VERSION ""

NS_ :

 BU_BO_REL_~SG_MUL_VAL_

BS_:

BU_: IAP ODS _4WD BCM HUD DATC MDPS AAF_Tester AEMC SMK _4WD EPB CUBIS MTS TMU EVP CGW TPMS LPI DI_BOX SPAS EMS LCA TCU IBOX FATC AFLS FPCM SCC AHLS AVM ABS SNV OPI PGS SAS AAF Dummy LDWS_LKAS LVR ESC PSB CLU ECS ACU REA CLOCK HUD H_U DATC CCP KMA_TMU CUBIS TMU IPM RSE_R RRC CGW RSE_L AMP EDT SWRC IBOX CLU FHCU ASD MON AVM KBD

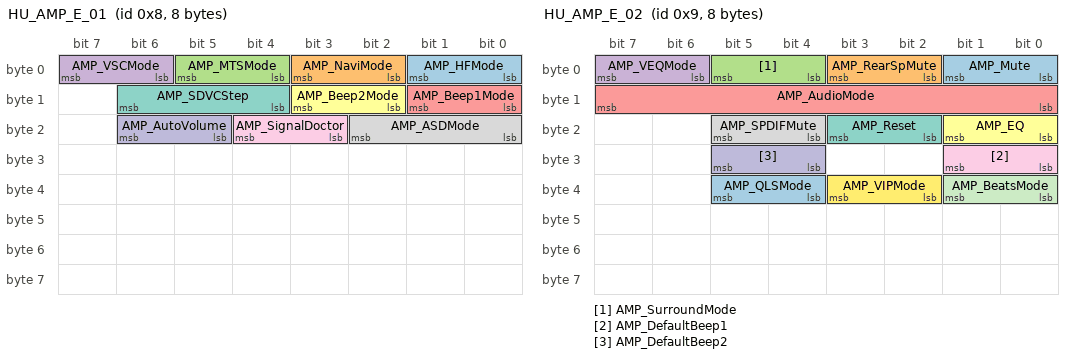
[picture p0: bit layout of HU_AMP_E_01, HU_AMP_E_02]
BO_ 8 HU_AMP_E_01: 8 H_U
   SG_ AMP_HFMode : 1|2@0+ (1,0) [0|0] ""  AMP
   SG_ AMP_NaviMode : 3|2@0+ (1,0) [0|0] ""  AMP
   SG_ AMP_MTSMode : 5|2@0+ (1,0) [0|0] ""  AMP
   SG_ AMP_VSCMode : 7|2@0+ (1,0) [0|0] ""  AMP
   SG_ AMP_Beep1Mode : 9|2@0+ (1,0) [0|0] ""  AMP
   SG_ AMP_Beep2Mode : 11|2@0+ (1,0) [0|0] ""  AMP
   SG_ AMP_SDVCStep : 14|3@0+ (1,0) [0|0] ""  AMP
   SG_ AMP_ASDMode : 18|3@0+ (1,0) [0|0] ""  AMP
   SG_ AMP_SignalDoctor : 20|2@0+ (1,0) [0|0] ""  AMP
   SG_ AMP_AutoVolume : 22|2@0+ (1,0) [0|0] ""  AMP

BO_ 9 HU_AMP_E_02: 8 H_U
   SG_ AMP_Mute : 1|2@0+ (1,0) [0|0] ""  AMP
   SG_ AMP_RearSpMute : 3|2@0+ (1,0) [0|0] ""  AMP
   SG_ AMP_SurroundMode : 5|2@0+ (1,0) [0|0] ""  AMP
   SG_ AMP_VEQMode : 7|2@0+ (1,0) [0|0] ""  AMP
   SG_ AMP_AudioMode : 15|8@0+ (1,0) [0|0] ""  AMP
   SG_ AMP_EQ : 17|2@0+ (1,0) [0|0] ""  AMP
   SG_ AMP_Reset : 19|2@0+ (1,0) [0|0] ""  AMP
   SG_ AMP_SPDIFMute : 21|2@0+ (1,0) [0|0] ""  AMP
   SG_ AMP_DefaultBeep1 : 25|2@0+ (1,0) [0|0] ""  AMP
   SG_ AMP_DefaultBeep2 : 29|2@0+ (1,0) [0|0] ""  AMP
   SG_ AMP_BeatsMode : 33|2@0+ (1,0) [0|0] ""  AMP
   SG_ AMP_VIPMode : 35|2@0+ (1,0) [0|0] ""  AMP
   SG_ AMP_QLSMode : 37|2@0+ (1,0) [0|0] ""  AMP

BO_ 10 HU_AMP_E_03: 8 H_U
   SG_ AMP_CrtVehicleID : 7|8@0+ (1,0) [0|0] ""  AMP
   SG_ AMP_SPDIFMode : 11|4@0+ (1,0) [0|0] ""  AMP
   SG_ AMP_VersionReq : 17|2@0+ (1,0) [0|0] ""  AMP
   SG_ AMP_UpdateStart : 25|2@0+ (1,0) [0|0] ""  AMP
   SG_ AMP_UpdateEnd : 33|2@0+ (1,0) [0|0] ""  AMP

BO_ 11 HU_AMP_E_04: 8 H_U
   SG_ AMP_Drive : 1|2@0+ (1,0) [0|0] ""  AMP
   SG_ AMP_ConvertibleTop : 5|2@0+ (1,0) [0|0] ""  AMP

BO_ 12 HU_AMP_E_05: 8 H_U
   SG_ AMP_NaviVolumeStep : 7|8@0+ (1,0) [0|0] ""  AMP
   SG_ AMP_NaviMainAudioCut : 15|8@0+ (1,0) [0|0] ""  AMP
   SG_ AMP_NaviChannelOutputMask : 23|16@0+ (1,0) [0|0] ""  AMP
   SG_ AMP_NaviChannelMuteMask : 39|16@0+ (1,0) [0|0] ""  AMP

BO_ 13 HU_AMP_E_06: 8 H_U
   SG_ AMP_MTSVolumeStep : 7|8@0+ (1,0) [0|0] ""  AMP
   SG_ AMP_MTSMainAudioCut : 15|8@0+ (1,0) [0|0] ""  AMP
   SG_ AMP_MTSChannelOutputMask : 23|16@0+ (1,0) [0|0] ""  AMP
   SG_ AMP_MTSChannelMuteMask : 39|16@0+ (1,0) [0|0] ""  AMP

BO_ 14 HU_AMP_E_07: 8 H_U
   SG_ AMP_HFVolumeStep : 7|8@0+ (1,0) [0|0] ""  AMP
   SG_ AMP_HFMainAudioCut : 15|8@0+ (1,0) [0|0] ""  AMP
   SG_ AMP_HFChannelOutputMask : 23|16@0+ (1,0) [0|0] ""  AMP
   SG_ AMP_HFChannelMuteMask : 39|16@0+ (1,0) [0|0] ""  AMP

BO_ 15 HU_AMP_E_08: 8 H_U
   SG_ AMP_MainVolumeSet : 7|8@0+ (1,0) [0|0] ""  AMP
   SG_ AMP_BalanceSet : 15|8@0+ (1,0) [0|0] ""  AMP
   SG_ AMP_FadeSet : 23|8@0+ (1,0) [0|0] ""  AMP
   SG_ AMP_BassSet : 31|8@0+ (1,0) [0|0] ""  AMP
   SG_ AMP_MidSet : 39|8@0+ (1,0) [0|0] ""  AMP
   SG_ AMP_TrebleSet : 47|8@0+ (1,0) [0|0] ""  AMP

BO_ 16 ACU13: 8 ACU
   SG_ CF_Acu_CshAct : 0|1@1+ (1.0,0.0) [0.0|1.0] ""  CUBIS,IBOX,ODS

BO_ 17 HU_AMP_E_10: 8 H_U
   SG_ AMP_Beep2VolumeStep : 7|8@0+ (1,0) [0|0] ""  AMP
   SG_ AMP_Beep2Frequency : 15|16@0+ (1,0) [0|0] ""  AMP
   SG_ AMP_Beep2Ch_OutputMask : 31|16@0+ (1,0) [0|0] ""  AMP
   SG_ AMP_Beep2DurationOn : 47|8@0+ (1,0) [0|0] ""  AMP
   SG_ AMP_Beep2DurationOff : 55|8@0+ (1,0) [0|0] ""  AMP
   SG_ AMP_Beep2NumberOfCycles : 63|8@0+ (1,0) [0|0] ""  AMP

BO_ 23 HU_IPM_E_00: 8 H_U
   SG_ C_ADrLNValueSet : 2|3@0+ (1,0) [0|0] ""  DATC,IPM
   SG_ C_ADrUNValueSet : 5|3@0+ (1,0) [0|0] ""  DATC,IPM
   SG_ SYS_Ver_Req : 7|2@0+ (1,0) [0|0] ""  AMP,AVM,CLU,CUBIS,DATC,IPM
   SG_ C_IMSRValueReq : 9|2@0+ (1,0) [0|0] ""  DATC,IPM
   SG_ C_PSMNValueSet : 11|2@0+ (1,0) [0|0] ""  DATC,IPM
   SG_ C_SCMNValueSet : 13|2@0+ (1,0) [0|0] ""  DATC,IPM
   SG_ C_ADrLURValueReq : 15|2@0+ (1,0) [0|0] ""  DATC,IPM
   SG_ C_ABuzzerNValueSet : 17|2@0+ (1,0) [0|0] ""  DATC,IPM
   SG_ C_AlarmRValueReq : 19|2@0+ (1,0) [0|0] ""  DATC,IPM
   SG_ C_ArmWKeyNValueSet : 21|2@0+ (1,0) [0|0] ""  DATC,IPM
   SG_ C_TwUnRValueReq : 23|2@0+ (1,0) [0|0] ""  DATC,IPM
   SG_ C_TwUnNValueSet : 25|2@0+ (1,0) [0|0] ""  DATC,IPM
   SG_ C_AutoMRFoldRValueReq : 27|2@0+ (1,0) [0|0] ""  DATC,IPM
   SG_ C_AutoMRFoldNValueSet : 29|2@0+ (1,0) [0|0] ""  DATC,IPM
   SG_ C_ADrLRValueReq : 31|2@0+ (1,0) [0|0] ""  DATC,IPM
   SG_ C_ArmWKeyRValueReq : 33|2@0+ (1,0) [0|0] ""  DATC,IPM
   SG_ C_ABuzzerRValueReq : 35|2@0+ (1,0) [0|0] ""  DATC,IPM
   SG_ C_ADrURValueReq : 37|2@0+ (1,0) [0|0] ""  DATC,IPM
   SG_ C_PSMRValueReq : 39|2@0+ (1,0) [0|0] ""  DATC,IPM
   SG_ C_SCMRValueReq : 47|2@0+ (1,0) [0|0] ""  DATC,IPM

BO_ 27 AMP_HU_E_00: 8 AMP
   SG_ SYS_AMPVer : 7|16@0+ (1,0) [0|0] ""  H_U

BO_ 29 CLU_HU_E_00: 8 CLU
   SG_ SYS_CLUVer : 7|16@0+ (1,0) [0|0] ""  CUBIS,H_U
   SG_ CLU_ClockInfoReq : 17|2@0+ (1,0) [0|0] ""  H_U
   SG_ CLU_DateInfoReq : 19|2@0+ (1,0) [0|0] ""  H_U

BO_ 48 EMS18: 6 EMS
   SG_ CF_Ems_DC1NumPerMSV : 0|8@1+ (1.0,0.0) [0.0|255.0] ""  DI_BOX
   SG_ CF_Ems_DC2NumPerMSV : 8|16@1+ (1.0,0.0) [0.0|65535.0] ""  DI_BOX
   SG_ CR_Ems_DutyCyc1MSV : 24|8@1+ (0.1953,0.0) [0.0|49.8] "%"  DI_BOX
   SG_ CR_Ems_DutyCyc2MSV : 32|8@1+ (0.13725,0.0) [0.0|35.0] "%"  DI_BOX
   SG_ CR_Ems_DutyCyc3MSV : 40|8@1+ (0.392,0.0) [0.0|100.0] "%"  DI_BOX

BO_ 52 HU_DATC_E_02: 8 H_U
   SG_ HU_DATC_DrTempUpDn : 1|2@0+ (1,0) [0|0] ""  CGW,CLU,DATC,IPM
   SG_ HU_DATC_PsTempUpDn : 3|2@0+ (1,0) [0|0] ""  CGW,CLU,DATC,IPM
   SG_ HU_DATC_RlTempUpDn : 5|2@0+ (1,0) [0|0] ""  CGW,CLU,DATC,IPM
   SG_ HU_DATC_RrTempUpDn : 7|2@0+ (1,0) [0|0] ""  CGW,CLU,DATC,IPM
   SG_ HU_DATC_MainBlower : 11|4@0+ (1,0) [0|0] ""  CGW,CLU,DATC,IPM
   SG_ HU_DATC_SubBlower : 15|4@0+ (1,0) [0|0] ""  CGW,CLU,DATC,IPM
   SG_ HU_DATC_RearBlower : 19|4@0+ (1,0) [0|0] ""  CGW,CLU,DATC,IPM
   SG_ HU_DATCRearPsModeSet : 23|4@0+ (1,0) [0|0] ""  CGW,CLU
   SG_ HU_DATC_FrontModeSet : 27|4@0+ (1,0) [0|0] ""  CGW,CLU,DATC,IPM
   SG_ HU_DATC_RearModeSet : 31|4@0+ (1,0) [0|0] ""  CGW,CLU,DATC,IPM
   SG_ HU_DATC_AutoSet : 33|2@0+ (1,0) [0|0] ""  CGW,CLU,DATC,IPM
   SG_ HU_DATC_OffReq : 35|2@0+ (1,0) [0|0] ""  CGW,CLU,DATC,IPM
   SG_ HU_DATC_IntakeSet : 37|2@0+ (1,0) [0|0] ""  CGW,CLU,DATC,IPM
   SG_ HU_DATC_RearOnOffSet : 39|2@0+ (1,0) [0|0] ""  CGW,CLU,DATC,IPM
   SG_ HU_DATC_AcSet : 41|2@0+ (1,0) [0|0] ""  CGW,CLU,DATC,IPM
   SG_ HU_DATC_AqsSet : 43|2@0+ (1,0) [0|0] ""  CGW,CLU,DATC,IPM
   SG_ HU_DATC_FrontDefog : 45|2@0+ (1,0) [0|0] ""  CGW,CLU,DATC,IPM
   SG_ HU_DATC_RearDefog : 47|2@0+ (1,0) [0|0] ""  CGW,CLU,DATC,IPM
   SG_ HU_DATC_ZoneControl : 49|2@0+ (1,0) [0|0] ""  CGW,CLU,DATC,IPM
   SG_ HU_DATC_CO2Set : 51|2@0+ (1,0) [0|0] ""  CGW,CLU,DATC,IPM
   SG_ DATC_SmartVentOnOffSet : 53|2@0+ (1,0) [0|0] ""  CGW,CLU,DATC,IPM
   SG_ DATC_ADSOnOffSet : 55|2@0+ (1,0) [0|0] ""  CGW,CLU
   SG_ HU_DATC_RearAutoDisp : 57|2@0+ (1,0) [0|0] ""  CGW,CLU
   SG_ HU_DATC_RearOffDisp : 59|2@0+ (1,0) [0|0] ""  CGW,CLU

BO_ 62 HU_Navi_E_00: 8 H_U
   SG_ Navi_SLIF_SpdUnit : 1|2@0+ (1,0) [0|0] ""  CGW,CLU,HUD
   SG_ Navi_SLIF_Frwinfo : 4|3@0+ (1,0) [0|0] ""  CGW,CLU,HUD
   SG_ Navi_SLIF_LinkClass : 7|3@0+ (1,0) [0|0] ""  CGW,CLU,HUD
   SG_ Navi_SLIF_SpdLimit : 15|8@0+ (1,0) [1|254] ""  CGW,CLU,HUD
   SG_ Navi_SLIFMapSource : 29|4@0+ (1,0) [0|8] ""  CGW,CLU,HUD
   SG_ Navi_SLIF_CountryCode : 23|10@0+ (1,0) [0|0] ""  CGW,CLU,HUD

BO_ 64 TMU_HU_E_01: 8 TMU
   SG_ TMU_DisMode : 3|4@0+ (1,0) [0|0] ""  H_U
   SG_ TMU_AudSrcType : 7|4@0+ (1,0) [0|0] ""  CLU,DATC,H_U
   SG_ TMU_AudReqCmd : 9|2@0+ (1,0) [0|0] ""  H_U
   SG_ TMU_LangCmd : 12|3@0+ (1,0) [0|0] ""  H_U
   SG_ TMU_ServReq : 15|3@0+ (1,0) [0|0] ""  H_U
   SG_ TMU_ErrorEvent : 23|8@0+ (1,0) [0|0] ""  H_U
   SG_ TMU_BeepCmd : 25|2@0+ (1,0) [0|0] ""  H_U
   SG_ TMU_eCall : 28|3@0+ (1,0) [0|0] ""  H_U

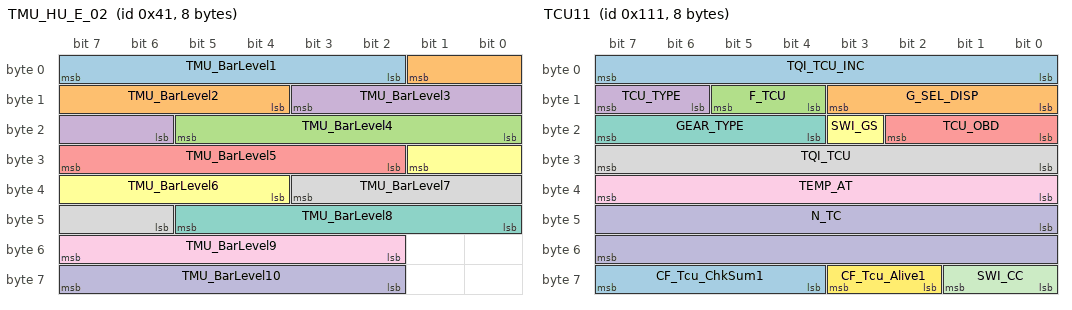
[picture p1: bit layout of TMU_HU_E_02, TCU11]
BO_ 65 TMU_HU_E_02: 8 TMU
   SG_ TMU_BarLevel1 : 7|6@0+ (1,0) [0|0] ""  H_U
   SG_ TMU_BarLevel2 : 1|6@0+ (1,0) [0|0] ""  H_U
   SG_ TMU_BarLevel4 : 21|6@0+ (1,0) [0|0] ""  H_U
   SG_ TMU_BarLevel3 : 11|6@0+ (1,0) [0|0] ""  H_U
   SG_ TMU_BarLevel5 : 31|6@0+ (1,0) [0|0] ""  H_U
   SG_ TMU_BarLevel6 : 25|6@0+ (1,0) [0|0] ""  H_U
   SG_ TMU_BarLevel8 : 45|6@0+ (1,0) [0|0] ""  H_U
   SG_ TMU_BarLevel7 : 35|6@0+ (1,0) [0|0] ""  H_U
   SG_ TMU_BarLevel9 : 55|6@0+ (1,0) [0|0] ""  H_U
   SG_ TMU_BarLevel10 : 63|6@0+ (1,0) [0|0] ""  H_U

BO_ 66 DATC12: 8 DATC
   SG_ CR_Datc_DrTempDispC : 0|8@1+ (0.5,14.0) [15.0|32.0] "deg"  CLU,IBOX
   SG_ CR_Datc_DrTempDispF : 8|8@1+ (1.0,56.0) [58.0|90.0] "deg"  CLU,IBOX
   SG_ CR_Datc_PsTempDispC : 16|8@1+ (0.5,14.0) [15.0|32.0] "deg"  CLU,IBOX
   SG_ CR_Datc_PsTempDispF : 24|8@1+ (1.0,56.0) [58.0|90.0] "deg"  CLU,IBOX
   SG_ CR_Datc_RearDrTempDispC : 40|8@1+ (0.5,14.0) [15.0|32.0] "deg"  CLU
   SG_ CR_Datc_RearDrTempDispF : 48|8@1+ (1.0,58.0) [58.0|90.0] "deg"  CLU
   SG_ CF_Datc_CO2_Warning : 56|8@1+ (1.0,0.0) [0.0|3.0] ""  CLU

BO_ 67 DATC13: 8 DATC
   SG_ CF_Datc_TempDispUnit : 0|2@1+ (1.0,0.0) [0.0|3.0] ""  CLU,IBOX
   SG_ CF_Datc_ModDisp : 2|4@1+ (1.0,0.0) [0.0|15.0] ""  CLU
   SG_ CF_Datc_IonClean : 6|2@1+ (1.0,0.0) [0.0|3.0] ""  CLU
   SG_ CF_Datc_ChgReqDisp : 8|2@1+ (1.0,0.0) [0.0|3.0] ""  CLU
   SG_ CF_Datc_IntakeDisp : 10|2@1+ (1.0,0.0) [0.0|3.0] ""  CLU
   SG_ CF_Datc_AutoDisp : 12|2@1+ (1.0,0.0) [0.0|3.0] ""  CLU
   SG_ CF_Datc_FrDefLed : 14|2@1+ (1.0,0.0) [0.0|3.0] ""  CLU,IBOX
   SG_ CF_Datc_AutoDefogBlink : 16|2@1+ (1.0,0.0) [0.0|3.0] ""  CLU
   SG_ CF_Datc_ClmScanDisp : 18|2@1+ (1.0,0.0) [0.0|3.0] ""  CLU
   SG_ CF_Datc_AqsDisp : 20|2@1+ (1.0,0.0) [0.0|3.0] ""  CLU
   SG_ CF_Datc_AcDisp : 22|2@1+ (1.0,0.0) [0.0|3.0] ""  CLU
   SG_ CF_Datc_OpSts : 25|3@1+ (1.0,0.0) [0.0|7.0] ""  CLU
   SG_ CF_Mtc_MaxAcDisp : 28|2@1+ (1.0,0.0) [0.0|3.0] ""  CLU
   SG_ CF_Datc_DualDisp : 30|2@1+ (1.0,0.0) [0.0|3.0] ""  CLU
   SG_ CF_Datc_PwrInf : 32|4@1+ (1.0,0.0) [0.0|15.0] ""  CLU
   SG_ CF_Datc_RearManual : 38|2@1+ (1.0,0.0) [0.0|3.0] ""  CLU
   SG_ CF_Datc_RearAutoDisp : 40|2@1+ (1.0,0.0) [0.0|1.0] ""  CLU
   SG_ CF_Datc_RearOffDisp : 42|2@1+ (1.0,0.0) [0.0|3.0] ""  CLU
   SG_ CF_Datc_RearClimateScnDisp : 44|2@1+ (1.0,0.0) [0.0|3.0] ""  CLU
   SG_ CF_Datc_RearChgReqDisp : 46|2@1+ (1.0,0.0) [0.0|3.0] ""  CLU
   SG_ CF_Datc_RearModDisp : 48|4@1+ (1.0,0.0) [0.0|15.0] ""  CLU
   SG_ CF_Datc_RearBlwDisp : 52|4@1+ (1.0,0.0) [0.0|15.0] ""  CLU
   SG_ CF_Datc_PSModDisp : 56|4@1+ (1.0,0.0) [0.0|15.0] ""  CLU
   SG_ CF_Datc_FrontBlwDisp : 60|4@1+ (1.0,0.0) [0.0|15.0] ""  CLU,IBOX

BO_ 68 DATC11: 8 DATC
   SG_ CF_Datc_Type : 0|8@1+ (1.0,0.0) [0.0|255.0] ""  CLU
   SG_ CF_Datc_VerMaj : 8|8@1+ (1.0,0.0) [0.0|255.0] ""  CLU
   SG_ CF_Datc_VerMin : 16|8@1+ (1.0,0.0) [0.0|255.0] ""  CLU
   SG_ CR_Datc_OutTempC : 24|8@1+ (0.5,-41.0) [-41.0|86.5] "deg"  CLU,FPCM
   SG_ CR_Datc_OutTempF : 32|8@1+ (1.0,-42.0) [-42.0|213.0] "deg"  CLU
   SG_ CF_Datc_IncarTemp : 40|8@1+ (0.5,-40.0) [-40.0|60.0] "deg"  BCM,CLU

BO_ 69 TMU_HU_E_04: 8 TMU
   SG_ TMU_eCall : 1|2@0+ (1,0) [0|0] ""  H_U

BO_ 74 HU_AMP_E_11: 8 H_U
   SG_ AMP_PESSMode : 1|2@0+ (1,0) [0|0] ""  AMP
   SG_ AMP_PESSDesignSet : 4|3@0+ (1,0) [0|0] ""  AMP
   SG_ AMP_PESSAPSSet : 7|3@0+ (1,0) [0|0] ""  AMP
   SG_ AMP_PESSVolumeSet : 15|8@0+ (1,0) [0|0] ""  AMP

BO_ 75 HU_AMP_E_12: 8 H_U
   SG_ AMP_EngOrderC2GainSet : 7|8@0+ (1,0) [0|0] ""  AMP
   SG_ AMP_EngOrderC4GainSet : 15|8@0+ (1,0) [0|0] ""  AMP
   SG_ AMP_EngOrderC6GainSet : 23|8@0+ (1,0) [0|0] ""  AMP
   SG_ AMP_APSBand0GainSet : 31|8@0+ (1,0) [0|0] ""  AMP
   SG_ AMP_APSBand1GainSet : 39|8@0+ (1,0) [0|0] ""  AMP
   SG_ AMP_APSBand2GainSet : 47|8@0+ (1,0) [0|0] ""  AMP
   SG_ AMP_APSBand3GainSet : 55|8@0+ (1,0) [0|0] ""  AMP
   SG_ AMP_APSBand4GainSet : 63|8@0+ (1,0) [0|0] ""  AMP

BO_ 87 HU_E_02: 8 H_U
   SG_ NaviValidity : 1|2@0+ (1,0) [0|0] ""  CGW,CLU

BO_ 93 DATC_HU_E_SYS: 8 CLU
   SG_ DATC_SWVerMajor : 7|8@0+ (1,0) [0|254] ""  H_U
   SG_ DATC_SWVerMinor : 15|8@0+ (1,0) [0|254] ""  H_U
   SG_ DATC_CANVerMajor : 23|8@0+ (1,0) [0|254] ""  H_U
   SG_ DATC_CANVerMinor : 31|8@0+ (1,0) [0|254] ""  H_U

BO_ 112 HU_AMP_E_09: 8 H_U
   SG_ AMP_Beep1VolumeStep : 7|8@0+ (1,0) [0|0] ""  AMP
   SG_ AMP_Beep1Frequency : 15|16@0+ (1,0) [0|0] ""  AMP
   SG_ AMP_Beep1Ch_OutputMask : 31|16@0+ (1,0) [0|0] ""  AMP
   SG_ AMP_Beep1DurationOn : 47|8@0+ (1,0) [0|0] ""  AMP
   SG_ AMP_Beep1DurationOff : 55|8@0+ (1,0) [0|0] ""  AMP
   SG_ AMP_Beep1NumberOfCycles : 63|8@0+ (1,0) [0|0] ""  AMP

BO_ 127 CGW5: 8 BCM
   SG_ C_StopLampLhOpenSts : 0|1@1+ (1.0,0.0) [0.0|1.0] ""  CLU
   SG_ C_StopLampRhOpenSts : 1|1@1+ (1.0,0.0) [0.0|1.0] ""  CLU
   SG_ C_HMSLOpenSts : 2|1@1+ (1.0,0.0) [0.0|1.0] ""  CLU
   SG_ C_HLampLowLhOpenSts : 3|1@1+ (1.0,0.0) [0.0|1.0] ""  CLU
   SG_ C_HLampLowRhOpenSts : 4|1@1+ (1.0,0.0) [0.0|1.0] ""  CLU
   SG_ C_HLampHighLhOpenSts : 5|1@1+ (1.0,0.0) [0.0|1.0] ""  CLU
   SG_ C_HLampHighRhOpenSts : 6|1@1+ (1.0,0.0) [0.0|1.0] ""  CLU
   SG_ C_DRLLampLhOpenSts : 7|1@1+ (1.0,0.0) [0.0|1.0] ""  CLU
   SG_ C_DRLLampRhOpenSts : 8|1@1+ (1.0,0.0) [0.0|1.0] ""  CLU
   SG_ C_RearFOGLhOpenSts : 9|1@1+ (1.0,0.0) [0.0|1.0] ""  CLU
   SG_ C_RearFOGRhOpenSts : 10|1@1+ (1.0,0.0) [0.0|1.0] ""  CLU
   SG_ C_FrontFOGLhOpenSts : 11|1@1+ (1.0,0.0) [0.0|1.0] ""  CLU
   SG_ C_FrontFOGRhOpenSts : 12|1@1+ (1.0,0.0) [0.0|1.0] ""  CLU
   SG_ C_RearEXTTailLhOpenSts : 13|1@1+ (1.0,0.0) [0.0|1.0] ""  CLU
   SG_ C_RearEXTTailRhOpenSts : 14|1@1+ (1.0,0.0) [0.0|1.0] ""  CLU
   SG_ C_FrontEXTTailLhOpenSts : 15|1@1+ (1.0,0.0) [0.0|1.0] ""  CLU
   SG_ C_FrontEXTTailRhOpenSts : 16|1@1+ (1.0,0.0) [0.0|1.0] ""  CLU
   SG_ C_RearTSIGLhOpenSts : 17|1@1+ (1.0,0.0) [0.0|1.0] ""  CLU
   SG_ C_RearTSIGRhOpenSts : 18|1@1+ (1.0,0.0) [0.0|1.0] ""  CLU
   SG_ C_FrontTSIGLhOpenSts : 19|1@1+ (1.0,0.0) [0.0|1.0] ""  CLU
   SG_ C_FrontTSIGRhOpenSts : 20|1@1+ (1.0,0.0) [0.0|1.0] ""  CLU
   SG_ C_SBendingLhOpenSts : 21|1@1+ (1.0,0.0) [0.0|1.0] ""  CLU
   SG_ C_SBendingRhOpenSts : 22|1@1+ (1.0,0.0) [0.0|1.0] ""  CLU
   SG_ C_LicensePlateLhOpenSts : 23|1@1+ (1.0,0.0) [0.0|1.0] ""  CLU
   SG_ C_LicensePlateRhOpenSts : 24|1@1+ (1.0,0.0) [0.0|1.0] ""  CLU

BO_ 128 EMS_DCT11: 8 EMS
   SG_ PV_AV_CAN : 0|8@1+ (0.3906,0.0) [0.0|99.603] "%"  TCU
   SG_ TQ_STND : 8|6@1+ (10.0,0.0) [0.0|630.0] "Nm"  TCU
   SG_ F_N_ENG : 14|1@1+ (1.0,0.0) [0.0|1.0] ""  TCU
   SG_ F_SUB_TQI : 15|1@1+ (1.0,0.0) [0.0|1.0] ""  TCU
   SG_ N : 16|16@1+ (0.25,0.0) [0.0|16383.75] "rpm"  TCU
   SG_ TQI_ACOR : 32|8@1+ (0.390625,0.0) [0.0|99.6094] "%"  IBOX,TCU
   SG_ TQFR : 40|8@1+ (0.390625,0.0) [0.0|99.6094] "%"  TCU
   SG_ TQI : 48|8@1+ (0.390625,0.0) [0.0|99.609375] "%"  TCU
   SG_ CF_Ems_Alive : 56|4@1+ (1.0,0.0) [0.0|15.0] ""  TCU
   SG_ CF_Ems_ChkSum : 60|4@1+ (1.0,0.0) [0.0|15.0] ""  TCU

BO_ 129 AMP_HU_E_02: 8 AMP
   SG_ AMP_DriveState : 1|2@0+ (1,0) [0|0] ""  H_U
   SG_ AMP_ConvertibleTopState : 5|2@0+ (1,0) [0|0] ""  H_U

BO_ 129 EMS_DCT2: 8 XXX
   SG_ CR_Ems_SoakTimeExt : 0|6@1+ (5,0) [0|315] "Min" XXX
   SG_ BRAKE_ACT : 6|2@1+ (1,0) [0|3] "" XXX
   SG_ CF_Ems_EngOperStat : 8|8@1+ (1,0) [0|255] "" XXX
   SG_ CR_Ems_IndAirTemp : 16|8@1+ (0.75,-48) [-48|143.25] "" XXX
   SG_ CF_Ems_Alive2 : 56|4@1+ (1,0) [0|15] "" XXX
   SG_ CF_Ems_ChkSum2 : 60|4@1+ (1,0) [0|15] "" XXX

BO_ 129 EMS_DCT12: 8 EMS
   SG_ CR_Ems_SoakTimeExt : 0|6@1+ (5.0,0.0) [0.0|315.0] "Min"  TCU
   SG_ BRAKE_ACT : 6|2@1+ (1.0,0.0) [0.0|3.0] ""  TCU
   SG_ CF_Ems_EngOperStat : 8|8@1+ (1.0,0.0) [0.0|255.0] ""  TCU
   SG_ CR_Ems_IndAirTemp : 16|8@1+ (0.75,-48.0) [-48.0|143.25] "deg"  TCU
   SG_ CF_Ems_Alive2 : 56|4@1+ (1.0,0.0) [0.0|15.0] ""  TCU
   SG_ CF_Ems_ChkSum2 : 60|4@1+ (1.0,0.0) [0.0|15.0] ""  TCU

BO_ 130 AMP_HU_E_03: 8 AMP
   SG_ AMP_NaviVolumeState : 7|8@0+ (1,0) [0|0] ""  H_U
   SG_ AMP_NaviAudioCutState : 15|8@0+ (1,0) [0|0] ""  H_U
   SG_ AMP_NaviOutputMaskState : 23|16@0+ (1,0) [0|0] ""  H_U
   SG_ AMP_NaviMuteMaskState : 39|16@0+ (1,0) [0|0] ""  H_U
   SG_ AMP_MaxNaviVolumeState : 55|8@0+ (1,0) [0|0] ""  H_U
   SG_ AMP_MaxNaviAudioCutState : 63|8@0+ (1,0) [0|0] ""  H_U

BO_ 131 AMP_HU_E_04: 8 AMP
   SG_ AMP_MTSVolumeState : 7|8@0+ (1,0) [0|0] ""  H_U
   SG_ AMP_MTSAudioCutState : 15|8@0+ (1,0) [0|0] ""  H_U
   SG_ AMP_MTSOutputMaskState : 23|16@0+ (1,0) [0|0] ""  H_U
   SG_ AMP_MTSMuteMaskState : 39|16@0+ (1,0) [0|0] ""  H_U
   SG_ AMP_MaxMTSVolumeState : 55|8@0+ (1,0) [0|0] ""  H_U
   SG_ AMP_MaxMTSAudioCutState : 63|8@0+ (1,0) [0|0] ""  H_U

BO_ 132 AMP_HU_E_05: 8 AMP
   SG_ AMP_HFVolumeState : 7|8@0+ (1,0) [0|0] ""  H_U
   SG_ AMP_HFAudioCutState : 15|8@0+ (1,0) [0|0] ""  H_U
   SG_ AMP_HFOutputMaskState : 23|16@0+ (1,0) [0|0] ""  H_U
   SG_ AMP_HFMuteMaskState : 39|16@0+ (1,0) [0|0] ""  H_U
   SG_ AMP_MaxHFVolumeState : 55|8@0+ (1,0) [0|0] ""  H_U
   SG_ AMP_MaxHFAudioCutState : 63|8@0+ (1,0) [0|0] ""  H_U

BO_ 133 AMP_HU_E_06: 8 AMP
   SG_ AMP_MaxVolumeStep : 7|8@0+ (1,0) [0|0] ""  H_U
   SG_ AMP_MaxBalanceStep : 15|8@0+ (1,0) [0|0] ""  H_U
   SG_ AMP_MaxFadeStep : 23|8@0+ (1,0) [0|0] ""  H_U
   SG_ AMP_MaxBassStep : 31|8@0+ (1,0) [0|0] ""  H_U
   SG_ AMP_MaxMidStep : 39|8@0+ (1,0) [0|0] ""  H_U
   SG_ AMP_MaxTrebleStep : 47|8@0+ (1,0) [0|0] ""  H_U
   SG_ AMP_ASDMajorVer : 55|8@0+ (1,0) [0|0] ""  H_U
   SG_ AMP_ASDMinorVer : 63|8@0+ (1,0) [0|0] ""  H_U

BO_ 134 AMP_HU_E_07: 8 AMP
   SG_ ASD_SetValue : 2|3@0+ (1,0) [0|0] ""  H_U,IBOX
   SG_ ASD_Version : 15|8@0+ (1,0) [0|0] ""  H_U,IBOX

BO_ 135 AMP_HU_E_08: 8 AMP
   SG_ AMP_MaxBeep1VolumeState : 7|8@0+ (1,0) [0|0] ""  H_U
   SG_ AMP_MaxBeep1Freq_State : 15|16@0+ (1,0) [0|0] ""  H_U
   SG_ AMP_Beep1OutputMaskSup : 33|2@0+ (1,0) [0|0] ""  H_U
   SG_ AMP_MaxBeep1DOnState : 47|8@0+ (1,0) [0|0] ""  H_U
   SG_ AMP_MaxBeep1DOffState : 55|8@0+ (1,0) [0|0] ""  H_U
   SG_ AMP_MaxBeep1NOfCycleState : 63|8@0+ (1,0) [0|0] ""  H_U

BO_ 136 AMP_HU_E_09: 8 AMP
   SG_ AMP_MaxBeep2VolumeState : 7|8@0+ (1,0) [0|0] ""  H_U
   SG_ AMP_MaxBeep2Freq_State : 15|16@0+ (1,0) [0|0] ""  H_U
   SG_ AMP_Beep2OutputMaskSup : 33|2@0+ (1,0) [0|0] ""  H_U
   SG_ AMP_MaxBeep2DOnState : 47|8@0+ (1,0) [0|0] ""  H_U
   SG_ AMP_MaxBeep2DOffState : 55|8@0+ (1,0) [0|0] ""  H_U
   SG_ AMP_MaxBeep2NOfCycleState : 63|8@0+ (1,0) [0|0] ""  H_U

BO_ 137 AMP_HU_E_10: 8 AMP
   SG_ AMP_MTSOutputMaskSupport : 1|2@0+ (1,0) [0|0] ""  H_U
   SG_ AMP_MTSMuteMaskSupport : 5|2@0+ (1,0) [0|0] ""  H_U
   SG_ AMP_HFOutputMaskSupport : 9|2@0+ (1,0) [0|0] ""  H_U
   SG_ AMP_HFMuteMaskSupport : 13|2@0+ (1,0) [0|0] ""  H_U
   SG_ AMP_NaviOutputMaskSupport : 17|2@0+ (1,0) [0|0] ""  H_U
   SG_ AMP_NaviMuteMaskSupport : 21|2@0+ (1,0) [0|0] ""  H_U

BO_ 138 AMP_HU_E_11: 8 AMP
   SG_ AMP_Beep1VolumeState : 7|8@0+ (1,0) [0|0] ""  H_U
   SG_ AMP_Beep1FrequencyState : 15|16@0+ (1,0) [0|0] ""  H_U
   SG_ AMP_Beep1OutputMaskState : 31|16@0+ (1,0) [0|0] ""  H_U
   SG_ AMP_Beep1DOnState : 47|8@0+ (1,0) [0|0] ""  H_U
   SG_ AMP_Beep1DOffState : 55|8@0+ (1,0) [0|0] ""  H_U
   SG_ AMP_Beep1NOfCycleState : 63|8@0+ (1,0) [0|0] ""  H_U

BO_ 139 AMP_HU_E_12: 8 AMP
   SG_ AMP_Beep2VolumeState : 7|8@0+ (1,0) [0|0] ""  H_U
   SG_ AMP_Beep2FrequencyState : 15|16@0+ (1,0) [0|0] ""  H_U
   SG_ AMP_Beep2OutputMaskState : 31|16@0+ (1,0) [0|0] ""  H_U
   SG_ AMP_Beep2DOnState : 47|8@0+ (1,0) [0|0] ""  H_U
   SG_ AMP_Beep2DOffState : 55|8@0+ (1,0) [0|0] ""  H_U
   SG_ AMP_Beep2NOfCycleState : 63|8@0+ (1,0) [0|0] ""  H_U

BO_ 160 EngFrzFrm1: 8 XXX
   SG_ PID_04h : 0|8@1+ (0.392157,0) [0|100] "%" XXX
   SG_ PID_05h : 8|8@1+ (1,-40) [-40|215] "" XXX
   SG_ PID_0Ch : 16|16@1+ (0.25,0) [0|16383.8] "rpm" XXX
   SG_ PID_0Dh : 32|8@1+ (1,0) [0|255] "km/h" XXX
   SG_ PID_11h : 40|8@1+ (0.392157,0) [0|100] "%" XXX
   SG_ PID_03h : 48|16@1+ (1,0) [0|65535] "" XXX

BO_ 161 EngFrzFrm2: 8 XXX
   SG_ PID_06h : 0|8@1+ (0.78125,-100) [-100|99.22] "%" XXX
   SG_ PID_07h : 8|8@1+ (0.78125,-100) [-100|99.22] "%" XXX
   SG_ PID_08h : 16|8@1+ (0.78125,-100) [-100|99.22] "%" XXX
   SG_ PID_09h : 24|8@1+ (0.78125,-100) [-100|99.22] "%" XXX
   SG_ PID_0Bh : 32|8@1+ (1,0) [0|255] "kPa" XXX
   SG_ PID_23h : 40|16@1+ (10,0) [0|655350] "kPa" XXX

BO_ 208 CLU_HU_E_SYS: 8 CLU
   SG_ CLU_SWVerMajor : 7|8@0+ (1,0) [0|254] ""  H_U
   SG_ CLU_SWVerMinor : 15|8@0+ (1,0) [0|254] ""  H_U
   SG_ CLU_CANVerMajor : 23|8@0+ (1,0) [0|254] ""  H_U
   SG_ CLU_CANVerMinor : 31|8@0+ (1,0) [0|254] ""  H_U
   SG_ CLU_HWVerMajor : 55|8@0+ (1,0) [0|254] ""  H_U
   SG_ CLU_HWVerMinor : 63|8@0+ (1,0) [0|254] ""  H_U

BO_ 214 AMP_HU_E_SYS: 8 AMP
   SG_ AMP_SWVerMajor : 7|8@0+ (1,0) [0|254] ""  H_U,IBOX
   SG_ AMP_SWVerMinor : 15|8@0+ (1,0) [0|254] ""  H_U,IBOX
   SG_ AMP_CANVerMajor : 23|8@0+ (1,0) [0|254] ""  H_U,IBOX
   SG_ AMP_CANVerMinor : 31|8@0+ (1,0) [0|254] ""  H_U,IBOX
   SG_ AMP_RBDResult : 34|3@0+ (1,0) [0|0] ""  H_U
   SG_ AMP_MOSTErrorDiagResult : 38|3@0+ (1,0) [0|0] ""  H_U
   SG_ AMP_HWVerMajor : 55|8@0+ (1,0) [0|254] ""  H_U,IBOX
   SG_ AMP_HWVerMinor : 63|8@0+ (1,0) [0|254] ""  H_U,IBOX

BO_ 229 HU_SYS_E_00: 8 H_U
   SG_ SYS_SW_Ver_Req : 1|2@0+ (1,0) [0|0] ""  AMP,CCP,CGW,CLOCK,CLU,HUD,IBOX,RRC,RSE_L
   SG_ SYS_CAN_Ver_Req : 3|2@0+ (1,0) [0|0] ""  AMP,CCP,CGW,CLOCK,CLU,HUD,IBOX,RRC,RSE_L
   SG_ SYS_HW_Ver_Req : 5|2@0+ (1,0) [0|0] ""  AMP,CCP,CGW,CLOCK,CLU,IBOX,RRC
   SG_ SYS_RBD_Req : 9|2@0+ (1,0) [0|0] ""  AMP,IBOX
   SG_ SYS_MOSTErrorDiag_Req : 11|2@0+ (1,0) [0|0] ""  AMP,IBOX
   SG_ SYS_Reset_Req : 17|2@0+ (1,0) [0|0] ""  AMP,IBOX

BO_ 250 HU_TMU_E_01: 8 H_U
   SG_ HU_VoiceRecCom : 2|3@0+ (1,0) [0|0] ""  TMU
   SG_ HU_LangChgCom : 5|3@0+ (1,0) [0|0] ""  TMU
   SG_ HU_CallEndCmd : 9|2@0+ (1,0) [0|0] ""  TMU
   SG_ HU_ServiceReqtID : 13|4@0+ (1,0) [0|0] ""  TMU
   SG_ HU_MicReqCmd : 15|2@0+ (1,0) [0|0] ""  TMU
   SG_ HU_SeviceAction : 18|3@0+ (1,0) [0|0] ""  TMU
   SG_ HU_eCallStatus : 20|2@0+ (1,0) [0|0] ""  TMU

BO_ 251 HU_TMU_E_02: 8 H_U
   SG_ HU_GPS_Year : 7|8@0+ (1,0) [0|0] ""  CUBIS,TMU
   SG_ HU_GPS_Month : 15|8@0+ (1,0) [0|0] ""  CUBIS,TMU
   SG_ HU_GPS_Day : 23|8@0+ (1,0) [0|0] ""  CUBIS,TMU
   SG_ HU_GPS_Hour : 31|8@0+ (1,0) [0|0] ""  CUBIS,TMU
   SG_ HU_GPS_Minute : 39|8@0+ (1,0) [0|0] ""  CUBIS,TMU
   SG_ HU_GPS_Second : 47|8@0+ (1,0) [0|0] ""  CUBIS,TMU

BO_ 256 HU_MON_PE_01: 8 H_U
   SG_ HU_Type : 7|8@0+ (1,0) [0|0] ""  AMP,CGW,CLU,HUD,KMA_TMU
   SG_ HU_VerMajor : 15|8@0+ (1,0) [0|0] ""  AMP,CLU,KMA_TMU,MON
   SG_ HU_VerMinor : 23|8@0+ (1,0) [0|0] ""  AMP,CLU,KMA_TMU,MON
   SG_ HU_DistributeInfo : 31|8@0+ (1,0) [0|0] ""  AMP,CGW,CLU,KMA_TMU,MON,RRC
   SG_ HU_SubVerMajor : 39|8@0+ (1,0) [0|0] ""  AMP,MON
   SG_ HU_SubVerMinor : 47|8@0+ (1,0) [0|0] ""  AMP,MON
   SG_ HU_SDARSVersion : 55|8@0+ (1,0) [0|0] ""  AMP,MON
   SG_ HU_AdasSupport : 58|3@0+ (1,0) [0|0] ""  CGW,CLU

BO_ 273 TCU11: 8 TCU
   SG_ TQI_TCU_INC : 0|8@1+ (0.390625,0.0) [0.0|99.609375] "%"  EMS,ESC,IBOX
   SG_ G_SEL_DISP : 8|4@1+ (1.0,0.0) [0.0|15.0] ""  _4WD,AFLS,AVM,BCM,CGW,CLU,CUBIS,ECS,EMS,EPB,ESC,IAP,IBOX,LCA,LDWS_LKAS,LVR,MDPS,PGS,SCC,SMK,SNV,SPAS,TPMS
   SG_ F_TCU : 12|2@1+ (1.0,0.0) [0.0|3.0] ""  EMS,ESC,IBOX
   SG_ TCU_TYPE : 14|2@1+ (1.0,0.0) [0.0|3.0] ""  _4WD,EMS,ESC,IBOX
   SG_ TCU_OBD : 16|3@1+ (1.0,0.0) [0.0|7.0] ""  EMS,ESC,IBOX
   SG_ SWI_GS : 19|1@1+ (1.0,0.0) [0.0|1.0] ""  _4WD,EMS,EPB,ESC,IBOX,SCC
   SG_ GEAR_TYPE : 20|4@1+ (1.0,0.0) [0.0|15.0] ""  _4WD,CLU,EMS,ESC,IBOX,SCC
   SG_ TQI_TCU : 24|8@1+ (0.390625,0.0) [0.0|99.609375] "%"  EMS,ESC,IBOX
   SG_ TEMP_AT : 32|8@1+ (1.0,-40.0) [-40.0|214.0] "deg"  AAF,CLU,CUBIS,EMS,ESC,IBOX
   SG_ N_TC : 40|16@1+ (0.25,0.0) [0.0|16383.5] "rpm"  _4WD,EMS,EPB,ESC,IBOX
   SG_ SWI_CC : 56|2@1+ (1.0,0.0) [0.0|3.0] ""  _4WD,CLU,EMS,ESC,IBOX
   SG_ CF_Tcu_Alive1 : 58|2@1+ (1.0,0.0) [0.0|3.0] ""  EMS,IBOX
   SG_ CF_Tcu_ChkSum1 : 60|4@1+ (1.0,0.0) [0.0|15.0] ""  EMS,IBOX

BO_ 274 TCU12: 8 TCU
   SG_ ETL_TCU : 0|8@1+ (2.0,0.0) [0.0|508.0] "Nm"  EMS,IBOX
   SG_ CUR_GR : 8|4@1+ (1.0,0.0) [0.0|15.0] ""  _4WD,EMS,ESC,IBOX,SCC,TPMS
   SG_ CF_Tcu_Alive : 12|2@1+ (1.0,0.0) [0.0|3.0] ""  EMS,ESC,IBOX,SCC
   SG_ CF_Tcu_ChkSum : 14|2@1+ (1.0,0.0) [0.0|3.0] ""  EMS,ESC,IBOX,SCC
   SG_ VS_TCU : 16|8@1+ (1.0,0.0) [0.0|254.0] "km/h"  BCM,CLU,DATC,EMS,IBOX,LCA,LVR,PGS,SMK,SNV
   SG_ FUEL_CUT_TCU : 28|1@1+ (1.0,0.0) [0.0|1.0] ""  EMS,IBOX
   SG_ INH_FUEL_CUT : 29|1@1+ (1.0,0.0) [0.0|1.0] ""  EMS,IBOX
   SG_ IDLE_UP_TCU : 30|1@1+ (1.0,0.0) [0.0|1.0] ""  EMS,IBOX
   SG_ N_INC_TCU : 31|1@1+ (1.0,0.0) [0.0|1.0] ""  EMS,IBOX
   SG_ SPK_RTD_TCU : 32|8@1+ (0.375,-23.625) [-15.0|15.0] ""  EMS,IBOX
   SG_ N_TC_RAW : 40|16@1+ (0.25,0.0) [0.0|16383.5] "rpm"  EMS,IBOX
   SG_ VS_TCU_DECIMAL : 56|8@1+ (0.0078125,0.0) [0.0|0.9921875] "km/h"  CLU,EMS,IBOX,LCA

BO_ 275 TCU13: 8 TCU
   SG_ N_TGT_LUP : 0|8@1+ (10.0,500.0) [500.0|3040.0] "rpm"  EMS,IBOX
   SG_ SLOPE_TCU : 8|6@1+ (0.5,-16.0) [-16.0|15.5] "%"  CLU,CUBIS,EMS,IBOX
   SG_ CF_Tcu_InhCda : 14|1@1+ (1.0,0.0) [0.0|1.0] ""  EMS,IBOX
   SG_ CF_Tcu_IsgInhib : 15|1@1+ (1.0,0.0) [0.0|1.0] ""  EMS,IBOX
   SG_ CF_Tcu_BkeOnReq : 16|2@1+ (1.0,0.0) [0.0|3.0] ""  EMS,IBOX
   SG_ CF_Tcu_NCStat : 18|2@1+ (1.0,0.0) [0.0|3.0] ""  EMS,IBOX
   SG_ CF_Tcu_TarGr : 20|4@1+ (1.0,0.0) [0.0|15.0] ""  _4WD,CLU,DATC,EMS,EPB,ESC,IBOX,SCC
   SG_ CF_Tcu_ShfPatt : 24|4@1+ (1.0,0.0) [0.0|15.0] ""  CLU,CUBIS,EMS,IBOX
   SG_ CF_Tcu_InhVis : 28|1@1+ (1.0,0.0) [0.0|1.0] ""  EMS,IBOX
   SG_ CF_Tcu_PRelReq : 29|1@1+ (1.0,0.0) [0.0|1.0] ""  IBOX,LVR
   SG_ CF_Tcu_ITPhase : 30|1@1+ (1.0,0.0) [0.0|1.0] ""  EMS,IBOX
   SG_ CF_Tcu_ActEcoRdy : 31|1@1+ (1.0,0.0) [0.0|1.0] ""  EMS,IBOX
   SG_ CF_Tcu_TqGrdLim : 32|8@1+ (10.0,0.0) [0.0|2540.0] "Nm/s"  EMS,IBOX
   SG_ CR_Tcu_IsgTgtRPM : 40|8@1+ (20.0,0.0) [0.0|3500.0] "rpm"  EMS,IBOX
   SG_ CF_Tcu_SptRdy : 48|1@1+ (1.0,0.0) [0.0|1.0] ""  CLU,IBOX
   SG_ CF_Tcu_SbwPInfo : 56|1@1+ (1.0,0.0) [0.0|1.0] ""  EMS,IBOX
   SG_ CF_Tcu_Alive3 : 58|2@1+ (1.0,0.0) [0.0|3.0] ""  EMS,IBOX
   SG_ CF_Tcu_ChkSum3 : 60|4@1+ (1.0,0.0) [0.0|15.0] ""  EMS,IBOX

BO_ 276 HU_CLU_PE_01: 8 H_U
   SG_ HU_OpState : 6|7@0+ (1,0) [0|0] ""  AMP,CLU
   SG_ HU_Navi_On_Off : 7|1@0+ (1,0) [0|0] ""  CLU,HUD
   SG_ HU_Preset_Number : 12|5@0+ (1,1) [1|30] ""  AMP,CLU
   SG_ HU_Tuner_Area : 15|3@0+ (1,0) [0|0] ""  AMP,CLU
   SG_ HU_Track_Number : 23|16@0+ (1,0) [0|0] ""  CLU
   SG_ HU_Play_time_Sec : 39|6@0+ (1,0) [0|0] ""  CLU
   SG_ HU_Play_time_Min : 33|7@0+ (1,0) [0|0] ""  CLU
   SG_ HU_Play_time_Hour : 42|6@0+ (1,0) [0|0] ""  CLU
   SG_ HU_Disc_select_No : 59|4@0+ (1,0) [0|0] ""  CLU
   SG_ HU_Frequency : 52|9@0+ (1,0) [0|0] ""  AMP,CLU

BO_ 277 HU_CLU_PE_02: 8 H_U
   SG_ TBT_Display_Type : 7|8@0+ (1,0) [0|0] ""  CLU,HUD
   SG_ TBT_Side_Street : 15|16@0+ (1,0) [0|0] ""  CLU,HUD
   SG_ TBT_Direction : 31|8@0+ (1,0) [0|0] ""  CLU,HUD
   SG_ TBT_Distance_Turn_Point : 39|16@0+ (1,0) [0|0] "m"  CLU,HUD
   SG_ TBT_Combined_Side_Street : 51|4@0+ (1,0) [0|0] ""  CLU,HUD
   SG_ TBT_Scale : 55|4@0+ (1,0) [0|0] ""  CLU,HUD
   SG_ TBT_DistancetoTurnPoint : 59|4@0+ (1,0) [0|0] "times"  CLU,HUD
   SG_ TBT_Bar_Graph_Level : 63|4@0+ (10,0) [0|100] ""  CLU,HUD

BO_ 286 HU_CLU_PE_10: 8 H_U
   SG_ Navi_TBTInfo : 63|8@0+ (1,0) [0|0] ""  CGW,CLU

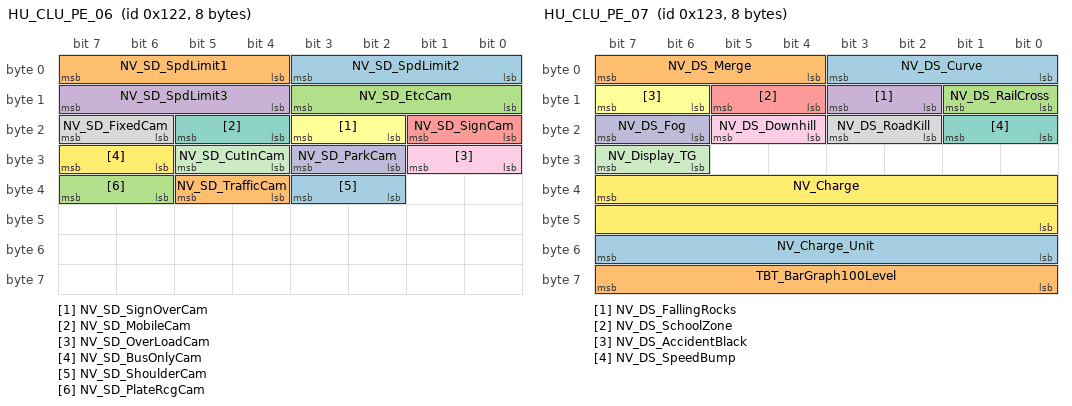
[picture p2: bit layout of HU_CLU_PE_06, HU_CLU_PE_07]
BO_ 290 HU_CLU_PE_06: 8 H_U
   SG_ NV_SD_SpdLimit2 : 3|4@0+ (10,0) [0|0] "km/h"  CLU
   SG_ NV_SD_SpdLimit1 : 7|4@0+ (10,0) [0|0] "km/h"  CLU
   SG_ NV_SD_EtcCam : 11|4@0+ (1,0) [0|0] ""  CLU
   SG_ NV_SD_SpdLimit3 : 15|4@0+ (10,0) [0|0] "km/h"  CLU
   SG_ NV_SD_SignCam : 17|2@0+ (1,0) [0|0] ""  CLU
   SG_ NV_SD_SignOverCam : 19|2@0+ (1,0) [0|0] ""  CLU
   SG_ NV_SD_MobileCam : 21|2@0+ (1,0) [0|0] ""  CLU
   SG_ NV_SD_FixedCam : 23|2@0+ (1,0) [0|0] ""  CLU
   SG_ NV_SD_OverLoadCam : 25|2@0+ (1,0) [0|0] ""  CLU
   SG_ NV_SD_ParkCam : 27|2@0+ (1,0) [0|0] ""  CLU
   SG_ NV_SD_CutInCam : 29|2@0+ (1,0) [0|0] ""  CLU
   SG_ NV_SD_BusOnlyCam : 31|2@0+ (1,0) [0|0] ""  CLU
   SG_ NV_SD_ShoulderCam : 35|2@0+ (1,0) [0|0] ""  CLU
   SG_ NV_SD_TrafficCam : 37|2@0+ (1,0) [0|0] ""  CLU
   SG_ NV_SD_PlateRcgCam : 39|2@0+ (1,0) [0|0] ""  CLU

BO_ 291 HU_CLU_PE_07: 8 H_U
   SG_ NV_DS_Curve : 3|4@0+ (1,0) [0|0] ""  CLU
   SG_ NV_DS_Merge : 7|4@0+ (1,0) [0|0] ""  CLU
   SG_ NV_DS_RailCross : 9|2@0+ (1,0) [0|0] ""  CLU
   SG_ NV_DS_FallingRocks : 11|2@0+ (1,0) [0|0] ""  CLU
   SG_ NV_DS_SchoolZone : 13|2@0+ (1,0) [0|0] ""  CLU
   SG_ NV_DS_AccidentBlack : 15|2@0+ (1,0) [0|0] ""  CLU
   SG_ NV_DS_SpeedBump : 17|2@0+ (1,0) [0|0] ""  CLU
   SG_ NV_DS_RoadKill : 19|2@0+ (1,0) [0|0] ""  CLU
   SG_ NV_DS_Downhill : 21|2@0+ (1,0) [0|0] ""  CLU
   SG_ NV_DS_Fog : 23|2@0+ (1,0) [0|0] ""  CLU
   SG_ NV_Display_TG : 31|2@0+ (1,0) [0|0] ""  CLU,HUD
   SG_ NV_Charge : 39|16@0+ (1,0) [0|0] ""  CLU,HUD
   SG_ NV_Charge_Unit : 55|8@0+ (1,0) [0|0] ""  CLU,HUD
   SG_ TBT_BarGraph100Level : 63|8@0+ (1,0) [0|100] "%"  CLU,HUD

BO_ 304 DATC_PE_01: 8 CLU
   SG_ DATC_Type : 7|8@0+ (1,0) [0|0] ""  H_U,MON
   SG_ DATC_VerMMMajor : 15|8@0+ (1,0) [0|0] ""  H_U,MON
   SG_ DATC_VerMMMinor : 23|8@0+ (1,0) [0|0] ""  H_U,MON
   SG_ DATC_VerBDFMajor : 31|8@0+ (1,0) [0|0] ""  H_U,MON
   SG_ DATC_VerBDMinor : 39|8@0+ (1,0) [0|0] ""  H_U,MON
   SG_ DATC_VerCSMajor : 47|8@0+ (1,0) [0|0] ""  H_U,MON
   SG_ DATC_VerCSMinor : 55|8@0+ (1,0) [0|0] ""  H_U,MON

BO_ 305 DATC_PE_02: 8 CLU
   SG_ DATC_DrTempDispC : 7|8@0+ (0.5,14) [15|32] "C"  H_U,IBOX,MON
   SG_ DATC_Rear_DrTempDispC : 15|8@0+ (0.5,14) [15|32] "C"  H_U,IBOX,MON
   SG_ DATC_DrTempDispF : 23|8@0+ (1,56) [58|90] "F"  H_U,IBOX,MON
   SG_ DATC_Rear_DrTempDispF : 31|8@0+ (1,56) [58|90] "F"  H_U,IBOX,MON
   SG_ DATC_PsTempDispC : 39|8@0+ (0.5,14) [15|32] "C"  H_U,IBOX,MON
   SG_ Datc_RearPsTempDispC : 47|8@0+ (0.5,14) [15|32] "C"  H_U,IBOX,MON
   SG_ DATC_PsTempDispF : 55|8@0+ (1,56) [58|90] "F"  H_U,IBOX,MON
   SG_ DATC_RearPsTempDispF : 63|8@0+ (1,56) [58|90] "F"  H_U,IBOX,MON

BO_ 306 DATC_PE_03: 8 CLU
   SG_ DATC_ModeDisp : 3|4@0+ (1,0) [0|0] ""  H_U,IBOX
   SG_ DATC_TempUnit : 5|2@0+ (1,0) [0|0] ""  H_U,IBOX
   SG_ DATC_AutoDisp : 9|2@0+ (1,0) [0|0] ""  H_U,IBOX
   SG_ DATC_IntakeDisp : 11|2@0+ (1,0) [0|0] ""  H_U,IBOX
   SG_ DATC_ChangeReqDisp : 13|2@0+ (1,0) [0|0] ""  H_U,IBOX
   SG_ DATC_AcDisp : 17|2@0+ (1,0) [0|0] ""  H_U,IBOX
   SG_ DATC_AqsDisp : 19|2@0+ (1,0) [0|0] ""  H_U,IBOX
   SG_ DATC_ClimateScnDisp : 21|2@0+ (1,0) [0|0] ""  H_U,IBOX
   SG_ DATC_DualDisp : 25|2@0+ (1,0) [0|0] ""  H_U,IBOX
   SG_ DATC_OffDisp : 27|2@0+ (1,0) [0|0] ""  H_U,IBOX
   SG_ DATC_OpSts : 30|3@0+ (1,0) [0|0] ""  H_U,IBOX
   SG_ DATC_RearManual : 33|2@0+ (1,0) [0|0] ""  H_U,MON
   SG_ DATC_FrDefLed : 37|2@0+ (1,0) [0|0] ""  H_U
   SG_ DATC_SmartVentDisp : 39|2@0+ (1,0) [0|0] ""  H_U
   SG_ DATC_AutoDefogBlink : 41|2@0+ (1,0) [0|0] ""  H_U,IBOX
   SG_ DATC_ADSDisp : 43|2@0+ (1,0) [0|0] ""  H_U
   SG_ DATC_IonClean : 45|2@0+ (1,0) [0|0] ""  H_U,IBOX
   SG_ DATC_CO2Warning : 47|2@0+ (1,0) [0|0] ""  H_U,IBOX
   SG_ DATC_SubBlowerDisp : 51|4@0+ (1,0) [0|0] ""  H_U,MON
   SG_ DATC_BeepReq : 55|4@0+ (1,0) [0|0] ""  H_U,KBD,MON
   SG_ DATC_MainBlowerDisp : 59|4@0+ (1,0) [0|0] ""  H_U,IBOX
   SG_ DATC_PsModeDisp : 63|4@0+ (1,0) [0|0] ""  H_U,IBOX

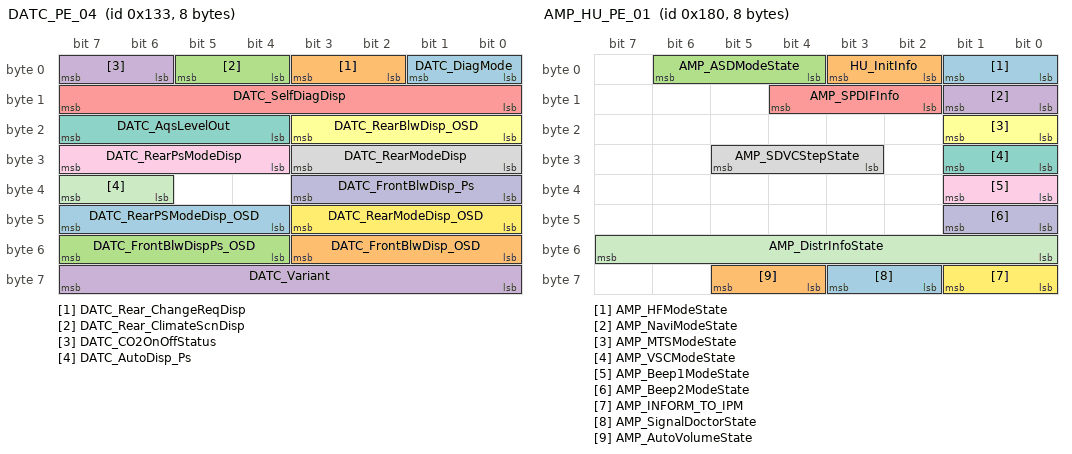
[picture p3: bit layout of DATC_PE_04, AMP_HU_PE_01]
BO_ 307 DATC_PE_04: 8 CLU
   SG_ DATC_DiagMode : 1|2@0+ (1,0) [0|0] ""  H_U,IBOX,MON
   SG_ DATC_Rear_ChangeReqDisp : 3|2@0+ (1,0) [0|0] ""  H_U,IBOX,MON
   SG_ DATC_Rear_ClimateScnDisp : 5|2@0+ (1,0) [0|0] ""  H_U,IBOX,MON
   SG_ DATC_CO2OnOffStatus : 7|2@0+ (1,0) [0|0] ""  H_U
   SG_ DATC_SelfDiagDisp : 15|8@0+ (1,0) [0|0] ""  H_U,IBOX,MON
   SG_ DATC_RearBlwDisp_OSD : 19|4@0+ (1,0) [0|0] ""  H_U
   SG_ DATC_AqsLevelOut : 23|4@0+ (1,0) [0|0] ""  H_U,IBOX,MON
   SG_ DATC_RearModeDisp : 27|4@0+ (1,0) [0|0] ""  H_U
   SG_ DATC_RearPsModeDisp : 31|4@0+ (1,0) [0|0] ""  H_U
   SG_ DATC_FrontBlwDisp_Ps : 35|4@0+ (1,0) [0|0] ""  H_U
   SG_ DATC_AutoDisp_Ps : 39|2@0+ (1,0) [0|0] ""  H_U
   SG_ DATC_RearModeDisp_OSD : 43|4@0+ (1,0) [0|0] ""  H_U
   SG_ DATC_RearPSModeDisp_OSD : 47|4@0+ (1,0) [0|0] ""  H_U
   SG_ DATC_FrontBlwDisp_OSD : 51|4@0+ (1,0) [0|0] ""  H_U
   SG_ DATC_FrontBlwDispPs_OSD : 55|4@0+ (1,0) [0|0] ""  H_U
   SG_ DATC_Variant : 63|8@0+ (1,0) [0|0] ""  H_U,IBOX,MON

BO_ 308 DATC_PE_05: 8 CLU
   SG_ DATC_PwrInfo : 3|4@0+ (1,0) [0|0] ""  AMP,AVM,CUBIS,H_U,MON
   SG_ DATC_AltL : 5|2@0+ (1,0) [0|0] ""  H_U,MON
   SG_ DATC_CarInfo : 7|2@0+ (1,0) [0|0] ""  H_U
   SG_ DATC_ParkingBrake : 9|2@0+ (1,0) [0|0] ""  H_U
   SG_ DATC_LowFuelWarn : 11|2@0+ (1,0) [0|0] ""  H_U
   SG_ DATC_Rear_Off_Disp : 13|2@0+ (1,0) [0|0] ""  H_U,MON
   SG_ DATC_Rear_AutoDisp : 15|2@0+ (1,0) [0|0] ""  H_U,MON
   SG_ DATC_Rear_BlowerDisp : 19|4@0+ (1,0) [0|0] ""  H_U,MON
   SG_ DATC_DrSeatWarmerDisp : 22|3@0+ (1,0) [0|0] ""  H_U,MON
   SG_ DATC_SyncDisp : 27|4@0+ (1,0) [0|0] ""  H_U,MON
   SG_ DATC_RearDispCtrl : 31|4@0+ (1,0) [0|0] ""  H_U,MON
   SG_ DATC_RearDrModeDisp : 35|4@0+ (1,0) [0|0] ""  H_U
   SG_ DATC_PsSeatWarmerDisp : 38|3@0+ (1,0) [0|0] ""  H_U,MON
   SG_ DATC_DrVentSeatDisp : 42|3@0+ (1,0) [0|0] ""  H_U,MON
   SG_ DATC_PSVentSeatDisp : 46|3@0+ (1,0) [0|0] ""  H_U,MON
   SG_ DATC_RrDefLed : 49|2@0+ (1,0) [0|0] ""  H_U,MON
   SG_ DATC_SmartVentOnOffStatus : 51|2@0+ (1,0) [0|0] ""  H_U
   SG_ DATC_ADSOnOffStatus : 53|2@0+ (1,0) [0|0] ""  H_U
   SG_ DATC_AcDisp_OSD : 55|2@0+ (1,0) [0|0] ""  H_U
   SG_ DATC_PsModeDisp_OSD : 59|4@0+ (1,0) [0|0] ""  H_U
   SG_ DATC_ModeDisp_OSD : 63|4@0+ (1,0) [0|0] ""  H_U

BO_ 320 YRS2: 8 XXX
   SG_ CF_Yrs_McuStat : 0|8@1+ (1,0) [0|255] "" XXX
   SG_ CF_Yrs_SnsStat2 : 8|8@1+ (1,0) [0|255] "" XXX
   SG_ CF_Yrs_ExtSysStat : 32|8@1+ (1,0) [0|255] "" XXX
   SG_ CR_Yrs_Diag : 40|8@1+ (1,0) [0|255] "" XXX
   SG_ CR_Yrs_MsgCnt2 : 48|4@1+ (1,0) [0|15] "" XXX
   SG_ CF_Yrs_Type : 52|4@1+ (1,0) [0|15] "" XXX
   SG_ CR_Yrs_Crc2 : 56|8@1+ (1,0) [0|255] "" XXX

BO_ 325 TMU_HU_PE_01: 8 TMU
   SG_ TMU_AliveStatus : 2|3@0+ (1,0) [0|0] ""  H_U
   SG_ TMU_AudioStatus : 4|2@0+ (1,0) [0|0] ""  H_U
   SG_ TMU_UpdateStatus : 7|3@0+ (1,0) [0|0] ""  H_U
   SG_ TMU_LangStatus : 10|3@0+ (1,0) [0|0] ""  H_U
   SG_ TMU_VoiceRecStatus : 12|2@0+ (1,0) [0|0] ""  H_U
   SG_ TMU_MicStatus : 14|2@0+ (1,0) [0|0] ""  H_U
   SG_ TMU_ServCommuStatus : 19|4@0+ (1,0) [0|0] ""  H_U
   SG_ TMU_PowerStatus : 21|2@0+ (1,0) [0|0] ""  H_U
   SG_ TMU_EngineStatus : 23|2@0+ (1,0) [0|0] ""  H_U
   SG_ TMU_DownProgress : 31|8@0+ (1,0) [0|0] ""  H_U

BO_ 326 TMU_HU_PE_02: 8 TMU
   SG_ TMU_CallStatus : 3|4@0+ (1,0) [0|0] ""  H_U
   SG_ TMU_CallType : 6|3@0+ (1,0) [0|0] ""  H_U
   SG_ TMU_CDMA_Streng : 11|4@0+ (1,0) [0|0] ""  H_U
   SG_ TMU_PacketStatus : 13|2@0+ (1,0) [0|0] ""  H_U
   SG_ TMU_TalkTimeHour : 20|5@0+ (1,0) [0|0] ""  H_U
   SG_ TMU_TalkTimeMinute : 29|6@0+ (1,0) [0|0] ""  H_U
   SG_ TMU_TalkTimeSecond : 37|6@0+ (1,0) [0|0] ""  H_U

BO_ 327 TMU_HU_PE_03: 8 TMU
   SG_ TMU_TbT_TurnIcon : 7|8@0+ (1,0) [0|0] ""  H_U
   SG_ TMU_TbT_CountDownBar : 11|4@0+ (1,0) [0|0] ""  H_U
   SG_ TMU_TbT_Distance_Unit : 13|2@0+ (1,0) [0|0] ""  H_U
   SG_ TMU_TbT_DestDistance_Unit : 15|2@0+ (1,0) [0|0] ""  H_U
   SG_ TMU_TbT_DistanceLo : 27|4@0+ (1,0) [0|0] ""  H_U
   SG_ TMU_TbT_DistanceHi : 23|12@0+ (1,0) [0|0] ""  H_U
   SG_ TMU_TbT_DestDistanceLo : 43|4@0+ (1,0) [0|0] ""  H_U
   SG_ TMU_TbT_DestDistanceHi : 39|12@0+ (1,0) [0|0] ""  H_U
   SG_ TMU_TbT_ExpectRemainHour : 55|8@0+ (1,0) [0|0] ""  H_U
   SG_ TMU_TbT_ExpectRemainMin : 61|6@0+ (1,0) [0|0] ""  H_U

BO_ 339 TCS1: 8 XXX
   SG_ TCS_REQ : 0|1@1+ (1,0) [0|1] "" XXX
   SG_ MSR_C_REQ : 1|1@1+ (1,0) [0|1] "" XXX
   SG_ TCS_PAS : 2|1@1+ (1,0) [0|1] "" XXX
   SG_ TCS_GSC : 3|1@1+ (1,0) [0|1] "" XXX
   SG_ CF_Esc_LimoInfo : 4|2@1+ (1,0) [0|3] "" XXX
   SG_ ABS_DIAG : 6|1@1+ (1,0) [0|1] "" XXX
   SG_ ABS_DEF : 7|1@1+ (1,0) [0|1] "" XXX
   SG_ TCS_DEF : 8|1@1+ (1,0) [0|1] "" XXX
   SG_ TCS_CTL : 9|1@1+ (1,0) [0|1] "" XXX
   SG_ ABS_ACT : 10|1@1+ (1,0) [0|1] "" XXX
   SG_ EBD_DEF : 11|1@1+ (1,0) [0|1] "" XXX
   SG_ ESP_PAS : 12|1@1+ (1,0) [0|1] "" XXX
   SG_ ESP_DEF : 13|1@1+ (1,0) [0|1] "" XXX
   SG_ ESP_CTL : 14|1@1+ (1,0) [0|1] "" XXX
   SG_ TCS_MFRN : 15|1@1+ (1,0) [0|1] "" XXX
   SG_ DBC_CTL : 16|1@1+ (1,0) [0|1] "" XXX
   SG_ DBC_PAS : 17|1@1+ (1,0) [0|1] "" XXX
   SG_ DBC_DEF : 18|1@1+ (1,0) [0|1] "" XXX
   SG_ HAC_CTL : 19|1@1+ (1,0) [0|1] "" XXX
   SG_ HAC_PAS : 20|1@1+ (1,0) [0|1] "" XXX
   SG_ HAC_DEF : 21|1@1+ (1,0) [0|1] "" XXX
   SG_ ESS_STAT : 22|2@1+ (1,0) [0|3] "" XXX
   SG_ TQI_TCS : 24|8@1+ (0.390625,0) [0|99.6094] "%" XXX
   SG_ TQI_MSR : 32|8@1+ (0.390625,0) [0|99.6094] "%" XXX
   SG_ TQI_SLW_TCS : 40|8@1+ (0.390625,0) [0|99.6094] "%" XXX
   SG_ CF_Esc_BrkCtl : 48|1@1+ (1,0) [0|1] "" XXX
   SG_ ESC_OFF_STEP : 49|2@1+ (1,0) [0|3] "" XXX
   SG_ _4WD_Status : 51|1@1+ (1,0) [0|1] "" XXX
   SG_ AliveCounter_TCS1 : 52|4@1+ (1,0) [0|1] "" XXX
   SG_ CheckSum_TCS1 : 56|8@1+ (1,0) [0|1] "" XXX

BO_ 339 TCS11: 8 ESC
   SG_ TCS_REQ : 0|1@1+ (1.0,0.0) [0.0|1.0] ""  _4WD,EMS,EPB,TCU
   SG_ MSR_C_REQ : 1|1@1+ (1.0,0.0) [0.0|1.0] ""  EMS,EPB,SCC,TCU
   SG_ TCS_PAS : 2|1@1+ (1.0,0.0) [0.0|1.0] ""  _4WD,CLU,EMS,SCC,SPAS,TCU
   SG_ TCS_GSC : 3|1@1+ (1.0,0.0) [0.0|1.0] ""  _4WD,EMS,TCU
   SG_ CF_Esc_LimoInfo : 4|2@1+ (1.0,0.0) [0.0|3.0] ""  _4WD,SCC
   SG_ ABS_DIAG : 6|1@1+ (1.0,0.0) [0.0|1.0] ""  _4WD,CLU,EMS,EPB
   SG_ ABS_DEF : 7|1@1+ (1.0,0.0) [0.0|1.0] ""  _4WD,ACU,ECS,EMS,EPB,SCC,SPAS,TCU
   SG_ TCS_DEF : 8|1@1+ (1.0,0.0) [0.0|1.0] ""  _4WD,EMS,EPB,SCC,SPAS,TCU
   SG_ TCS_CTL : 9|1@1+ (1.0,0.0) [0.0|1.0] ""  _4WD,EMS,EPB,SCC,SPAS,TCU
   SG_ ABS_ACT : 10|1@1+ (1.0,0.0) [0.0|1.0] ""  _4WD,ACU,ECS,EMS,EPB,LDWS_LKAS,SCC,SPAS,TCU
   SG_ EBD_DEF : 11|1@1+ (1.0,0.0) [0.0|1.0] ""  _4WD,EMS,EPB,SPAS,TCU
   SG_ ESP_PAS : 12|1@1+ (1.0,0.0) [0.0|1.0] ""  _4WD,ACU,CLU,EMS,EPB,LDWS_LKAS,SCC,TCU
   SG_ ESP_DEF : 13|1@1+ (1.0,0.0) [0.0|1.0] ""  _4WD,ACU,ECS,EMS,EPB,LDWS_LKAS,SCC,TCU
   SG_ ESP_CTL : 14|1@1+ (1.0,0.0) [0.0|1.0] ""  _4WD,ACU,ECS,EMS,EPB,LDWS_LKAS,SCC,SPAS,TCU
   SG_ TCS_MFRN : 15|1@1+ (1.0,0.0) [0.0|1.0] ""  EMS,EPB,TCU
   SG_ DBC_CTL : 16|1@1+ (1.0,0.0) [0.0|1.0] ""  _4WD,EMS,EPB
   SG_ DBC_PAS : 17|1@1+ (1.0,0.0) [0.0|1.0] ""  _4WD,EMS,EPB
   SG_ DBC_DEF : 18|1@1+ (1.0,0.0) [0.0|1.0] ""  _4WD,EMS,EPB
   SG_ HAC_CTL : 19|1@1+ (1.0,0.0) [0.0|1.0] ""  _4WD,CLU,EMS,EPB,TCU
   SG_ HAC_PAS : 20|1@1+ (1.0,0.0) [0.0|1.0] ""  _4WD,CLU,EMS,EPB,TCU
   SG_ HAC_DEF : 21|1@1+ (1.0,0.0) [0.0|1.0] ""  _4WD,CLU,EMS,EPB,TCU
   SG_ ESS_STAT : 22|2@1+ (1.0,0.0) [0.0|3.0] ""  _4WD,BCM,CLU,EMS,EPB
   SG_ TQI_TCS : 24|8@1+ (0.390625,0.0) [0.0|99.609375] "%"  EMS,EPB,TCU
   SG_ TQI_MSR : 32|8@1+ (0.390625,0.0) [0.0|99.609375] "%"  EMS,EPB,TCU
   SG_ TQI_SLW_TCS : 40|8@1+ (0.390625,0.0) [0.0|99.609375] "%"  EMS,EPB,TCU
   SG_ CF_Esc_BrkCtl : 48|1@1+ (1.0,0.0) [0.0|1.0] ""  EMS
   SG_ BLA_CTL : 49|2@1+ (1.0,0.0) [0.0|3.0] ""  BCM,CGW,CLU
   SG_ AliveCounter_TCS1 : 52|4@1+ (1.0,0.0) [0.0|14.0] ""  EMS,EPB,LDWS_LKAS
   SG_ CheckSum_TCS1 : 56|8@1+ (1.0,0.0) [0.0|255.0] ""  EMS,EPB,LDWS_LKAS

BO_ 343 GW_WARNING_PE_02: 8 CLU
   SG_ CF_Lkas_TsrSlifOpt : 1|2@0+ (1,0) [0|3] ""  H_U
   SG_ CF_Lkas_TsrStatus : 3|2@0+ (1,0) [0|3] ""  H_U
   SG_ CF_Lkas_TsrAddinfo_Disp : 7|2@0+ (1,0) [0|3] ""  H_U
   SG_ CF_Lkas_TsrSpeed_Display : 15|8@0+ (1,0) [0|255] ""  H_U

BO_ 344 GW_CLU_PE: 8 CLU
   SG_ C_InhibitP : 1|2@0+ (1,0) [0|0] ""  H_U,IBOX
   SG_ C_InhibitR : 3|2@0+ (1,0) [0|0] ""  H_U,IBOX
   SG_ C_InhibitN : 5|2@0+ (1,0) [0|0] ""  H_U,IBOX
   SG_ C_InhibitD : 7|2@0+ (1,0) [0|0] ""  H_U,IBOX
   SG_ C_P_BrakeStatus : 9|2@0+ (1,0) [0|0] ""  H_U,IBOX
   SG_ C_Clu_AltLStatus : 11|2@0+ (1,0) [0|0] ""  H_U,IBOX
   SG_ CF_Clu_LowfuelWarning : 13|2@0+ (1,0) [0|0] ""  H_U,IBOX
   SG_ C_InhibitRMT : 15|2@0+ (1,0) [0|0] ""  H_U
   SG_ CF_SMKRKECmd : 18|3@0+ (1,0) [0|0] ""  H_U

BO_ 354 TCU_DCT13: 3 TCU
   SG_ Clutch_Driving_Tq : 0|10@1+ (1.0,-512.0) [0.0|0.0] "Nm"  ESC
   SG_ Cluster_Engine_RPM : 10|13@1+ (0.9766,0.0) [0.0|0.0] ""  CLU
   SG_ Cluster_Engine_RPM_Flag : 23|1@1+ (1.0,0.0) [0.0|0.0] ""  CLU

BO_ 356 VSM11: 4 ESC
   SG_ CR_Esc_StrTqReq : 0|12@1+ (0.01,-20.48) [-20.48|20.47] "Nm"  MDPS
   SG_ CF_Esc_Act : 12|1@1+ (1.0,0.0) [0.0|1.0] ""  LDWS_LKAS,MDPS
   SG_ CF_Esc_CtrMode : 13|3@1+ (1.0,0.0) [0.0|7.0] ""  MDPS
   SG_ CF_Esc_Def : 16|1@1+ (1.0,0.0) [0.0|1.0] ""  MDPS
   SG_ CF_Esc_AliveCnt : 17|4@1+ (1.0,0.0) [0.0|15.0] ""  LDWS_LKAS,MDPS
   SG_ CF_Esc_Chksum : 24|8@1+ (1.0,0.0) [0.0|255.0] ""  LDWS_LKAS,MDPS

BO_ 357 VSM2: 8 XXX
   SG_ CR_Mdps_StrTq : 0|12@1+ (0.01,-20.48) [-20.48|20.47] "Nm" XXX
   SG_ CR_Mdps_OutTq : 12|12@1+ (0.1,-204.8) [-204.8|204.7] "" XXX
   SG_ CF_Mdps_Def : 24|1@1+ (1,0) [0|1] "" XXX
   SG_ CF_Mdps_SErr : 25|1@1+ (1,0) [0|1] "" XXX
   SG_ CF_Mdps_AliveCnt : 48|4@1+ (1,0) [0|15] "" XXX
   SG_ CF_Mdps_Chksum : 56|8@1+ (1,0) [0|255] "" XXX

BO_ 359 GW_WARNING_PE_01: 8 CLU
   SG_ Spas_BEEP_Alarm : 3|4@0+ (1,0) [0|0] ""  AMP
   SG_ Spas_Audio_VolumeDown : 5|2@0+ (1,0) [0|0] ""  AMP
   SG_ Spas_Spkr_Flh_Alarm : 9|2@0+ (1,0) [0|0] ""  AMP,H_U
   SG_ Spas_Spkr_Fcnt_Alarm : 11|2@0+ (1,0) [0|0] ""  AMP,H_U
   SG_ Spas_Spkr_Frh_Alarm : 13|2@0+ (1,0) [0|0] ""  AMP,H_U
   SG_ Spas_Spkr_Rlh_Alarm : 17|2@0+ (1,0) [0|0] ""  AMP,H_U
   SG_ Spas_Spkr_Rcnt_Alarm : 19|2@0+ (1,0) [0|0] ""  AMP,H_U
   SG_ Spas_Spkr_Rrh_Alarm : 21|2@0+ (1,0) [0|0] ""  AMP,H_U
   SG_ Lkas_SysStatus : 27|4@0+ (1,0) [0|0] ""  AMP,H_U
   SG_ Lkas_LH_Warning : 29|2@0+ (1,0) [0|0] ""  AMP,H_U
   SG_ Lkas_RH_Warning : 31|2@0+ (1,0) [0|0] ""  AMP,H_U
   SG_ Spas_Spkr_Level : 35|3@0+ (1,0) [0|0] ""  AMP
   SG_ Lkas_Audio_VolumeDown : 37|2@0+ (1,0) [0|0] ""  AMP,H_U
   SG_ Audio_VolumeDown : 39|2@0+ (1,0) [0|0] ""  AMP,H_U
   SG_ Pas_BEEP_Alarm : 43|4@0+ (1,0) [0|0] ""  AMP
   SG_ Pas_Audio_VolumeDown : 45|2@0+ (1,0) [0|0] ""  AMP,H_U
   SG_ Pas_Spkr_Level : 32|3@0+ (1,0) [0|0] ""  AMP
   SG_ Pas_Spkr_Flh_Alarm : 49|2@0+ (1,0) [0|0] ""  AMP,H_U
   SG_ Pas_Spkr_Fcnt_Alarm : 51|2@0+ (1,0) [0|0] ""  AMP,H_U
   SG_ Pas_Spkr_Frh_Alarm : 53|2@0+ (1,0) [0|0] ""  AMP,H_U
   SG_ Pas_Spkr_Rlh_Alarm : 57|2@0+ (1,0) [0|0] ""  AMP,H_U
   SG_ Pas_Spkr_Rcnt_Alarm : 59|2@0+ (1,0) [0|0] ""  AMP,H_U
   SG_ Pas_Spkr_Rrh_Alarm : 61|2@0+ (1,0) [0|0] ""  AMP,H_U

BO_ 361 GW_CHASSIS_PE_1: 8 CLU
   SG_ C_Inhibit_State : 3|4@0+ (1,0) [0|0] ""  AVM,H_U
   SG_ C_P_BrakeStatus : 5|2@0+ (1,0) [0|0] ""  AVM,H_U
   SG_ C_Clu_AltLStatus : 7|2@0+ (1,0) [0|0] ""  AVM,H_U

BO_ 362 GW_IPM_PE_1: 8 CLU
   SG_ C_AV_Tail : 1|2@0+ (1,0) [0|0] ""  AMP,CCP,CLOCK,CLU,HUD,H_U,IBOX,RRC,RSE_L
   SG_ C_ParkingBrakeSW : 3|2@0+ (1,0) [0|0] ""  H_U
   SG_ C_RKECMD : 7|4@0+ (1,0) [0|0] ""  H_U
   SG_ C_BAState : 9|2@0+ (1,0) [0|0] ""  H_U,IBOX
   SG_ C_IGNSW : 14|3@0+ (1,0) [0|0] ""  AMP,AVM,CUBIS,EDT,H_U,MON,RRC,SWRC
   SG_ C_CountryCfg : 18|3@0+ (1,0) [0|0] ""  AVM,H_U
   SG_ C_AltL : 25|2@0+ (1,0) [0|0] ""  H_U
   SG_ C_TailLampActivity : 27|2@0+ (1,0) [0|0] ""  AMP,CCP,CLOCK,HUD,H_U,IBOX,RRC,RSE_L,SWRC
   SG_ RearSW_RSELockOnOff : 29|2@0+ (1,0) [0|0] ""  H_U,IBOX
   SG_ C_TMULockFeedBack : 31|2@0+ (1,0) [0|0] ""  CUBIS,TMU
   SG_ C_SMKTeleCrankingState : 33|2@0+ (1,0) [0|0] ""  H_U,IBOX
   SG_ C_SMKTeleCrankingFailRes : 35|2@0+ (1,0) [0|0] ""  H_U,IBOX
   SG_ C_RKECMD_GEN2 : 39|3@0+ (1,0) [0|0] ""  H_U,IBOX
   SG_ C_Acu_CshAct : 41|2@0+ (1,0) [0|0] ""  H_U,IBOX
   SG_ C_IntTailAct : 43|2@0+ (1,0) [0|0] ""  AMP,CCP,CLOCK,CLU,HUD,H_U,IBOX,RRC,RSE_L
   SG_ C_PassiveAccessUnlock : 47|3@0+ (1,0) [0|0] ""  H_U,IBOX
   SG_ Lca_IndLeft : 49|2@0+ (1,0) [0|0] ""  H_U
   SG_ FL_SndWarn : 51|2@0+ (1,0) [0|0] ""  AMP
   SG_ FR_SndWarn : 53|2@0+ (1,0) [0|0] ""  AMP
   SG_ Lca_IndRight : 55|2@0+ (1,0) [0|0] ""  H_U
   SG_ RCTA_IndLeft : 57|2@0+ (1,0) [0|0] ""  H_U
   SG_ RL_SndWarn : 59|2@0+ (1,0) [0|0] ""  AMP
   SG_ RR_SndWarn : 61|2@0+ (1,0) [0|0] ""  AMP
   SG_ RCTA_IndRight : 63|2@0+ (1,0) [0|0] ""  H_U

BO_ 363 GW_IPM_PE_2: 8 CLU
   SG_ C_DRVUnlockState : 1|2@0+ (1,0) [0|0] ""  CUBIS,TMU
   SG_ C_ASTUnlockState : 3|2@0+ (1,0) [0|0] ""  CUBIS,TMU
   SG_ C_RLUnlockstate : 5|2@0+ (1,0) [0|0] ""  CUBIS,TMU
   SG_ C_RRUnlockState : 7|2@0+ (1,0) [0|0] ""  CUBIS,TMU
   SG_ C_VehicleInfoTMU : 9|2@0+ (1,0) [0|0] ""  CUBIS,TMU
   SG_ C_Engine_Status : 11|2@0+ (1,0) [0|0] ""  CUBIS,TMU
   SG_ C_TMULockFeedBack : 23|2@0+ (1,0) [0|0] ""  CUBIS,TMU

BO_ 369 HU_Car_PE_01: 8 H_U
   SG_ HU_VehiclePwr : 3|4@0+ (1,0) [0|0] ""  AMP,ASD,AVM,CCP,CLOCK,CLU,CUBIS,DATC,FHCU,IPM,KBD,KMA_TMU,MON,RRC,RSE_L,RSE_R,TMU

BO_ 371 HU_TMU_PE_01: 8 H_U
   SG_ HU_AliveStatus : 1|2@0+ (1,0) [0|0] ""  CLU,CGW,TMU
   SG_ HU_DeviceType : 5|4@0+ (1,0) [0|0] ""  TMU
   SG_ HU_DistanceUnit : 7|2@0+ (1,0) [0|0] ""  TMU
   SG_ HU_AudAllocStatus : 9|2@0+ (1,0) [0|0] ""  TMU
   SG_ HU_PowerStatus : 12|3@0+ (1,0) [0|0] ""  TMU
   SG_ HU_BTCallStatus : 15|3@0+ (1,0) [0|0] ""  TMU
   SG_ HU_VoiceRecStatus : 17|2@0+ (1,0) [0|0] ""  TMU
   SG_ HU_LangStatus : 20|3@0+ (1,0) [0|0] ""  TMU

BO_ 384 AMP_HU_PE_01: 8 AMP
   SG_ AMP_HFModeState : 1|2@0+ (1,0) [0|0] ""  CLU,H_U
   SG_ HU_InitInfo : 3|2@0+ (1,0) [0|0] ""  CLU,H_U
   SG_ AMP_ASDModeState : 6|3@0+ (1,0) [0|0] ""  CLU,H_U
   SG_ AMP_NaviModeState : 9|2@0+ (1,0) [0|0] ""  CLU,H_U
   SG_ AMP_SPDIFInfo : 12|3@0+ (1,0) [0|0] ""  CLU,H_U
   SG_ AMP_MTSModeState : 17|2@0+ (1,0) [0|0] ""  CLU,H_U
   SG_ AMP_VSCModeState : 25|2@0+ (1,0) [0|0] ""  CLU,H_U
   SG_ AMP_SDVCStepState : 29|3@0+ (1,0) [0|0] ""  CLU,H_U
   SG_ AMP_Beep1ModeState : 33|2@0+ (1,0) [0|0] ""  CLU,H_U
   SG_ AMP_Beep2ModeState : 41|2@0+ (1,0) [0|0] ""  CLU,H_U
   SG_ AMP_DistrInfoState : 55|8@0+ (1,0) [0|0] ""  CLU,H_U
   SG_ AMP_INFORM_TO_IPM : 57|2@0+ (1,0) [0|0] ""  CGW,CLU,DATC,H_U,IPM
   SG_ AMP_SignalDoctorState : 59|2@0+ (1,0) [0|0] ""  H_U
   SG_ AMP_AutoVolumeState : 61|2@0+ (1,0) [0|0] ""  H_U

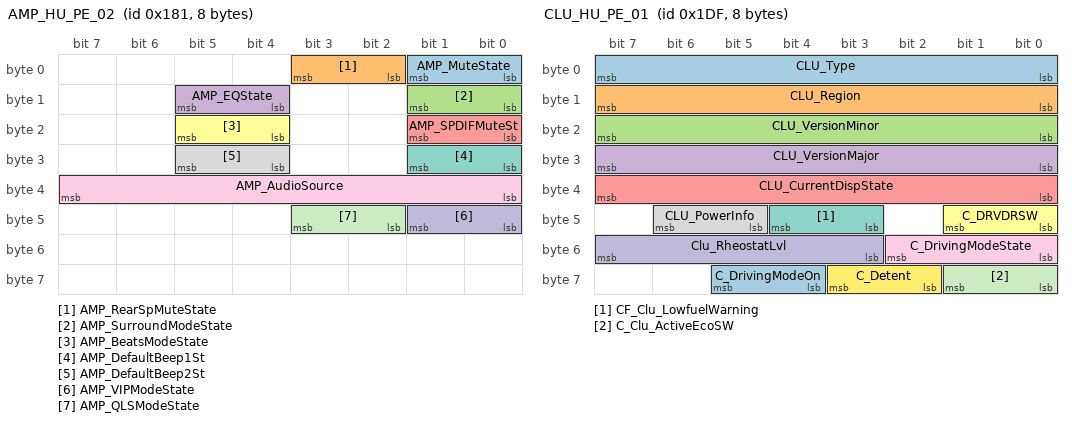
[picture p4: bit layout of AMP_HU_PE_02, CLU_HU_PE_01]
BO_ 385 AMP_HU_PE_02: 8 AMP
   SG_ AMP_MuteState : 1|2@0+ (1,0) [0|0] ""  H_U
   SG_ AMP_RearSpMuteState : 3|2@0+ (1,0) [0|0] ""  H_U
   SG_ AMP_SurroundModeState : 9|2@0+ (1,0) [0|0] ""  H_U
   SG_ AMP_EQState : 13|2@0+ (1,0) [0|0] ""  H_U
   SG_ AMP_SPDIFMuteSt : 17|2@0+ (1,0) [0|0] ""  H_U
   SG_ AMP_BeatsModeState : 21|2@0+ (1,0) [0|0] ""  H_U
   SG_ AMP_DefaultBeep1St : 25|2@0+ (1,0) [0|0] ""  H_U
   SG_ AMP_DefaultBeep2St : 29|2@0+ (1,0) [0|0] ""  H_U
   SG_ AMP_AudioSource : 39|8@0+ (1,0) [0|0] ""  H_U
   SG_ AMP_VIPModeState : 41|2@0+ (1,0) [0|0] ""  H_U
   SG_ AMP_QLSModeState : 43|2@0+ (1,0) [0|0] ""  H_U

BO_ 387 REA11: 8 REA
   SG_ CF_EndBst_PwmDuH : 0|1@1+ (1.0,0.0) [0.0|1.0] ""  EMS
   SG_ CF_EndBst_PwmDuL : 1|1@1+ (1.0,0.0) [0.0|1.0] ""  EMS
   SG_ CF_EndBst_PwmFqOutRng : 2|1@1+ (1.0,0.0) [0.0|1.0] ""  EMS
   SG_ CF_EndBst_HbriOverCur : 3|1@1+ (1.0,0.0) [0.0|1.0] ""  EMS
   SG_ CF_EndBst_HbriOverTemp : 4|1@1+ (1.0,0.0) [0.0|1.0] ""  EMS
   SG_ CF_EndBst_PosSnsKOR : 6|1@1+ (1.0,0.0) [0.0|1.0] ""  EMS
   SG_ CF_EndBst_PosSnsOSOR : 7|1@1+ (1.0,0.0) [0.0|1.0] ""  EMS
   SG_ CF_EndBst_EepFlt : 8|1@1+ (1.0,0.0) [0.0|1.0] ""  EMS
   SG_ CF_EndBst_RomFlt : 9|1@1+ (1.0,0.0) [0.0|1.0] ""  EMS
   SG_ CF_EndBst_RamFlt : 10|1@1+ (1.0,0.0) [0.0|1.0] ""  EMS
   SG_ CF_EndBst_CanFlt : 11|1@1+ (1.0,0.0) [0.0|1.0] ""  EMS
   SG_ CF_EndBst_AgH : 12|1@1+ (1.0,0.0) [0.0|1.0] ""  EMS
   SG_ CF_EndBst_AgL : 13|1@1+ (1.0,0.0) [0.0|1.0] ""  EMS
   SG_ CF_EndBst_ORVol : 14|1@1+ (1.0,0.0) [0.0|1.0] ""  EMS
   SG_ CR_EndBst_ActPos : 16|16@1+ (0.117,0.0) [1.989|118.053] ""  EMS
   SG_ CR_EndBst_DemPos : 32|16@1+ (0.117,0.0) [0.0|119.691] ""  EMS
   SG_ CR_EndBst_HbriPwr : 48|16@1+ (0.045,0.0) [0.0|99.99] "%"  EMS

BO_ 388 AMP_HU_PE_04: 8 AMP
   SG_ AMP_PESSModeState : 1|2@0+ (1,0) [0|0] ""  H_U
   SG_ AMP_PESSDesignSetting : 4|3@0+ (1,0) [0|0] ""  H_U
   SG_ AMP_PESSAPSSetting : 7|3@0+ (1,0) [0|0] ""  H_U
   SG_ AMP_PESSVolumeSetting : 15|8@0+ (1,0) [0|0] ""  H_U

BO_ 389 AMP_HU_PE_05: 8 AMP
   SG_ AMP_EngOrderC2Setting : 7|8@0+ (1,0) [0|0] ""  H_U
   SG_ AMP_EngOrderC4Setting : 15|8@0+ (1,0) [0|0] ""  H_U
   SG_ AMP_EngOrderC6Setting : 23|8@0+ (1,0) [0|0] ""  H_U
   SG_ AMP_APSBand0Setting : 31|8@0+ (1,0) [0|0] ""  H_U
   SG_ AMP_APSBand1Setting : 39|8@0+ (1,0) [0|0] ""  H_U
   SG_ AMP_APSBand2Setting : 47|8@0+ (1,0) [0|0] ""  H_U
   SG_ AMP_APSBand3Setting : 55|8@0+ (1,0) [0|0] ""  H_U
   SG_ AMP_APSBand4Setting : 63|8@0+ (1,0) [0|0] ""  H_U

BO_ 399 EMS_H12: 8 EMS
   SG_ R_TqAcnApvC : 0|8@1+ (0.2,0.0) [0.0|51.0] "Nm"  DATC,IBOX
   SG_ R_PAcnC : 8|8@1+ (125.0,0.0) [0.0|31875.0] "hPa"  DATC,IBOX
   SG_ TQI_B : 16|8@1+ (0.390625,0.0) [0.0|99.609375] "%"  ABS,ESC,IBOX
   SG_ SLD_VS : 24|8@1+ (1.0,0.0) [0.0|255.0] "km/h"  CLU,IBOX
   SG_ CF_CdaStat : 32|3@1+ (1.0,0.0) [0.0|7.0] ""  AEMC,IBOX,TCU
   SG_ CF_Ems_IsgStat : 35|3@1+ (1.0,0.0) [0.0|7.0] ""  ABS,BCM,CLU,DATC,EPB,ESC,IBOX,LDWS_LKAS,MDPS,SMK,TCU
   SG_ CF_Ems_OilChg : 38|1@1+ (1.0,0.0) [0.0|1.0] ""  CLU,IBOX
   SG_ CF_Ems_EtcLimpMod : 39|1@1+ (1.0,0.0) [0.0|1.0] ""  CLU,IBOX
   SG_ R_NEngIdlTgC : 40|8@1+ (10.0,0.0) [0.0|2550.0] "rpm"  DATC,IBOX,TCU
   SG_ CF_Ems_UpTarGr : 48|1@1+ (1.0,0.0) [0.0|1.0] ""  CLU,IBOX
   SG_ CF_Ems_DownTarGr : 49|1@1+ (1.0,0.0) [0.0|1.0] ""  CLU,IBOX
   SG_ CF_Ems_DesCurGr : 50|4@1+ (1.0,0.0) [0.0|15.0] ""  CLU,IBOX
   SG_ CF_Ems_SldAct : 54|1@1+ (1.0,0.0) [0.0|1.0] ""  CLU,IBOX
   SG_ CF_Ems_SldPosAct : 55|1@1+ (1.0,0.0) [0.0|1.0] ""  CLU,IBOX
   SG_ CF_Ems_HPresStat : 56|1@1+ (1.0,0.0) [0.0|1.0] ""  IBOX,TCU
   SG_ CF_Ems_IsgBuz : 57|1@1+ (1.0,0.0) [0.0|1.0] ""  CLU,IBOX
   SG_ CF_Ems_IdlStpFCO : 58|1@1+ (1.0,0.0) [0.0|1.0] ""  CLU,IBOX
   SG_ CF_Ems_FCopen : 59|1@1+ (1.0,0.0) [0.0|1.0] ""  CLU,IBOX
   SG_ CF_Ems_ActEcoAct : 60|1@1+ (1.0,0.0) [0.0|1.0] ""  CLU,IBOX,TCU
   SG_ CF_Ems_EngRunNorm : 61|1@1+ (1.0,0.0) [0.0|1.0] ""  ABS,ESC,IBOX,TCU
   SG_ CF_Ems_IsgStat2 : 62|2@1+ (2.0,0.0) [0.0|3.0] ""  CLU,IBOX,TCU

BO_ 405 HU_CLU_PE_03: 8 H_U
   SG_ HU_IntegPresetNum : 7|8@0+ (1,0) [0|0] ""  AMP,CLU,HUD
   SG_ Radio_Area : 10|8@0+ (1,0) [0|0] ""  CLU
   SG_ DMB_PresetNo : 29|5@0+ (1,0) [0|0] ""  CLU
   SG_ RADIO_PresetNo : 18|5@0+ (1,0) [0|0] ""  CLU
   SG_ HU_Opstate_DIS2 : 38|7@0+ (1,0) [0|0] ""  AMP,CLU,HUD

BO_ 406 HU_CLU_PE_04: 8 H_U
   SG_ C_SDARS_ChannelNo : 7|8@0+ (1,0) [0|0] ""  CLU
   SG_ C_NaviRouteGuidance : 11|2@0+ (1,0) [0|0] ""  CLU
   SG_ HD_SPS_ChannelNo : 15|4@0+ (1,0) [0|0] ""  CLU
   SG_ C_SDARS_PresetNo : 19|4@0+ (1,0) [0|0] ""  CLU
   SG_ DAB_ServiceFollowing : 21|2@0+ (1,0) [0|0] ""  CLU
   SG_ SXM_ChannelNo : 25|10@0+ (1,0) [0|999] ""  AMP,CLU,HUD

BO_ 407 HU_CLU_PE_05: 8 H_U
   SG_ HU_LanguageInfo : 7|8@0+ (1,0) [0|0] ""  CLU,HUD
   SG_ HU_MuteStatus : 9|2@0+ (1,0) [0|0] ""  CLU,HUD
   SG_ HU_VolumeStatus : 15|6@0+ (1,0) [0|0] ""  CLU,HUD
   SG_ HU_NaviDisp : 17|2@0+ (1,0) [0|0] ""  CLU,HUD
   SG_ HU_NaviStatus : 19|2@0+ (1,0) [0|0] ""  CGW,CLU,HUD,IPM
   SG_ HU_DistanceUnit : 21|2@0+ (1,0) [0|0] ""  CLU,HUD
   SG_ HU_Navigation_On_Off : 23|2@0+ (1,0) [0|0] ""  AVM,CGW,CLU,DATC,HUD,IPM

BO_ 410 HU_CLU_PE_08: 8 H_U
   SG_ VCDC_SelDiscNo : 11|4@0+ (1,0) [0|0] ""  CLU
   SG_ VCDC_TrackChapterNo : 7|10@0+ (1,0) [0|0] ""  CLU
   SG_ VCDC_PlayTime : 23|24@0+ (1,0) [0|0] ""  CLU
   SG_ MLT_PlayTime : 47|24@0+ (1,0) [0|0] ""  CLU

BO_ 432 TMU_GW_PE_01: 8 TMU
   SG_ C_DATCOnOffReq : 1|2@0+ (1,0) [0|0] ""  CGW,CLU,DATC,H_U,IPM
   SG_ C_DATCTempUnit : 3|2@0+ (1,0) [0|0] ""  CGW,CLU,DATC,H_U,IPM
   SG_ C_DATCTempSet : 15|8@0+ (1,0) [0|0] ""  CGW,CLU,DATC,H_U,IPM
   SG_ TMU_IVRActivity : 33|2@0+ (1,0) [0|0] ""  CGW,CLU,DATC,H_U,IPM
   SG_ TMU_PhoneActivity : 35|2@0+ (1,0) [0|0] ""  CGW,CLU,DATC,H_U,IPM

BO_ 448 HU_DATC_PE_00: 8 H_U
   SG_ DATC_AqsLevelChg : 3|4@0+ (1,0) [0|0] ""  CGW,CLU,DATC,IPM
   SG_ RSELockOnOff : 7|2@0+ (1,0) [0|0] ""  CGW,DATC,IPM,RRC
   SG_ DATC_AqsMode : 9|2@0+ (1,0) [0|0] ""  CGW,CLU,DATC,IPM
   SG_ HU_Graphreset_Info : 17|2@0+ (1,0) [0|0] ""  CGW,CLU,DATC,IPM
   SG_ HU_VRActivity : 33|2@0+ (1,0) [0|0] ""  CGW,CLU,DATC,IPM
   SG_ HU_PhoneActivity : 35|2@0+ (1,0) [0|0] ""  CGW,CLU,DATC,IPM
   SG_ BlowerNoiseControl : 37|2@0+ (1,0) [0|0] ""  CGW,CLU,DATC,IPM

BO_ 465 CLU_HU_PE_03: 8 CLU
   SG_ CF_Clu_EVDTEDisp : 0|9@0+ (1,0) [0|0] ""  H_U,IBOX
   SG_ CF_Clu_GasDTEDisp : 17|10@0+ (1,0) [0|0] ""  H_U,IBOX
   SG_ MM_CR_Clu_TotalDTEDisp : 34|11@0+ (1,0) [0|0] ""  H_U,IBOX
   SG_ CF_Clu_TripUnit : 49|2@0+ (1,0) [0|0] ""  H_U,IBOX

BO_ 474 CLU_HU_PE_02: 8 CLU
   SG_ CF_Clu_AvgFCU : 1|2@0+ (1,0) [0|0] ""  H_U
   SG_ CF_Clu_AvgFCL : 9|10@0+ (1,0) [0|0] ""  H_U
   SG_ CF_Clu_TermAvgSync : 25|2@0+ (1,0) [0|0] ""  H_U
   SG_ CF_Clu_EcoDriveInf : 36|3@0+ (1,0) [0|0] ""  H_U
   SG_ CR_Clu_TermAvgFCI : 33|10@0+ (1,0) [0|0] ""  H_U
   SG_ CF_CLU_EcoScore : 55|16@0+ (1,0) [0|0] ""  H_U

BO_ 479 CLU_HU_PE_01: 8 CLU
   SG_ CLU_Type : 7|8@0+ (1,0) [0|0] ""  H_U
   SG_ CLU_Region : 15|8@0+ (1,0) [0|0] ""  H_U
   SG_ CLU_VersionMinor : 23|8@0+ (1,0) [0|0] ""  H_U
   SG_ CLU_VersionMajor : 31|8@0+ (1,0) [0|0] ""  H_U
   SG_ CLU_CurrentDispState : 39|8@0+ (1,0) [0|0] ""  H_U
   SG_ C_DRVDRSW : 41|2@0+ (1,0) [0|0] ""  H_U
   SG_ CF_Clu_LowfuelWarning : 44|2@0+ (1,0) [0|0] ""  H_U
   SG_ CLU_PowerInfo : 46|2@0+ (1,0) [0|0] ""  H_U
   SG_ C_DrivingModeState : 50|3@0+ (1,0) [0|0] ""  H_U
   SG_ Clu_RheostatLvl : 55|5@0+ (1,0) [0|0] ""  H_U,MON,SWRC
   SG_ C_Clu_ActiveEcoSW : 57|2@0+ (1,0) [0|0] ""  H_U
   SG_ C_Detent : 59|2@0+ (1,0) [0|0] ""  CCP,CLOCK,H_U,KBD,MON,RRC,RSE_L,RSE_R
   SG_ C_DrivingModeOn : 61|2@0+ (1,0) [0|0] ""  H_U

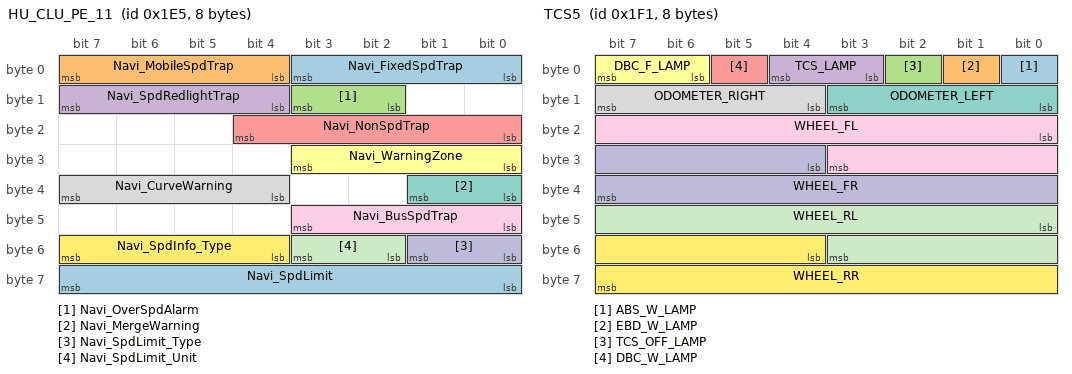
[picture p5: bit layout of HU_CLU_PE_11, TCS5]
BO_ 485 HU_CLU_PE_11: 8 H_U
   SG_ Navi_FixedSpdTrap : 3|4@0+ (10,0) [10|110] "Km/h"  CLU,HUD
   SG_ Navi_MobileSpdTrap : 7|4@0+ (10,0) [10|110] "Km/h"  CLU,HUD
   SG_ Navi_OverSpdAlarm : 11|2@0+ (1,0) [0|0] ""  CGW,CLU,HUD
   SG_ Navi_SpdRedlightTrap : 15|4@0+ (10,0) [10|110] "Km/h"  CLU,HUD
   SG_ Navi_NonSpdTrap : 20|5@0+ (1,0) [0|0] ""  CLU,HUD
   SG_ Navi_WarningZone : 27|4@0+ (1,0) [0|0] ""  CLU,HUD
   SG_ Navi_MergeWarning : 33|2@0+ (1,0) [0|0] ""  CLU,HUD
   SG_ Navi_CurveWarning : 39|4@0+ (1,0) [0|0] ""  CLU,HUD
   SG_ Navi_BusSpdTrap : 43|4@0+ (10,0) [10|110] "Km/h"  CLU,HUD
   SG_ Navi_SpdLimit_Type : 49|2@0+ (1,0) [0|0] ""  CLU,HUD
   SG_ Navi_SpdLimit_Unit : 51|2@0+ (1,0) [0|0] ""  CLU,HUD
   SG_ Navi_SpdInfo_Type : 55|4@0+ (1,0) [0|0] ""  CLU,HUD
   SG_ Navi_SpdLimit : 63|8@0+ (1,0) [1|254] ""  CLU,HUD

BO_ 486 HU_CLU_PE_12: 8 H_U
   SG_ Navi_DistToDest_I : 7|16@0+ (1,0) [0|0] ""  CLU,HUD
   SG_ Navi_DistToDest_F : 19|4@0+ (1,0) [0|0] ""  CLU,HUD
   SG_ Navi_DistToDest_U : 23|4@0+ (1,0) [0|0] ""  CLU,HUD
   SG_ Navi_EstimHour : 31|8@0+ (1,0) [0|254] "hh"  CLU,HUD
   SG_ Navi_EstimMin : 37|6@0+ (1,0) [0|59] "mm"  CLU,HUD
   SG_ Navi_EstimTimeType : 39|2@0+ (1,0) [0|0] ""  CLU,HUD
   SG_ Navi_Compass : 45|6@0+ (7.5,-7.5) [0|352.5] "Degree"  CLU,HUD

BO_ 487 HU_CLU_PE_13: 8 H_U
   SG_ Navi_DistToPoint1_F : 11|4@0+ (1,0) [0|0] ""  CLU,HUD
   SG_ Navi_DistToPoint1_I : 7|12@0+ (1,0) [0|0] ""  CLU,HUD
   SG_ Navi_DistToPoint1_U : 23|4@0+ (1,0) [0|0] ""  CLU,HUD
   SG_ Navi_DistToPoint2_I : 19|12@0+ (1,0) [0|0] ""  CLU,HUD
   SG_ Navi_DistToPoint2_F : 35|4@0+ (1,0) [0|0] ""  CLU,HUD
   SG_ Navi_DistToPoint2_U : 39|4@0+ (1,0) [0|0] ""  CLU,HUD
   SG_ Navi_DistToPoint3_F : 51|4@0+ (1,0) [0|0] ""  CLU,HUD
   SG_ Navi_DistToPoint3_I : 47|12@0+ (1,0) [0|0] ""  CLU,HUD
   SG_ Navi_DistToPoint3_U : 63|4@0+ (1,0) [0|0] ""  CLU,HUD

BO_ 491 GW_DDM_PE: 8 CLU
   SG_ C_DRVDoorStatus : 1|2@0+ (1,0) [0|0] ""  AMP,ASD,AVM,CCP,CGW,CLOCK,CUBIS,DATC,EDT,FHCU,HUD,H_U,IBOX,IPM,KBD,KMA_TMU,MON,RRC,RSE_L,RSE_R,SWRC,TMU
   SG_ C_ASTDoorStatus : 3|2@0+ (1,0) [0|0] ""  AMP,ASD,AVM,CCP,CGW,CLOCK,CUBIS,DATC,EDT,FHCU,HUD,H_U,IBOX,IPM,KBD,KMA_TMU,MON,RRC,RSE_L,RSE_R,SWRC,TMU
   SG_ C_RLDoorStatus : 5|2@0+ (1,0) [0|0] ""  AMP,ASD,AVM,CCP,CGW,CLOCK,CUBIS,DATC,EDT,FHCU,HUD,H_U,IBOX,IPM,KBD,KMA_TMU,MON,RRC,RSE_L,RSE_R,SWRC,TMU
   SG_ C_RRDoorStatus : 7|2@0+ (1,0) [0|0] ""  AMP,ASD,AVM,CCP,CGW,CLOCK,CUBIS,DATC,EDT,FHCU,HUD,H_U,IBOX,IPM,KBD,KMA_TMU,MON,RRC,RSE_L,RSE_R,SWRC,TMU
   SG_ C_TrunkStatus : 9|2@0+ (1,0) [0|0] ""  AMP,ASD,AVM,CCP,CGW,CLOCK,CUBIS,DATC,EDT,FHCU,HUD,H_U,IBOX,IPM,KBD,KMA_TMU,MON,RRC,RSE_L,RSE_R,SWRC,TMU
   SG_ C_OSMirrorStatus : 11|2@0+ (1,0) [0|0] ""  AMP,ASD,AVM,CCP,CGW,CLOCK,CUBIS,DATC,EDT,FHCU,HUD,H_U,IBOX,IPM,KBD,KMA_TMU,MON,RRC,RSE_L,RSE_R,SWRC,TMU

BO_ 497 TCS5: 8 XXX
   SG_ ABS_W_LAMP : 0|1@1+ (1,0) [0|1] "" XXX
   SG_ EBD_W_LAMP : 1|1@1+ (1,0) [0|1] "" XXX
   SG_ TCS_OFF_LAMP : 2|1@1+ (1,0) [0|1] "" XXX
   SG_ TCS_LAMP : 3|2@1+ (1,0) [0|3] "" XXX
   SG_ DBC_W_LAMP : 5|1@1+ (1,0) [0|1] "" XXX
   SG_ DBC_F_LAMP : 6|2@1+ (1,0) [0|3] "" XXX
   SG_ ODOMETER_LEFT : 8|4@1+ (1,0) [0|15] "m" XXX
   SG_ ODOMETER_RIGHT : 12|4@1+ (1,0) [0|15] "m" XXX
   SG_ WHEEL_FL : 16|12@1+ (0.125,0) [0|511.875] "km/h" XXX
   SG_ WHEEL_FR : 28|12@1+ (0.125,0) [0|511.875] "km/h" XXX
   SG_ WHEEL_RL : 40|12@1+ (0.125,0) [0|511.875] "km/h" XXX
   SG_ WHEEL_RR : 52|12@1+ (0.125,0) [0|511.875] "km/h" XXX

BO_ 512 EMS20: 6 EMS
   SG_ FCO : 0|16@1+ (0.128,0.0) [0.0|8388.48] "ul"  CLU,CUBIS,FPCM,IBOX
   SG_ CF_Ems_PumpTPres : 16|8@1+ (3.137254902,0.0) [0.0|800.0] "kPa"  FPCM,IBOX
   SG_ Split_Stat : 32|1@1+ (1.0,0.0) [0.0|1.0] ""  FPCM

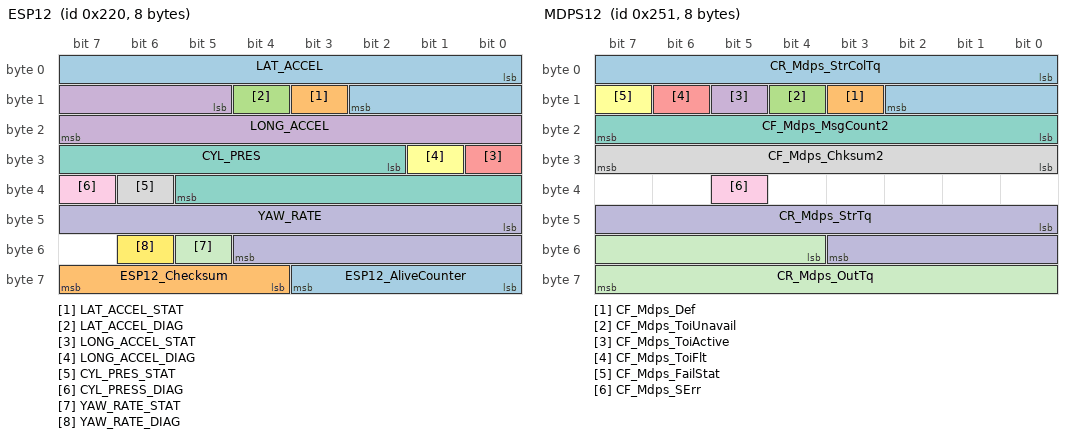
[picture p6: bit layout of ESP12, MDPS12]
BO_ 544 ESP12: 8 ESC
   SG_ LAT_ACCEL : 0|11@1+ (0.01,-10.23) [-10.23|10.24] "m/s^2"  _4WD,ECS,IBOX,LCA,LDWS_LKAS,MDPS,PSB,SCC,TCU
   SG_ LAT_ACCEL_STAT : 11|1@1+ (1.0,0.0) [0.0|1.0] ""  _4WD,IBOX,LDWS_LKAS,MDPS,PSB,SCC,TCU
   SG_ LAT_ACCEL_DIAG : 12|1@1+ (1.0,0.0) [0.0|1.0] ""  _4WD,IBOX,LDWS_LKAS,MDPS,PSB,SCC,TCU
   SG_ LONG_ACCEL : 13|11@1+ (0.01,-10.23) [-10.23|10.24] "m/s^2"  _4WD,ECS,EMS,EPB,IBOX,LCA,LDWS_LKAS,PSB,SCC,SPAS,TCU
   SG_ LONG_ACCEL_STAT : 24|1@1+ (1.0,0.0) [0.0|1.0] ""  _4WD,EMS,EPB,IBOX,LDWS_LKAS,PSB,SCC,SPAS,TCU
   SG_ LONG_ACCEL_DIAG : 25|1@1+ (1.0,0.0) [0.0|1.0] ""  _4WD,EMS,EPB,IBOX,LDWS_LKAS,PSB,SCC,SPAS,TCU
   SG_ CYL_PRES : 26|12@1+ (0.1,0.0) [0.0|409.5] "Bar"  _4WD,ECS,EMS,EPB,IBOX,LDWS_LKAS,PSB,SCC,TCU
   SG_ CYL_PRES_STAT : 38|1@1+ (1.0,0.0) [0.0|1.0] ""  _4WD,ECS,EMS,EPB,IBOX,LDWS_LKAS,PSB,SCC,TCU
   SG_ CYL_PRESS_DIAG : 39|1@1+ (1.0,0.0) [0.0|1.0] ""  _4WD,ECS,EMS,EPB,IBOX,PSB,SCC,TCU
   SG_ YAW_RATE : 40|13@1+ (0.01,-40.95) [-40.95|40.96] ""  _4WD,AFLS,IBOX,LCA,LDWS_LKAS,MDPS,PSB,SCC,SPAS,TCU
   SG_ YAW_RATE_STAT : 53|1@1+ (1.0,0.0) [0.0|1.0] ""  _4WD,AFLS,IBOX,LCA,LDWS_LKAS,MDPS,PSB,SCC,SPAS,TCU
   SG_ YAW_RATE_DIAG : 54|1@1+ (1.0,0.0) [0.0|1.0] ""  _4WD,AFLS,IBOX,LCA,LDWS_LKAS,MDPS,PSB,SCC,SPAS,TCU
   SG_ ESP12_AliveCounter : 56|4@1+ (1.0,0.0) [0.0|15.0] ""  _4WD,EMS,LPI,TCU,TMU
   SG_ ESP12_Checksum : 60|4@1+ (1.0,0.0) [0.0|15.0] ""  _4WD,EMS,LPI,TCU,TMU

BO_ 593 MDPS12: 8 MDPS
   SG_ CR_Mdps_StrColTq : 0|11@1+ (0.0078125,-8.0) [-8.0|7.9921875] "Nm"  LDWS_LKAS
   SG_ CF_Mdps_Def : 11|1@1+ (1.0,0.0) [0.0|1.0] ""  ESC
   SG_ CF_Mdps_ToiUnavail : 12|1@1+ (1.0,0.0) [0.0|1.0] ""  LDWS_LKAS
   SG_ CF_Mdps_ToiActive : 13|1@1+ (1.0,0.0) [0.0|1.0] ""  LDWS_LKAS
   SG_ CF_Mdps_ToiFlt : 14|1@1+ (1.0,0.0) [0.0|1.0] ""  LDWS_LKAS
   SG_ CF_Mdps_FailStat : 15|1@1+ (1.0,0.0) [0.0|1.0] ""  LDWS_LKAS
   SG_ CF_Mdps_MsgCount2 : 16|8@1+ (1.0,0.0) [0.0|255.0] ""  ESC,LDWS_LKAS
   SG_ CF_Mdps_Chksum2 : 24|8@1+ (1.0,0.0) [0.0|255.0] ""  ESC,LDWS_LKAS
   SG_ CF_Mdps_SErr : 37|1@1+ (1.0,0.0) [0.0|1.0] ""  ESC
   SG_ CR_Mdps_StrTq : 40|12@1+ (0.01,-20.48) [-20.48|20.47] "Nm"  ESC
   SG_ CR_Mdps_OutTq : 52|12@1+ (0.1,-204.8) [-204.8|204.7] ""  ESC,LDWS_LKAS

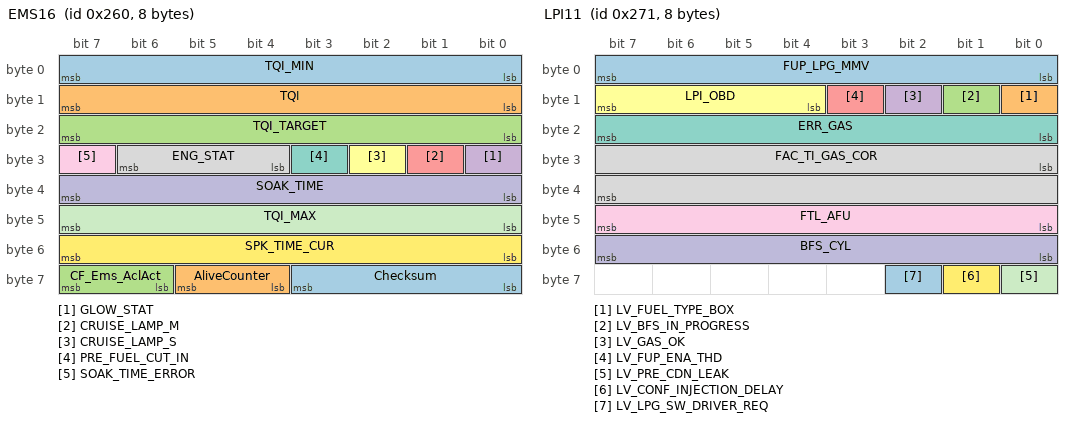
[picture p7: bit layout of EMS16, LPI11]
BO_ 608 EMS16: 8 EMS
   SG_ TQI_MIN : 0|8@1+ (0.390625,0.0) [0.0|99.609375] "%"  ESC,IBOX,TCU
   SG_ TQI : 8|8@1+ (0.390625,0.0) [0.0|99.609375] "%"  ESC,IBOX,TCU
   SG_ TQI_TARGET : 16|8@1+ (0.390625,0.0) [0.0|99.609375] "%"  EPB,ESC,IBOX,TCU
   SG_ GLOW_STAT : 24|1@1+ (1.0,0.0) [0.0|1.0] ""  BCM,CLU,IBOX,SMK
   SG_ CRUISE_LAMP_M : 25|1@1+ (1.0,0.0) [0.0|1.0] ""  CLU,IBOX,TCU
   SG_ CRUISE_LAMP_S : 26|1@1+ (1.0,0.0) [0.0|1.0] ""  CLU,IBOX,TCU
   SG_ PRE_FUEL_CUT_IN : 27|1@1+ (1.0,0.0) [0.0|1.0] ""  IBOX,TCU
   SG_ ENG_STAT : 28|3@1+ (1.0,0.0) [0.0|7.0] ""  ABS,AHLS,AVM,BCM,CLU,EPB,ESC,EVP,FPCM,IBOX,LCA,LDWS_LKAS,MDPS,SCC,SMK,TCU
   SG_ SOAK_TIME_ERROR : 31|1@1+ (1.0,0.0) [0.0|1.0] ""  DATC,EPB,IBOX,TCU
   SG_ SOAK_TIME : 32|8@1+ (1.0,0.0) [0.0|255.0] "Min"  _4WD,DATC,EPB,IBOX,TCU
   SG_ TQI_MAX : 40|8@1+ (0.390625,0.0) [0.0|99.609375] "%"  ESC,IBOX,TCU
   SG_ SPK_TIME_CUR : 48|8@1+ (0.375,-35.625) [-35.625|60.0] ""  IBOX,TCU
   SG_ Checksum : 56|4@1+ (1.0,0.0) [0.0|15.0] ""  ECS,IBOX,LDWS_LKAS,MDPS,SCC
   SG_ AliveCounter : 60|2@1+ (1.0,0.0) [0.0|3.0] ""  IBOX,LDWS_LKAS,MDPS,SCC
   SG_ CF_Ems_AclAct : 62|2@1+ (1.0,0.0) [0.0|3.0] ""  IBOX,SCC

BO_ 625 LPI11: 8 LPI
   SG_ FUP_LPG_MMV : 0|8@1+ (128.0,0.0) [0.0|32640.0] "hPa"  EMS
   SG_ LV_FUEL_TYPE_BOX : 8|1@1+ (1.0,0.0) [0.0|1.0] ""  EMS
   SG_ LV_BFS_IN_PROGRESS : 9|1@1+ (1.0,0.0) [0.0|1.0] ""  EMS
   SG_ LV_GAS_OK : 10|1@1+ (1.0,0.0) [0.0|1.0] ""  EMS
   SG_ LV_FUP_ENA_THD : 11|1@1+ (1.0,0.0) [0.0|1.0] ""  BCM,CLU,EMS,SMK
   SG_ LPI_OBD : 12|4@1+ (1.0,0.0) [0.0|15.0] ""  EMS
   SG_ ERR_GAS : 16|8@1+ (1.0,0.0) [0.0|255.0] ""  EMS
   SG_ FAC_TI_GAS_COR : 24|16@1+ (3.05E-5,0.0) [0.0|1.9988175] ""  EMS
   SG_ FTL_AFU : 40|8@1+ (0.392,0.0) [0.0|99.96] "%"  EMS
   SG_ BFS_CYL : 48|8@1+ (1.0,0.0) [0.0|6.0] "Cyl Nr."  EMS
   SG_ LV_PRE_CDN_LEAK : 56|1@1+ (1.0,0.0) [0.0|1.0] ""  EMS
   SG_ LV_CONF_INJECTION_DELAY : 57|1@1+ (1.0,0.0) [0.0|1.0] ""  EMS
   SG_ LV_LPG_SW_DRIVER_REQ : 58|1@1+ (1.0,0.0) [0.0|1.0] ""  EMS

BO_ 640 EMS13: 8 EMS
   SG_ LV_FUEL_TYPE_ECU : 0|1@1+ (1.0,0.0) [0.0|1.0] ""  BCM,CLU,LPI,SMK
   SG_ LV_BFS_CFIRM : 1|1@1+ (1.0,0.0) [0.0|1.0] ""  LPI
   SG_ LV_CRASH : 2|1@1+ (1.0,0.0) [0.0|1.0] ""  LPI
   SG_ LV_VB_OFF_ACT : 3|1@1+ (1.0,0.0) [0.0|1.0] ""  LPI
   SG_ LV_GSL_MAP M : 4|1@1+ (1.0,0.0) [0.0|1.0] ""  LPI
   SG_ LV_ENG_TURN : 5|1@1+ (1.0,0.0) [0.0|1.0] ""  LPI
   SG_ ERR_FUEL : 8|8@1+ (1.0,0.0) [0.0|255.0] ""  LPI
   SG_ EOS : 16|8@1+ (1.0,0.0) [0.0|255.0] ""  LPI
   SG_ TCO : 24|8@1+ (0.75,-48.0) [-48.0|143.25] "deg"  LPI
   SG_ N_32 : 32|8@1+ (32.0,0.0) [0.0|8160.0] "rpm"  LPI
   SG_ MAF : 40|8@1+ (5.447,0.0) [0.0|1388.985] "mg/TDC"  LPI
   SG_ TIA : 48|8@1+ (0.75,-48.0) [-48.0|143.25] "deg"  LPI
   SG_ MAP m1 : 56|8@1+ (0.47058,0.0) [0.0|119.9979] "kPa"  LPI
   SG_ AMP m0 : 56|8@1+ (21.22,0.0) [0.0|5411.1] "hPa"  LPI

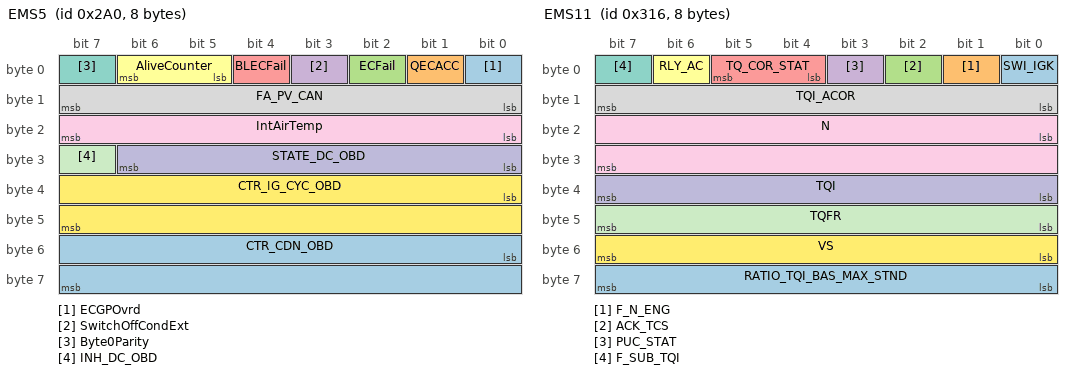
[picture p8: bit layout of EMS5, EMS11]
BO_ 672 EMS5: 8 XXX
   SG_ ECGPOvrd : 0|1@1+ (1,0) [0|1] "" XXX
   SG_ QECACC : 1|1@1+ (1,0) [0|1] "" XXX
   SG_ ECFail : 2|1@1+ (1,0) [0|1] "" XXX
   SG_ SwitchOffCondExt : 3|1@1+ (1,0) [0|1] "" XXX
   SG_ BLECFail : 4|1@1+ (1,0) [0|1] "" XXX
   SG_ AliveCounter : 5|2@1+ (1,0) [0|3] "" XXX
   SG_ Byte0Parity : 7|1@1+ (1,0) [0|1] "" XXX
   SG_ FA_PV_CAN : 8|8@1+ (0.3906,0) [0|99.2] "%" XXX
   SG_ IntAirTemp : 16|8@1+ (0.75,-48) [-48|143.25] "" XXX
   SG_ STATE_DC_OBD : 24|7@1+ (1,0) [0|127] "" XXX
   SG_ INH_DC_OBD : 31|1@1+ (1,0) [0|1] "" XXX
   SG_ CTR_IG_CYC_OBD : 32|16@1+ (1,0) [0|65535] "" XXX
   SG_ CTR_CDN_OBD : 48|16@1+ (1,0) [0|65535] "" XXX

BO_ 688 SAS11: 5 MDPS
   SG_ SAS_Angle : 0|16@1- (0.1,0.0) [-3276.8|3276.7] "Deg"  _4WD,ACU,AFLS,AVM,CLU,ECS,EMS,ESC,IBOX,LCA,LDWS_LKAS,PGS,PSB,SCC,SPAS,TCU,_4WD,ACU,AFLS,AVM,BCM,CLU,ECS,EMS,ESC,IBOX,LCA,LDWS_LKAS,PGS,PSB,SCC,SPAS,TCU
   SG_ SAS_Speed : 16|8@1+ (4.0,0.0) [0.0|1016.0] ""  AFLS,ECS,ESC,IBOX,LDWS_LKAS,SCC,SPAS,TCU,AFLS,ECS,ESC,IBOX,LDWS_LKAS,SCC,SPAS,TCU
   SG_ SAS_Stat : 24|8@1+ (1.0,0.0) [0.0|255.0] ""  ECS,ESC,IBOX,LDWS_LKAS,PSB,SCC,SPAS,TCU,ECS,ESC,IBOX,LDWS_LKAS,PSB,SCC,SPAS,TCU
   SG_ MsgCount : 32|4@1+ (1.0,0.0) [0.0|15.0] ""  ECS,ESC,IBOX,LDWS_LKAS,PSB,SCC,SPAS,ECS,ESC,IBOX,LDWS_LKAS,PSB,SCC,SPAS
   SG_ CheckSum : 36|4@1+ (1.0,0.0) [0.0|15.0] ""  ECS,EMS,ESC,IBOX,LDWS_LKAS,PSB,SCC,SPAS,ECS,EMS,ESC,IBOX,LDWS_LKAS,PSB,SCC,SPAS

BO_ 790 EMS11: 8 EMS
   SG_ SWI_IGK : 0|1@1+ (1.0,0.0) [0.0|1.0] ""  _4WD,ABS,ACU,AHLS,CUBIS,DI_BOX,ECS,EPB,ESC,IBOX,LDWS_LKAS,MDPS,REA,SAS,SCC,TCU
   SG_ F_N_ENG : 1|1@1+ (1.0,0.0) [0.0|1.0] ""  _4WD,ACU,AFLS,CLU,CUBIS,DATC,ECS,EPB,ESC,IBOX,MDPS,SCC,TCU
   SG_ ACK_TCS : 2|1@1+ (1.0,0.0) [0.0|1.0] ""  ESC,IBOX
   SG_ PUC_STAT : 3|1@1+ (1.0,0.0) [0.0|1.0] ""  _4WD,CLU,DATC,IBOX,TCU
   SG_ TQ_COR_STAT : 4|2@1+ (1.0,0.0) [0.0|3.0] ""  _4WD,ESC,IBOX,TCU
   SG_ RLY_AC : 6|1@1+ (1.0,0.0) [0.0|1.0] ""  DATC,IBOX,TCU
   SG_ F_SUB_TQI : 7|1@1+ (1.0,0.0) [0.0|1.0] ""  _4WD,ECS,EPB,ESC,IBOX,TCU
   SG_ TQI_ACOR : 8|8@1+ (0.390625,0.0) [0.0|99.6094] "%"  _4WD,EPB,ESC,IBOX,TCU
   SG_ N : 16|16@1+ (0.25,0.0) [0.0|16383.75] "rpm"  _4WD,ACU,AFLS,CLU,CUBIS,DATC,ECS,EPB,ESC,FPCM,IBOX,MDPS,SCC,TCU
   SG_ TQI : 32|8@1+ (0.390625,0.0) [0.0|99.6094] "%"  _4WD,ECS,EPB,ESC,IBOX,TCU
   SG_ TQFR : 40|8@1+ (0.390625,0.0) [0.0|99.6094] "%"  _4WD,EPB,ESC,IBOX,TCU
   SG_ VS : 48|8@1+ (1.0,0.0) [0.0|254.0] "km/h"  _4WD,AAF,ACU,AHLS,BCM,CLU,DATC,ECS,EPB,IBOX,LCA,LDWS_LKAS,LVR,MDPS,ODS,SCC,SMK,SPAS,TCU,TPMS
   SG_ RATIO_TQI_BAS_MAX_STND : 56|8@1+ (0.0078,0.0) [0.0|2.0] ""  _4WD,IBOX,TCU

BO_ 809 EMS12: 8 EMS
   SG_ CONF_TCU m1 : 0|6@1+ (1.0,0.0) [0.0|63.0] ""  _4WD,ACU,BCM,CLU,DATC,EPB,ESC,IBOX,LCA,SMK
   SG_ CAN_VERS m0 : 0|6@1+ (1.0,0.0) [0.0|7.7] ""  _4WD,ABS,ESC,IBOX
   SG_ TQ_STND m3 : 0|6@1+ (10.0,0.0) [0.0|630.0] "Nm"  _4WD,DATC,ECS,EPB,ESC,FATC,IBOX
   SG_ OBD_FRF_ACK m2 : 0|6@1+ (1.0,0.0) [0.0|63.0] ""  _4WD,ESC,IBOX
   SG_ MUL_CODE M : 6|2@1+ (1.0,0.0) [0.0|3.0] ""  _4WD,ABS,ACU,BCM,CLU,DATC,ECS,EPB,ESC,IBOX,LCA,SMK,TCU
   SG_ TEMP_ENG : 8|8@1+ (0.75,-48.0) [-48.0|143.25] "deg"  _4WD,BCM,CLU,DATC,EPB,ESC,IBOX,SMK,TCU
   SG_ MAF_FAC_ALTI_MMV : 16|8@1+ (0.00781,0.0) [0.0|1.99155] ""  IBOX,TCU
   SG_ VB_OFF_ACT : 24|1@1+ (1.0,0.0) [0.0|1.0] ""  IBOX,TCU
   SG_ ACK_ES : 25|1@1+ (1.0,0.0) [0.0|1.0] ""  _4WD,ACU,IBOX
   SG_ CONF_MIL_FMY : 26|3@1+ (1.0,0.0) [0.0|7.0] ""  ESC,IBOX,TCU
   SG_ OD_OFF_REQ : 29|1@1+ (1.0,0.0) [0.0|1.0] ""  IBOX,TCU
   SG_ ACC_ACT : 30|1@1+ (1.0,0.0) [0.0|1.0] ""  _4WD,ABS,CLU,ESC,IAP,IBOX,SCC,TCU
   SG_ CLU_ACK : 31|1@1+ (1.0,0.0) [0.0|1.0] ""  _4WD,EPB,ESC,IBOX
   SG_ BRAKE_ACT : 32|2@1+ (1.0,0.0) [0.0|3.0] ""  _4WD,ABS,ACU,AFLS,CLU,DATC,ECS,EPB,ESC,IBOX,LDWS_LKAS,TCU
   SG_ ENG_CHR : 34|4@1+ (1.0,0.0) [0.0|15.0] ""  _4WD,ABS,ACU,CLU,DATC,EPB,ESC,FATC,IBOX,SCC,SMK,TCU
   SG_ GP_CTL : 38|2@1+ (1.0,0.0) [0.0|3.0] ""  IBOX
   SG_ TPS : 40|8@1+ (0.4694836,-15.0234742) [-15.0234742|104.6948357] "%"  _4WD,ABS,ACU,CLU,DATC,ECS,EPB,ESC,IBOX,TCU
   SG_ PV_AV_CAN : 48|8@1+ (0.3906,0.0) [0.0|99.603] "%"  _4WD,AAF,ABS,ACU,AFLS,CLU,DATC,EPB,ESC,IAP,IBOX,LDWS_LKAS,SCC,TCU
   SG_ ENG_VOL : 56|8@1+ (0.1,0.0) [0.0|25.5] "liter"  _4WD,ABS,ACU,BCM,CLU,DATC,EPB,ESC,IBOX,LDWS_LKAS,SCC,SMK

BO_ 832 LKAS11: 8 LDWS_LKAS
   SG_ CF_Lkas_Icon : 0|2@1+ (1.0,0.0) [0.0|3.0] ""  CLU,IBOX,PSB
   SG_ CF_Lkas_LdwsSysState : 2|4@1+ (1.0,0.0) [0.0|15.0] ""  CLU,IBOX,PSB
   SG_ CF_Lkas_SysWarning : 6|4@1+ (1.0,0.0) [0.0|15.0] ""  BCM,CLU
   SG_ CF_Lkas_LdwsLHWarning : 10|2@1+ (1.0,0.0) [0.0|3.0] ""  BCM,CLU,PSB
   SG_ CF_Lkas_LdwsRHWarning : 12|2@1+ (1.0,0.0) [0.0|3.0] ""  BCM,CLU,PSB
   SG_ CF_Lkas_HbaLamp : 14|1@1+ (1.0,0.0) [0.0|1.0] ""  CLU
   SG_ CF_Lkas_FcwBasReq : 15|1@1+ (1.0,0.0) [0.0|1.0] ""  ABS,ESC
   SG_ CR_Lkas_StrToqReq : 16|11@1+ (1.0,-1024.0) [-1024.0|1024.0] ""  MDPS
   SG_ CF_Lkas_ActToi : 27|1@1+ (1.0,0.0) [0.0|1.0] ""  MDPS
   SG_ CF_Lkas_ToiFlt : 28|1@1+ (1.0,0.0) [0.0|1.0] ""  MDPS
   SG_ CF_Lkas_HbaSysState : 29|3@1+ (1.0,0.0) [0.0|7.0] ""  BCM,CLU
   SG_ CF_Lkas_FcwOpt : 32|2@1+ (1.0,0.0) [0.0|3.0] ""  CLU
   SG_ CF_Lkas_HbaOpt : 34|2@1+ (1.0,0.0) [0.0|1.0] ""  BCM,CGW
   SG_ CF_Lkas_MsgCount : 36|4@1+ (1.0,0.0) [0.0|15.0] ""  CLU,MDPS
   SG_ CF_Lkas_FcwSysState : 40|3@1+ (1.0,0.0) [0.0|7.0] ""  CLU
   SG_ CF_Lkas_FcwCollisionWarning : 43|2@1+ (1.0,0.0) [0.0|3.0] ""  CLU
   SG_ CF_Lkas_FusionState : 45|2@1+ (1.0,0.0) [0.0|3.0] ""  SCC
   SG_ CF_Lkas_Chksum : 48|8@1+ (1.0,0.0) [0.0|255.0] ""  MDPS
   SG_ CF_Lkas_FcwOpt_USM : 56|3@1+ (1.0,0.0) [0.0|7.0] ""  CLU
   SG_ CF_Lkas_LdwsOpt_USM : 59|3@1+ (1.0,0.0) [0.0|7.0] ""  CLU,MDPS
   SG_ CF_Lkas_Unknown1 : 47|1@1+ (1,0) [0|3] "" XXX
   SG_ CF_Lkas_Unknown2 : 63|2@0+ (1,0) [0|3] "" XXX

BO_ 848 FATC: 8 XXX
   SG_ CR_Fatc_TqAcnOut : 0|8@1+ (0.2,0) [0|50.8] "Nm" XXX
   SG_ CF_Fatc_AcnRqSwi : 8|1@1+ (1,0) [0|1] "" XXX
   SG_ CF_Fatc_AcnCltEnRq : 9|1@1+ (1,0) [0|1] "" XXX
   SG_ CF_Fatc_EcvFlt : 10|1@1+ (1,0) [0|1] "" XXX
   SG_ CF_Fatc_BlwrOn : 11|1@1+ (1,0) [0|1] "" XXX
   SG_ CF_FATC_Iden : 12|2@1+ (1,0) [0|3] "" XXX
   SG_ CF_Fatc_BlwrMax : 14|1@1+ (1,0) [0|1] "" XXX
   SG_ CF_Fatc_EngStartReq : 15|1@1+ (1,0) [0|1] "" XXX
   SG_ CF_Fatc_IsgStopReq : 16|1@1+ (1,0) [0|1] "" XXX
   SG_ CF_Fatc_CtrInf : 17|3@1+ (1,0) [0|7] "" XXX
   SG_ CF_Fatc_MsgCnt : 20|4@1+ (1,0) [0|15] "" XXX
   SG_ CR_Fatc_OutTemp : 24|8@1+ (0.5,-40) [-40|60] "" XXX
   SG_ CR_Fatc_OutTempSns : 32|8@1+ (0.5,-40) [-40|60] "" XXX
   SG_ CF_Fatc_Compload : 40|3@1+ (1,0) [0|7] "" XXX
   SG_ CF_Fatc_ActiveEco : 43|1@1+ (1,0) [0|1] "" XXX
   SG_ CF_Fatc_AutoActivation : 44|1@1+ (1,0) [0|1] "" XXX
   SG_ CF_Fatc_DefSw : 45|1@1+ (1,0) [0|1] "" XXX
   SG_ CF_Fatc_PtcRlyStat : 46|1@1+ (1,0) [0|1] "" XXX
   SG_ CF_Fatc_ChkSum : 56|8@1+ (1,0) [0|255] "" XXX

BO_ 852 LVR11: 7 LVR
   SG_ CF_Lvr_GearInf : 0|4@1+ (1.0,0.0) [0.0|15.0] ""  CLU,TCU
   SG_ CF_Lvr_PRelStat : 4|1@1+ (1.0,0.0) [0.0|1.0] ""  BCM,CLU,SMK,TCU
   SG_ CF_Lvr_BkeAct : 5|1@1+ (1.0,0.0) [0.0|1.0] ""  TCU
   SG_ CF_Lvr_NFnStat : 6|1@1+ (1.0,0.0) [0.0|1.0] ""  CLU
   SG_ CF_Lvr_PosInf : 8|4@1+ (1.0,0.0) [0.0|15.0] ""  TCU
   SG_ CF_Lvr_PosCpl : 12|4@1+ (1.0,0.0) [0.0|15.0] ""  TCU
   SG_ CF_Lvr_UlkButStat : 18|2@1+ (1.0,0.0) [0.0|3.0] ""  TCU
   SG_ CF_Lvr_PNStat : 20|2@1+ (1.0,0.0) [0.0|3.0] ""  CLU
   SG_ CF_Lvr_ShtLkStat : 24|4@1+ (1.0,0.0) [0.0|15.0] ""  TCU
   SG_ CF_Lvr_ShfErrInf : 28|20@1+ (1.0,0.0) [0.0|8191.0] ""  CLU,TCU
   SG_ CF_Lvr_AC : 48|4@1+ (1.0,0.0) [0.0|15.0] ""  TCU
   SG_ CF_Lvr_CS : 52|4@1+ (1.0,0.0) [0.0|15.0] ""  TCU

BO_ 871 LVR12: 8 LVR
   SG_ CF_Lvr_CruiseSet : 0|8@1+ (1.0,0.0) [0.0|255.0] "" CLU,TCU
   SG_ CF_Lvr_Gear : 32|4@1+ (1.0,0.0) [0.0|15.0] ""  CLU,TCU

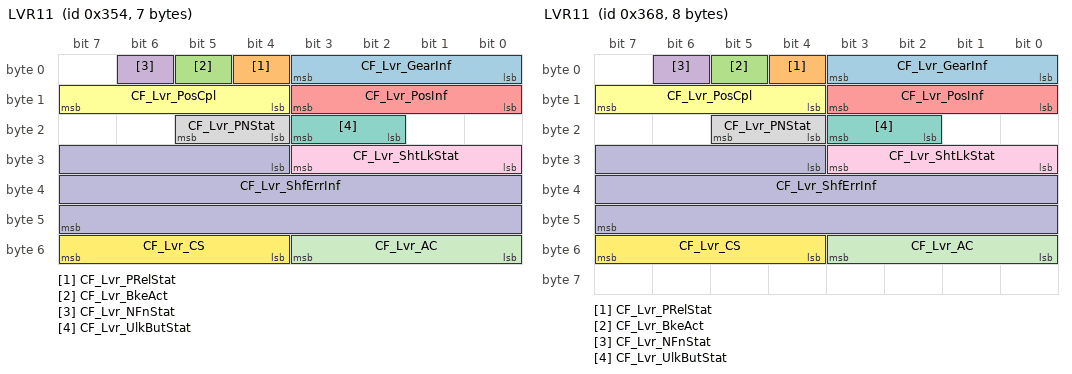
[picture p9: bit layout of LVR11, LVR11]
BO_ 872 LVR11: 8 LVR
   SG_ CF_Lvr_GearInf : 0|4@1+ (1.0,0.0) [0.0|15.0] ""  CLU,TCU
   SG_ CF_Lvr_PRelStat : 4|1@1+ (1.0,0.0) [0.0|1.0] ""  BCM,CLU,SMK,TCU
   SG_ CF_Lvr_BkeAct : 5|1@1+ (1.0,0.0) [0.0|1.0] ""  TCU
   SG_ CF_Lvr_NFnStat : 6|1@1+ (1.0,0.0) [0.0|1.0] ""  CLU
   SG_ CF_Lvr_PosInf : 8|4@1+ (1.0,0.0) [0.0|15.0] ""  TCU
   SG_ CF_Lvr_PosCpl : 12|4@1+ (1.0,0.0) [0.0|15.0] ""  TCU
   SG_ CF_Lvr_UlkButStat : 18|2@1+ (1.0,0.0) [0.0|3.0] ""  TCU
   SG_ CF_Lvr_PNStat : 20|2@1+ (1.0,0.0) [0.0|3.0] ""  CLU
   SG_ CF_Lvr_ShtLkStat : 24|4@1+ (1.0,0.0) [0.0|15.0] ""  TCU
   SG_ CF_Lvr_ShfErrInf : 28|20@1+ (1.0,0.0) [0.0|8191.0] ""  CLU,TCU
   SG_ CF_Lvr_AC : 48|4@1+ (1.0,0.0) [0.0|15.0] ""  TCU
   SG_ CF_Lvr_CS : 52|4@1+ (1.0,0.0) [0.0|15.0] ""  TCU

BO_ 880 TCU3: 8 XXX
   SG_ N_TGT_LUP : 0|8@1+ (10,500) [500|3040] "rpm" XXX
   SG_ SLOPE_TCU : 8|6@1+ (0.5,-16) [-16|15.5] "%" XXX
   SG_ CF_Tcu_InhCda : 14|1@1+ (1,0) [0|1] "" XXX
   SG_ CF_Tcu_IsgInhib : 15|1@1+ (1,0) [0|1] "" XXX
   SG_ CF_Tcu_BkeOnReq : 16|2@1+ (1,0) [0|3] "" XXX
   SG_ CF_Tcu_NCStat : 18|2@1+ (1,0) [0|3] "" XXX
   SG_ CF_Tcu_TarGr : 20|4@1+ (1,0) [0|15] "" XXX
   SG_ CF_Tcu_ShfPatt : 24|4@1+ (1,0) [0|15] "" XXX
   SG_ CF_Tcu_InhVis : 28|1@1+ (1,0) [0|1] "" XXX
   SG_ CF_Tcu_PRelReq : 29|1@1+ (1,0) [0|1] "" XXX
   SG_ CF_Tcu_ITPhase : 30|1@1+ (1,0) [0|1] "" XXX
   SG_ CF_Tcu_ActEcoRdy : 31|1@1+ (1,0) [0|1] "" XXX
   SG_ CF_Tcu_TqGrdLim : 32|8@1+ (10,0) [0|2540] "Nm/s" XXX
   SG_ CR_Tcu_IsgTgtRPM : 40|8@1+ (20,0) [0|3500] "rpm" XXX
   SG_ TQI_TCU_INC : 48|8@1+ (0.390625,0) [0|99.6094] "%" XXX
   SG_ CF_Tcu_SbwPInfo : 56|1@1+ (1,0) [0|1] "" XXX
   SG_ CF_Tcu_SptRdy : 57|1@1+ (1,0) [0|1] "" XXX
   SG_ CF_Tcu_Alive3 : 58|2@1+ (1,0) [0|3] "" XXX
   SG_ CF_Tcu_ChkSum3 : 60|4@1+ (1,0) [0|15] "" XXX

BO_ 896 DI_BOX13: 8 DI_BOX
   SG_ CF_DiBox_HPreInjVConfStat : 0|8@1+ (1.0,0.0) [0.0|255.0] ""  EMS
   SG_ CF_DiBox_HPreInjVStat1 : 8|8@1+ (1.0,0.0) [0.0|255.0] ""  EMS
   SG_ CF_DiBox_HPreInjVStat2 : 16|8@1+ (1.0,0.0) [0.0|255.0] ""  EMS
   SG_ CF_DiBox_HPreInjVPkp : 24|8@1+ (1.0,0.0) [0.0|255.0] ""  EMS
   SG_ CF_DiBox_HPreInjVBpt : 32|8@1+ (1.0,0.0) [0.0|255.0] ""  EMS
   SG_ CF_DiBox_ErrRegFrtMSV : 40|8@1+ (1.0,0.0) [0.0|255.0] ""  EMS
   SG_ CF_DiBox_ErrRegSedMSV : 48|8@1+ (1.0,0.0) [0.0|255.0] ""  EMS
   SG_ CF_DiBox_SPIErrSedMSV : 56|1@1+ (1.0,0.0) [0.0|1.0] ""  EMS
   SG_ CF_DiBox_SPIErrFrtMSV : 57|1@1+ (1.0,0.0) [0.0|1.0] ""  EMS
   SG_ CF_DiBox_IDErrSedMSV : 58|1@1+ (1.0,0.0) [0.0|1.0] ""  EMS
   SG_ CF_DiBox_IDErrFrtMSV : 59|1@1+ (1.0,0.0) [0.0|1.0] ""  EMS
   SG_ CF_DiBox_IniStatMSV : 60|1@1+ (1.0,0.0) [0.0|1.0] ""  EMS

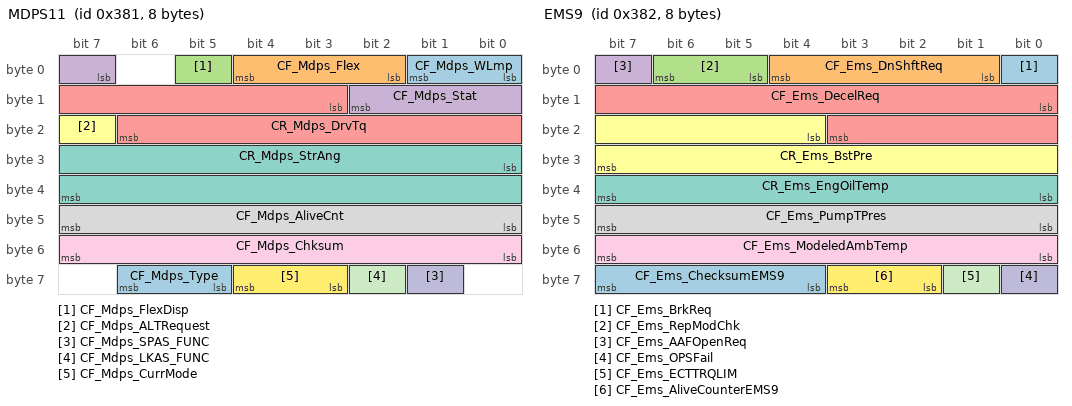
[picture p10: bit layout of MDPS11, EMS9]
BO_ 897 MDPS11: 8 MDPS
   SG_ CF_Mdps_WLmp : 0|2@1+ (1.0,0.0) [0.0|3.0] ""  CLU,CUBIS,EMS,IBOX,SPAS
   SG_ CF_Mdps_Flex : 2|3@1+ (1.0,0.0) [0.0|3.0] ""  CLU,LDWS_LKAS
   SG_ CF_Mdps_FlexDisp : 5|1@1+ (1.0,0.0) [0.0|1.0] ""  CLU
   SG_ CF_Mdps_Stat : 7|4@1+ (1.0,0.0) [0.0|15.0] ""  SPAS
   SG_ CR_Mdps_DrvTq : 11|12@1+ (0.01,-20.48) [-20.48|20.46] ""  SPAS
   SG_ CF_Mdps_ALTRequest : 23|1@1+ (1.0,0.0) [0.0|1.0] ""  EMS
   SG_ CR_Mdps_StrAng : 24|16@1- (0.1,0.0) [-3276.8|3276.7] "Deg"  SPAS
   SG_ CF_Mdps_AliveCnt : 40|8@1+ (1.0,0.0) [0.0|255.0] ""  LDWS_LKAS,SPAS
   SG_ CF_Mdps_Chksum : 48|8@1+ (1.0,0.0) [0.0|255.0] ""  LDWS_LKAS,SPAS
   SG_ CF_Mdps_SPAS_FUNC : 57|1@1+ (1.0,0.0) [0.0|1.0] "flag"  SPAS
   SG_ CF_Mdps_LKAS_FUNC : 58|1@1+ (1.0,0.0) [0.0|1.0] "flag"  LDWS_LKAS
   SG_ CF_Mdps_CurrMode : 59|2@1+ (1.0,0.0) [0.0|3.0] ""  LDWS_LKAS
   SG_ CF_Mdps_Type : 61|2@1+ (1.0,0.0) [0.0|2.0] ""  LDWS_LKAS,SPAS

BO_ 898 EMS9: 8 XXX
   SG_ CF_Ems_BrkReq : 0|1@1+ (1,0) [0|1] "" XXX
   SG_ CF_Ems_DnShftReq : 1|4@1+ (1,0) [0|14] "" XXX
   SG_ CF_Ems_RepModChk : 5|2@1+ (1,0) [0|3] "" XXX
   SG_ CF_Ems_AAFOpenReq : 7|1@1+ (1,0) [0|1] "" XXX
   SG_ CF_Ems_DecelReq : 8|12@1+ (0.001,-4.094) [-4.094|0] "m/s^2" XXX
   SG_ CR_Ems_BstPre : 20|12@1+ (1.322,0) [0|4094] "hPa" XXX
   SG_ CR_Ems_EngOilTemp : 32|8@1+ (0.75,-40) [0|254] "" XXX
   SG_ CF_Ems_PumpTPres : 40|8@1+ (3.13725,0) [0|800] "kPa" XXX
   SG_ CF_Ems_ModeledAmbTemp : 48|8@1+ (0.5,-41) [-40|60] "" XXX
   SG_ CF_Ems_OPSFail : 56|1@1+ (1,0) [0|1] "" XXX
   SG_ CF_Ems_ECTTRQLIM : 57|1@1+ (1,0) [0|1] "" XXX
   SG_ CF_Ems_AliveCounterEMS9 : 58|2@1+ (1,0) [0|3] "" XXX
   SG_ CF_Ems_ChecksumEMS9 : 60|4@1+ (1,0) [0|15] "" XXX

BO_ 899 FATC11: 8 DATC
   SG_ CR_Fatc_TqAcnOut : 0|8@1+ (0.2,0.0) [0.0|50.8] "Nm"  EMS,IBOX
   SG_ CF_Fatc_AcnRqSwi : 8|1@1+ (1.0,0.0) [0.0|1.0] ""  AAF,EMS,IBOX
   SG_ CF_Fatc_AcnCltEnRq : 9|1@1+ (1.0,0.0) [0.0|1.0] ""  EMS,IBOX
   SG_ CF_Fatc_EcvFlt : 10|1@1+ (1.0,0.0) [0.0|1.0] ""  EMS,IBOX
   SG_ CF_Fatc_BlwrOn : 11|1@1+ (1.0,0.0) [0.0|1.0] ""  EMS,IBOX
   SG_ CF_FATC_Iden : 12|2@1+ (1.0,0.0) [0.0|3.0] ""  EMS,IBOX
   SG_ CF_Fatc_BlwrMax : 14|1@1+ (1.0,0.0) [0.0|1.0] ""  CLU,EMS,IBOX
   SG_ CF_Fatc_EngStartReq : 15|1@1+ (1.0,0.0) [0.0|1.0] ""  EMS,IBOX
   SG_ CF_Fatc_IsgStopReq : 16|1@1+ (1.0,0.0) [0.0|1.0] ""  EMS,IBOX
   SG_ CF_Fatc_CtrInf : 17|3@1+ (1.0,0.0) [0.0|7.0] ""  EMS,IBOX
   SG_ CF_Fatc_MsgCnt : 20|4@1+ (1.0,0.0) [0.0|15.0] ""  EMS,IBOX
   SG_ CR_Fatc_OutTemp : 24|8@1+ (0.5,-40.0) [-40.0|60.0] "deg"  BCM,CLU,EMS,IBOX,SPAS,TCU,TPMS
   SG_ CR_Fatc_OutTempSns : 32|8@1+ (0.5,-40.0) [-40.0|60.0] "deg"  AAF,AHLS,CLU,EMS,IBOX,SPAS,TCU
   SG_ CF_Fatc_Compload : 40|3@1+ (1.0,0.0) [0.0|7.0] ""  EMS,IBOX
   SG_ CF_Fatc_ActiveEco : 43|1@1+ (1.0,0.0) [0.0|1.0] ""  CLU,IBOX
   SG_ CF_Fatc_AutoActivation : 44|1@1+ (1.0,0.0) [0.0|1.0] ""  IBOX
   SG_ CF_Fatc_DefSw : 45|1@1+ (1.0,0.0) [0.0|1.0] ""  BCM,IBOX
   SG_ CF_Fatc_PtcRlyStat : 46|1@1+ (1.0,0.0) [0.0|1.0] ""  EMS,IBOX
   SG_ CF_Fatc_ChkSum : 56|8@1+ (1.0,0.0) [0.0|255.0] ""  EMS,IBOX,SPAS

BO_ 900 EMS17: 8 EMS
   SG_ CF_Ems_PkpCurMSV : 0|8@1+ (1.0,0.0) [0.0|255.0] ""  DI_BOX
   SG_ CF_Ems_HolCurMSV : 8|8@1+ (1.0,0.0) [0.0|255.0] ""  DI_BOX
   SG_ CF_Ems_InjVBnkAct : 16|8@1+ (1.0,0.0) [0.0|255.0] ""  DI_BOX
   SG_ CF_Ems_InjVActSet : 24|8@1+ (1.0,0.0) [0.0|255.0] ""  DI_BOX
   SG_ CF_Ems_DiagFulHDEV : 32|1@1+ (1.0,0.0) [0.0|1.0] ""  DI_BOX
   SG_ CF_Ems_SwiOffIC1 : 33|1@1+ (1.0,0.0) [0.0|1.0] ""  DI_BOX
   SG_ CF_Ems_SwiOffIC2 : 34|1@1+ (1.0,0.0) [0.0|1.0] ""  DI_BOX
   SG_ CF_Ems_DiagReqHDEV : 38|1@1+ (1.0,0.0) [0.0|1.0] ""  DI_BOX
   SG_ CR_Ems_DutyCycMSV : 40|8@1+ (0.3921568627,0.0) [0.0|100.0] "%"  DI_BOX
   SG_ CR_Ems_BatVolRly : 48|8@1+ (0.1,0.0) [0.0|25.5] "V"  DI_BOX

BO_ 902 WHL_SPD11: 8 ABS
   SG_ WHL_SPD_FL : 0|14@1+ (0.03125,0.0) [0.0|511.96875] "km/h"  _4WD,AFLS,AHLS,AVM,CLU,CUBIS,ECS,EMS,EPB,IBOX,LDWS_LKAS,PGS,PSB,SCC,SMK,SPAS,TCU,TPMS,_4WD,ACU,AFLS,AHLS,AVM,CLU,ECS,EMS,EPB,IBOX,LCA,LDWS_LKAS,PGS,PSB,SCC,SMK,SPAS,TCU,TPMS
   SG_ WHL_SPD_FR : 16|14@1+ (0.03125,0.0) [0.0|511.96875] "km/h"  _4WD,ACU,AFLS,AHLS,AVM,CLU,CUBIS,ECS,EMS,EPB,IBOX,LDWS_LKAS,PGS,PSB,SCC,SMK,SPAS,TCU,TPMS,_4WD,ACU,AFLS,AHLS,AVM,CLU,ECS,EMS,EPB,IBOX,LCA,LDWS_LKAS,PGS,PSB,SCC,SMK,SPAS,TCU,TPMS
   SG_ WHL_SPD_RL : 32|14@1+ (0.03125,0.0) [0.0|511.96875] "km/h"  _4WD,AFLS,AHLS,AVM,BCM,CLU,CUBIS,ECS,EMS,EPB,IBOX,LDWS_LKAS,PGS,PSB,SCC,SMK,SPAS,TCU,TPMS,_4WD,ACU,AFLS,AHLS,AVM,BCM,CLU,ECS,EMS,EPB,IBOX,LCA,LDWS_LKAS,PGS,PSB,SCC,SMK,SPAS,TCU,TPMS
   SG_ WHL_SPD_RR : 48|14@1+ (0.03125,0.0) [0.0|511.96875] "km/h"  _4WD,AFLS,AHLS,AVM,CLU,CUBIS,ECS,EMS,EPB,IBOX,LDWS_LKAS,PGS,PSB,SCC,SMK,SPAS,TCU,TPMS,_4WD,ACU,AFLS,AHLS,AVM,CLU,ECS,EMS,EPB,IBOX,LCA,LDWS_LKAS,PGS,PSB,SCC,SMK,SPAS,TCU,TPMS
   SG_ WHL_SPD_AliveCounter_LSB : 14|2@1+ (1.0,0.0) [0.0|15.0] ""  _4WD,EMS,LPI,TCU,TMU
   SG_ WHL_SPD_AliveCounter_MSB : 30|2@1+ (1.0,0.0) [0.0|15.0] ""  _4WD,EMS,LPI,TCU,TMU
   SG_ WHL_SPD_Checksum_LSB : 46|2@1+ (1.0,0.0) [0.0|15.0] ""  _4WD,EMS,LPI,TCU,TMU
   SG_ WHL_SPD_Checksum_MSB : 62|2@1+ (1.0,0.0) [0.0|15.0] ""  _4WD,EMS,LPI,TCU,TMU

BO_ 903 WHL_PUL11: 6 ABS
   SG_ WHL_PUL_FL : 0|8@1+ (0.5,0.0) [0.0|127.5] "pulse count"  CUBIS,EPB,IBOX,SPAS,TMU,TPMS,CUBIS,EPB,IBOX,LDWS_LKAS,SPAS,TMU,TPMS
   SG_ WHL_PUL_FR : 8|8@1+ (0.5,0.0) [0.0|127.5] "pulse count"  CUBIS,EPB,IBOX,SPAS,TMU,TPMS,CUBIS,EPB,IBOX,LDWS_LKAS,SPAS,TMU,TPMS
   SG_ WHL_PUL_RL : 16|8@1+ (0.5,0.0) [0.0|127.5] "pulse count"  CUBIS,EPB,IBOX,SPAS,TMU,TPMS,CUBIS,EPB,IBOX,LDWS_LKAS,SPAS,TMU,TPMS
   SG_ WHL_PUL_RR : 24|8@1+ (0.5,0.0) [0.0|127.5] "pulse count"  CUBIS,EPB,IBOX,SPAS,TMU,TPMS,CUBIS,EPB,IBOX,LDWS_LKAS,SPAS,TMU,TPMS
   SG_ WHL_DIR_FL : 32|2@1+ (1.0,0.0) [0.0|3.0] ""  EPB,SPAS,TPMS,EPB,LCA,SPAS,TPMS
   SG_ WHL_DIR_FR : 34|2@1+ (1.0,0.0) [0.0|3.0] ""  EPB,SPAS,TPMS,EPB,LCA,SPAS,TPMS
   SG_ WHL_DIR_RL : 36|2@1+ (1.0,0.0) [0.0|3.0] ""  EPB,SPAS,TPMS,EPB,LCA,SPAS,TPMS
   SG_ WHL_DIR_RR : 38|2@1+ (1.0,0.0) [0.0|3.0] ""  EPB,SPAS,TPMS,EPB,LCA,SPAS,TPMS
   SG_ WHL_PUL_Chksum : 40|8@1+ (1.0,0.0) [0.0|255.0] ""  EPB,SPAS,TPMS,EPB,LCA,LDWS_LKAS,SPAS,TPMS

BO_ 906 ABS11: 8 ABS
   SG_ ABS_DEF : 0|1@1+ (1.0,0.0) [0.0|1.0] ""  _4WD,ACU,EMS,SPAS,TCU
   SG_ EBD_DEF : 1|1@1+ (1.0,0.0) [0.0|1.0] ""  _4WD,EMS,SPAS,TCU
   SG_ ABS_ACT : 2|1@1+ (1.0,0.0) [0.0|1.0] ""  _4WD,ACU,EPB,SPAS,TCU
   SG_ ABS_W_LAMP : 3|1@1+ (1.0,0.0) [0.0|1.0] ""  _4WD,CLU,CUBIS,MTS,TMU
   SG_ EBD_W_LAMP : 4|1@1+ (1.0,0.0) [0.0|1.0] ""  _4WD,CLU
   SG_ ABS_DIAG : 5|1@1+ (1.0,0.0) [0.0|1.0] ""  _4WD,CLU
   SG_ ESS_STAT : 6|2@1+ (1.0,0.0) [0.0|3.0] ""  _4WD,BCM,CLU,EMS

BO_ 912 SPAS11: 7 SPAS
   SG_ CF_Spas_Stat : 0|4@1+ (1.0,0.0) [0.0|15.0] ""  ESC,MDPS
   SG_ CF_Spas_TestMode : 4|2@1+ (1.0,0.0) [0.0|3.0] ""  MDPS
   SG_ CR_Spas_StrAngCmd : 8|16@1- (0.1,0.0) [-3276.8|3276.7] ""  MDPS
   SG_ CF_Spas_BeepAlarm : 24|4@1+ (1.0,0.0) [0.0|15.0] ""  CLU
   SG_ CF_Spas_Mode_Seq : 28|2@1+ (1.0,0.0) [0.0|3.0] ""  CLU
   SG_ CF_Spas_AliveCnt : 32|8@1+ (1.0,0.0) [0.0|255.0] ""  MDPS
   SG_ CF_Spas_Chksum : 40|8@1+ (1.0,0.0) [0.0|255.0] ""  MDPS
   SG_ CF_Spas_PasVol : 48|3@1+ (1.0,0.0) [0.0|7.0] ""  CGW,CLU

BO_ 915 TCS12: 4 ESC
   SG_ SA_COUNT : 0|16@1+ (2.0,-32768.0) [-32768.0|98302.0] ""  _4WD,ACU,MDPS
   SG_ SA_Z_COUNT : 16|15@1+ (2.0,-32768.0) [-32768.0|32766.0] ""  _4WD,ACU,MDPS
   SG_ SA_Z_FLAG : 31|1@1+ (1.0,0.0) [0.0|1.0] ""  _4WD,ACU,MDPS

BO_ 916 TCS13: 8 ESC
   SG_ aBasis : 0|11@1+ (0.01,-10.23) [-10.23|10.24] "m/s^2"  EMS,SCC
   SG_ BrakeLight : 11|1@1+ (1.0,0.0) [0.0|1.0] ""  CLU,EMS,SCC
   SG_ DCEnable : 12|1@1+ (1.0,0.0) [0.0|1.0] ""  EMS,SCC
   SG_ AliveCounterTCS : 13|3@1+ (1.0,0.0) [0.0|7.0] ""  EMS,SCC
   SG_ ACCReqLim : 22|2@1+ (1.0,0.0) [0.0|3.0] ""  EMS,SCC
   SG_ TQI_ACC : 24|8@1+ (0.390625,0.0) [0.0|99.609375] "%"  EMS
   SG_ ACCEL_REF_ACC : 32|11@1+ (0.01,-10.23) [-10.23|10.24] "m/s^2"  EMS,SCC
   SG_ ACCEnable : 43|2@1+ (1.0,0.0) [0.0|3.0] ""  EMS,SCC
   SG_ DriverOverride : 45|2@1+ (1.0,0.0) [0.0|3.0] ""  EMS,SCC
   SG_ StandStill : 47|1@1+ (1.0,0.0) [0.0|1.0] ""  EMS,SCC
   SG_ CheckSum_TCS3 : 48|4@1+ (1.0,0.0) [0.0|15.0] ""  EMS,SCC
   SG_ ACC_EQUIP : 52|1@1+ (1.0,0.0) [0.0|1.0] ""  EMS,SCC
   SG_ PBRAKE_ACT : 53|1@1+ (1.0,0.0) [0.0|1.0] ""  EMS,SCC
   SG_ ACC_REQ : 54|1@1+ (1.0,0.0) [0.0|1.0] ""  EMS
   SG_ DriverBraking : 55|1@1+ (1.0,0.0) [0.0|1.0] ""  EMS,SCC
   SG_ CF_VSM_Coded : 56|1@1+ (1.0,0.0) [0.0|1.0] ""  SCC
   SG_ CF_VSM_Avail : 57|2@1+ (1.0,0.0) [0.0|3.0] ""  CLU,SCC
   SG_ CF_VSM_Handshake : 59|1@1+ (1.0,0.0) [0.0|1.0] ""  SCC
   SG_ CF_DriBkeStat : 60|1@1+ (1.0,0.0) [0.0|1.0] ""  SCC
   SG_ CF_VSM_ConfSwi : 61|2@1+ (1.0,0.0) [0.0|3.0] ""  SCC
   SG_ AEB_EQUIP : 63|1@1+ (1.0,0.0) [0.0|1.0] ""  SCC

BO_ 1017 ECS12: 4 ECS
   SG_ Height_FL : 0|8@1+ (1.0,-128.0) [-128.0|127.0] "mm"  AFLS
   SG_ Height_FR : 8|8@1+ (1.0,-128.0) [-128.0|127.0] "mm"  AFLS
   SG_ Height_RL : 16|8@1+ (1.0,-128.0) [-128.0|127.0] "mm"  AFLS
   SG_ Height_RR : 24|8@1+ (1.0,-128.0) [-128.0|127.0] "mm"  AFLS

BO_ 1024 CLU_CFG11: 2 CLU
   SG_ Vehicle_Type : 0|16@1+ (1.0,0.0) [0.0|65536.0] ""  _4WD

BO_ 1040 CGW_USM1: 8 BCM
   SG_ CF_Gway_ATTurnRValue : 0|2@1+ (1.0,0.0) [0.0|3.0] ""  CLU
   SG_ CF_Gway_PTGMRValue : 2|2@1+ (1.0,0.0) [0.0|3.0] ""  CLU
   SG_ CF_Gway_EscortHLRValue : 4|2@1+ (1.0,0.0) [0.0|3.0] ""  CLU
   SG_ CF_Gway_TTUnlockRValue : 6|2@1+ (1.0,0.0) [0.0|3.0] ""  CLU
   SG_ CF_Gway_ADrLRValue : 8|3@1+ (1.0,0.0) [0.0|7.0] ""  CLU
   SG_ CF_Gway_ADrURValue : 11|3@1+ (1.0,0.0) [0.0|7.0] ""  CLU
   SG_ CF_Gway_SCMRValue : 14|2@1+ (1.0,0.0) [0.0|3.0] ""  CLU
   SG_ CF_Gway_WlightRValue : 16|2@1+ (1.0,0.0) [0.0|3.0] ""  CLU
   SG_ CF_Gway_PSMRValue : 18|3@1+ (1.0,0.0) [0.0|7.0] ""  CLU
   SG_ CF_Gway_OTTurnRValue : 21|3@1+ (1.0,0.0) [0.0|7.0] ""  CLU
   SG_ CF_Gway_DrLockSoundRValue : 24|3@1+ (1.0,0.0) [0.0|7.0] ""  CLU
   SG_ CF_Gway_HAnBRValue : 27|3@1+ (1.0,0.0) [0.0|7.0] ""  CLU
   SG_ CF_Gway_MoodLpRValue : 30|2@1+ (1.0,0.0) [0.0|3.0] ""  CLU
   SG_ CF_Gway_HfreeTrunkRValue : 32|3@1+ (1.0,0.0) [0.0|7.0] ""  CLU
   SG_ CF_Gway_AutoLightRValue : 35|3@1+ (1.0,0.0) [0.0|7.0] ""  CLU
   SG_ CF_Gway_RearWiperRValue : 38|2@1+ (1.0,0.0) [0.0|3.0] ""  CLU
   SG_ CF_Gway_PasSpkrLvRValue : 40|3@1+ (1.0,0.0) [0.0|7.0] ""  CLU

BO_ 1056 SCC11: 8 SCC
   SG_ MainMode_ACC : 0|1@1+ (1.0,0.0) [0.0|1.0] ""  CLU,EMS,ESC
   SG_ SCCInfoDisplay : 1|3@1+ (1.0,0.0) [0.0|7.0] ""  CLU,ESC
   SG_ AliveCounterACC : 4|4@1+ (1.0,0.0) [0.0|15.0] ""  CLU,EMS,ESC,TCU
   SG_ VSetDis : 8|8@1+ (1.0,0.0) [0.0|255.0] "km/h or MPH"  CLU,ESC,TCU
   SG_ ObjValid : 16|1@1+ (1.0,0.0) [0.0|1.0] ""  CLU,ESC,TCU
   SG_ DriverAlertDisplay : 17|2@1+ (1.0,0.0) [0.0|3.0] ""  CLU,ESC
   SG_ TauGapSet : 19|3@1+ (1.0,0.0) [0.0|7.0] ""  CLU,ESC,TCU
   SG_ ACC_ObjStatus : 22|2@1+ (1.0,0.0) [0.0|3.0] ""  ABS,ESC
   SG_ ACC_ObjLatPos : 24|9@1+ (0.1,-20.0) [-20.0|31.1] "m"  ABS,ESC
   SG_ ACC_ObjDist : 33|11@1+ (0.1,0.0) [0.0|204.7] "m"  ABS,ESC
   SG_ ACC_ObjRelSpd : 44|12@1+ (0.1,-170.0) [-170.0|239.5] "m/s"  ABS,ESC
   SG_ Navi_SCC_Curve_Status : 56|2@1+ (1.0,0.0) [0.0|3.0] ""  CLU
   SG_ Navi_SCC_Curve_Act : 58|2@1+ (1.0,0.0) [0.0|3.0] ""  CLU
   SG_ Navi_SCC_Camera_Act : 60|2@1+ (1.0,0.0) [0.0|3.0] ""  CLU
   SG_ Navi_SCC_Camera_Status : 62|2@1+ (1.0,0.0) [0.0|3.0] ""  CLU

BO_ 1057 SCC12: 8 SCC
   SG_ CF_VSM_Prefill : 0|1@1+ (1.0,0.0) [0.0|1.0] ""  ESC
   SG_ CF_VSM_DecCmdAct : 1|1@1+ (1.0,0.0) [0.0|1.0] ""  ESC
   SG_ CF_VSM_HBACmd : 2|2@1+ (1.0,0.0) [0.0|3.0] ""  ESC
   SG_ CF_VSM_Warn : 4|2@1+ (1.0,0.0) [0.0|3.0] ""  CLU,ESC,IAP
   SG_ CF_VSM_Stat : 6|2@1+ (1.0,0.0) [0.0|3.0] ""  CLU,ESC,PSB
   SG_ CF_VSM_BeltCmd : 8|3@1+ (1.0,0.0) [0.0|7.0] ""  ESC,PSB
   SG_ ACCFailInfo : 11|2@1+ (1.0,0.0) [0.0|3.0] ""  CLU,CUBIS,ESC,IBOX
   SG_ ACCMode : 13|2@1+ (1.0,0.0) [0.0|3.0] ""  CLU,ESC,IBOX,TCU
   SG_ StopReq : 15|1@1+ (1.0,0.0) [0.0|1.0] ""  EPB,ESC
   SG_ CR_VSM_DecCmd : 16|8@1+ (0.01,0.0) [0.0|2.55] "g"  ESC
   SG_ aReqMax : 24|11@1+ (0.01,-10.23) [-10.23|10.24] "m/s^2"  EMS,ESC,TCU
   SG_ TakeOverReq : 35|1@1+ (1.0,0.0) [0.0|1.0] ""  CLU,ESC,TCU
   SG_ PreFill : 36|1@1+ (1.0,0.0) [0.0|1.0] ""  ESC,TCU
   SG_ aReqMin : 37|11@1+ (0.01,-10.23) [-10.23|10.24] "m/s^2"  EMS,ESC,TCU
   SG_ CF_VSM_ConfMode : 48|2@1+ (1.0,0.0) [0.0|3.0] ""  CLU,ESC
   SG_ AEB_Failinfo : 50|2@1+ (1.0,0.0) [0.0|3.0] ""  CLU,ESC
   SG_ AEB_Status : 52|2@1+ (1.0,0.0) [0.0|3.0] ""  CLU,ESC
   SG_ AEB_CmdAct : 54|1@1+ (1.0,0.0) [0.0|1.0] ""  ESC
   SG_ AEB_StopReq : 55|1@1+ (1.0,0.0) [0.0|1.0] ""  CLU,ESC
   SG_ CR_VSM_Alive : 56|4@1+ (1.0,0.0) [0.0|15.0] ""  ESC,PSB
   SG_ CR_VSM_ChkSum : 60|4@1+ (1.0,0.0) [0.0|15.0] ""  ESC,PSB

BO_ 1064 _4WD11: 8 _4WD
   SG_ _4WD_TYPE : 0|2@1+ (1.0,0.0) [0.0|3.0] ""  ACU,ESC,TPMS
   SG_ _4WD_SUPPORT : 2|2@1+ (1.0,0.0) [0.0|3.0] ""  ABS,ESC,TPMS
   SG_ _4WD_ERR : 8|8@1+ (1.0,0.0) [0.0|255.0] ""  CLU,ESC
   SG_ CLU_DUTY : 16|8@1+ (1.0,0.0) [0.0|64.0] "%"  ABS,ESC
   SG_ R_TIRE : 24|8@1+ (1.0,200.0) [200.0|455.0] "mm"  ABS,ESC,TPMS
   SG_ _4WD_SW : 32|8@1+ (1.0,0.0) [0.0|9.9] ""  ESC
   SG_ _2H_ACT : 40|1@1+ (1.0,0.0) [0.0|1.0] ""  ABS,ESC
   SG_ _4H_ACT : 41|1@1+ (1.0,0.0) [0.0|1.0] ""  ABS,CLU,ESC,TPMS
   SG_ LOW_ACT : 42|1@1+ (1.0,0.0) [0.0|1.0] ""  ABS,ESC,TCU,TPMS
   SG_ AUTO_ACT : 43|1@1+ (1.0,0.0) [0.0|1.0] ""  ABS,ESC,TPMS
   SG_ LOCK_ACT : 44|1@1+ (1.0,0.0) [0.0|1.0] ""  ABS,CLU,ESC,TPMS
   SG_ _4WD_TQC_CUR : 48|16@1+ (1.0,0.0) [0.0|65535.0] "Nm"  ABS,ESC

BO_ 1065 _4WD12: 8 _4WD
   SG_ Ster_Pos : 0|16@1+ (1.0,-600.0) [-600.0|600.0] "Deg"  ESC
   SG_ FRSS : 16|8@1+ (1.0,0.0) [0.0|254.0] "km/h"  ESC
   SG_ FLSS : 24|8@1+ (1.0,0.0) [0.0|254.0] "km/h"  ESC
   SG_ RRSS : 32|8@1+ (1.0,0.0) [0.0|254.0] "km/h"  ESC
   SG_ RLSS : 40|8@1+ (1.0,0.0) [0.0|254.0] "km/h"  ESC
   SG_ CLU_PRES : 48|16@1+ (0.0625,-50.0) [-50.0|50.0] "Bar"  ESC

BO_ 1066 _4WD13: 6 _4WD
   SG_ _4WD_CURRENT : 0|8@1+ (0.390625,0.0) [-50.0|50.0] "A"  TCU
   SG_ _4WD_POSITION : 8|16@1+ (0.015625,0.0) [-180.0|180.0] "Deg"  TCU
   SG_ _4WD_CLU_THERM_STR : 24|8@1+ (1.0,0.0) [0.0|100.0] "%"  TCU
   SG_ _4WD_STATUS : 32|8@1+ (1.0,0.0) [0.0|15.0] ""  ESC,TCU

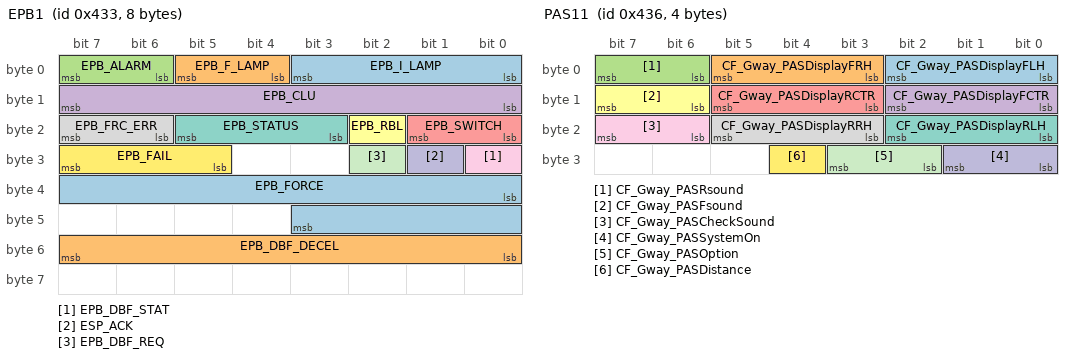
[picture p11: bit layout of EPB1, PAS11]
BO_ 1075 EPB1: 8 XXX
   SG_ EPB_I_LAMP : 0|4@1+ (1,0) [0|15] "" XXX
   SG_ EPB_F_LAMP : 4|2@1+ (1,0) [0|3] "" XXX
   SG_ EPB_ALARM : 6|2@1+ (1,0) [0|3] "" XXX
   SG_ EPB_CLU : 8|8@1+ (1,0) [0|255] "" XXX
   SG_ EPB_SWITCH : 16|2@1+ (1,0) [0|3] "" XXX
   SG_ EPB_RBL : 18|1@1+ (1,0) [0|1] "" XXX
   SG_ EPB_STATUS : 19|3@1+ (1,0) [0|7] "" XXX
   SG_ EPB_FRC_ERR : 22|2@1+ (1,0) [0|3] "" XXX
   SG_ EPB_DBF_STAT : 24|1@1+ (1,0) [0|1] "" XXX
   SG_ ESP_ACK : 25|1@1+ (1,0) [0|1] "" XXX
   SG_ EPB_DBF_REQ : 26|1@1+ (1,0) [0|1] "" XXX
   SG_ EPB_FAIL : 29|3@1+ (1,0) [0|7] "" XXX
   SG_ EPB_FORCE : 32|12@1+ (1,-1000) [-1000|3000] "" XXX
   SG_ EPB_DBF_DECEL : 48|8@1+ (0.01,0) [0|2.54] "g" XXX

BO_ 1078 PAS11: 4 BCM
   SG_ CF_Gway_PASDisplayFLH : 0|3@1+ (1.0,0.0) [0.0|7.0] ""  AVM,CLU,AVM
   SG_ CF_Gway_PASDisplayFRH : 3|3@1+ (1.0,0.0) [0.0|7.0] ""  AVM,CLU,AVM
   SG_ CF_Gway_PASRsound : 6|2@1+ (1.0,0.0) [0.0|3.0] ""  CLU,Dummy
   SG_ CF_Gway_PASDisplayFCTR : 8|3@1+ (1.0,0.0) [0.0|7.0] ""  AVM,CLU,AVM
   SG_ CF_Gway_PASDisplayRCTR : 11|3@1+ (1.0,0.0) [0.0|7.0] ""  AVM,CLU,PGS,AVM
   SG_ CF_Gway_PASFsound : 14|2@1+ (1.0,0.0) [0.0|3.0] ""  CLU,Dummy
   SG_ CF_Gway_PASDisplayRLH : 16|3@1+ (1.0,0.0) [0.0|7.0] ""  AVM,CLU,PGS,AVM
   SG_ CF_Gway_PASDisplayRRH : 19|3@1+ (1.0,0.0) [0.0|7.0] ""  AVM,CLU,PGS,AVM
   SG_ CF_Gway_PASCheckSound : 22|2@1+ (1.0,0.0) [0.0|3.0] ""  CLU,Dummy
   SG_ CF_Gway_PASSystemOn : 24|2@1+ (1.0,0.0) [0.0|3.0] ""  CLU,Dummy
   SG_ CF_Gway_PASOption : 26|2@1+ (1.0,0.0) [0.0|3.0] ""  CLU
   SG_ CF_Gway_PASDistance : 28|1@1+ (1.0,0.0) [0.0|1.0] ""  CLU

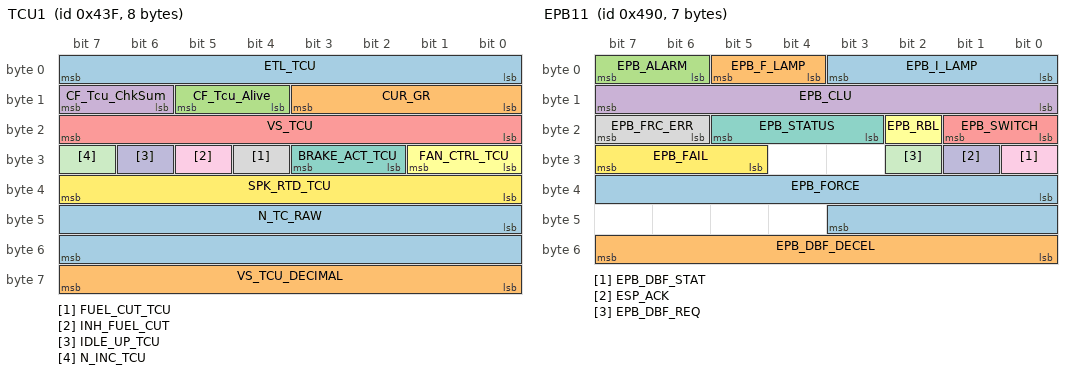
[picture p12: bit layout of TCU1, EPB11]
BO_ 1087 TCU1: 8 XXX
   SG_ ETL_TCU : 0|8@1+ (2,0) [0|508] "Nm" XXX
   SG_ CUR_GR : 8|4@1+ (1,0) [0|15] "" XXX
   SG_ CF_Tcu_Alive : 12|2@1+ (1,0) [0|3] "" XXX
   SG_ CF_Tcu_ChkSum : 14|2@1+ (1,0) [0|3] "" XXX
   SG_ VS_TCU : 16|8@1+ (1,0) [0|254] "km/h" XXX
   SG_ FAN_CTRL_TCU : 24|2@1+ (1,0) [0|3] "" XXX
   SG_ BRAKE_ACT_TCU : 26|2@1+ (1,0) [0|3] "" XXX
   SG_ FUEL_CUT_TCU : 28|1@1+ (1,0) [0|1] "" XXX
   SG_ INH_FUEL_CUT : 29|1@1+ (1,0) [0|1] "" XXX
   SG_ IDLE_UP_TCU : 30|1@1+ (1,0) [0|1] "" XXX
   SG_ N_INC_TCU : 31|1@1+ (1,0) [0|1] "" XXX
   SG_ SPK_RTD_TCU : 32|8@1+ (0.375,-23.625) [-15|15] "" XXX
   SG_ N_TC_RAW : 40|16@1+ (0.25,0) [0|16383.5] "rpm" XXX
   SG_ VS_TCU_DECIMAL : 56|8@1+ (0.0078125,0) [0|0.992188] "km/h" XXX

BO_ 1088 NM_H_U: 8 H_U
   SG_ Destination_H_U : 7|8@0+ (1,0) [0|0] ""  CLOCK,HUD,DATC,CCP,KMA_TMU,CUBIS,TMU,IPM,RSE_R,RRC,CGW,RSE_L,AMP,EDT,SWRC,IBOX,CLU,FHCU,ASD,MON,AVM,KBD
   SG_ NMSleepFlag_H_U : 13|2@0+ (1,0) [0|0] ""  CLOCK,HUD,DATC,CCP,KMA_TMU,CUBIS,TMU,IPM,RSE_R,RRC,CGW,RSE_L,AMP,EDT,SWRC,IBOX,CLU,FHCU,ASD,MON,AVM,KBD
   SG_ NMCommandCode_H_U : 10|3@0+ (1,0) [0|0] ""  CLOCK,HUD,DATC,CCP,KMA_TMU,CUBIS,TMU,IPM,RSE_R,RRC,CGW,RSE_L,AMP,EDT,SWRC,IBOX,CLU,FHCU,ASD,MON,AVM,KBD

BO_ 1089 NM_MON: 8 MON
   SG_ Destination_MON : 7|8@0+ (1,0) [0|0] ""  CLOCK,HUD,H_U,DATC,CCP,KMA_TMU,CUBIS,TMU,IPM,RSE_R,RRC,CGW,RSE_L,AMP,EDT,SWRC,IBOX,CLU,FHCU,ASD,AVM,KBD
   SG_ NMSleepFlag_MON : 13|2@0+ (1,0) [0|0] ""  CLOCK,HUD,H_U,DATC,CCP,KMA_TMU,CUBIS,TMU,IPM,RSE_R,RRC,CGW,RSE_L,AMP,EDT,SWRC,IBOX,CLU,FHCU,ASD,AVM,KBD
   SG_ NMCommandCode_MON : 10|3@0+ (1,0) [0|0] ""  CLOCK,HUD,H_U,DATC,CCP,KMA_TMU,CUBIS,TMU,IPM,RSE_R,RRC,CGW,RSE_L,AMP,EDT,SWRC,IBOX,CLU,FHCU,ASD,AVM,KBD

BO_ 1090 NM_KBD: 8 KBD
   SG_ Destination_KBD : 7|8@0+ (1,0) [0|0] ""  CLOCK,HUD,H_U,DATC,CCP,KMA_TMU,CUBIS,TMU,IPM,RSE_R,RRC,CGW,RSE_L,AMP,EDT,SWRC,IBOX,CLU,FHCU,ASD,MON,AVM
   SG_ NMSleepFlag_KBD : 13|2@0+ (1,0) [0|0] ""  CLOCK,HUD,H_U,DATC,CCP,KMA_TMU,CUBIS,TMU,IPM,RSE_R,RRC,CGW,RSE_L,AMP,EDT,SWRC,IBOX,CLU,FHCU,ASD,MON,AVM
   SG_ NMCommandCode_KBD : 10|3@0+ (1,0) [0|0] ""  CLOCK,HUD,H_U,DATC,CCP,KMA_TMU,CUBIS,TMU,IPM,RSE_R,RRC,CGW,RSE_L,AMP,EDT,SWRC,IBOX,CLU,FHCU,ASD,MON,AVM

BO_ 1091 NM_DATC: 8 DATC
   SG_ Destination_DATC : 7|8@0+ (1,0) [0|0] ""  CLOCK,HUD,H_U,CCP,KMA_TMU,CUBIS,TMU,IPM,RSE_R,RRC,CGW,RSE_L,AMP,EDT,SWRC,IBOX,CLU,FHCU,ASD,MON,AVM,KBD
   SG_ NMSleepFlag_DATC : 13|2@0+ (1,0) [0|0] ""  CLOCK,HUD,H_U,CCP,KMA_TMU,CUBIS,TMU,IPM,RSE_R,RRC,CGW,RSE_L,AMP,EDT,SWRC,IBOX,CLU,FHCU,ASD,MON,AVM,KBD
   SG_ NMCommandCode_DATC : 10|3@0+ (1,0) [0|0] ""  CLOCK,HUD,H_U,CCP,KMA_TMU,CUBIS,TMU,IPM,RSE_R,RRC,CGW,RSE_L,AMP,EDT,SWRC,IBOX,CLU,FHCU,ASD,MON,AVM,KBD

BO_ 1092 NM_CLOCK: 8 CLOCK
   SG_ Destination_CLOCK : 7|8@0+ (1,0) [0|0] ""  HUD,H_U,DATC,CCP,KMA_TMU,CUBIS,TMU,IPM,RSE_R,RRC,CGW,RSE_L,AMP,EDT,SWRC,IBOX,CLU,FHCU,ASD,MON,AVM,KBD
   SG_ NMSleepFlag_CLOCK : 13|2@0+ (1,0) [0|0] ""  HUD,H_U,DATC,CCP,KMA_TMU,CUBIS,TMU,IPM,RSE_R,RRC,CGW,RSE_L,AMP,EDT,SWRC,IBOX,CLU,FHCU,ASD,MON,AVM,KBD
   SG_ NMCommandCode_CLOCK : 10|3@0+ (1,0) [0|0] ""  HUD,H_U,DATC,CCP,KMA_TMU,CUBIS,TMU,IPM,RSE_R,RRC,CGW,RSE_L,AMP,EDT,SWRC,IBOX,CLU,FHCU,ASD,MON,AVM,KBD

BO_ 1093 NM_RRC: 8 RRC
   SG_ Destination_RRC : 7|8@0+ (1,0) [0|0] ""  CLOCK,HUD,H_U,DATC,CCP,KMA_TMU,CUBIS,TMU,IPM,RSE_R,CGW,RSE_L,AMP,EDT,SWRC,IBOX,CLU,FHCU,ASD,MON,AVM,KBD
   SG_ NMSleepFlag_RRC : 13|2@0+ (1,0) [0|0] ""  CLOCK,HUD,H_U,DATC,CCP,KMA_TMU,CUBIS,TMU,IPM,RSE_R,CGW,RSE_L,AMP,EDT,SWRC,IBOX,CLU,FHCU,ASD,MON,AVM,KBD
   SG_ NMCommandCode_RRC : 10|3@0+ (1,0) [0|0] ""  CLOCK,HUD,H_U,DATC,CCP,KMA_TMU,CUBIS,TMU,IPM,RSE_R,CGW,RSE_L,AMP,EDT,SWRC,IBOX,CLU,FHCU,ASD,MON,AVM,KBD

BO_ 1094 NM_ASD: 8 ASD
   SG_ Destination_ASD : 7|8@0+ (1,0) [0|0] ""  CLOCK,HUD,H_U,DATC,CCP,KMA_TMU,CUBIS,TMU,IPM,RSE_R,RRC,CGW,RSE_L,AMP,EDT,SWRC,IBOX,CLU,FHCU,MON,AVM,KBD
   SG_ NMSleepFlag_ASD : 13|2@0+ (1,0) [0|0] ""  CLOCK,HUD,H_U,DATC,CCP,KMA_TMU,CUBIS,TMU,IPM,RSE_R,RRC,CGW,RSE_L,AMP,EDT,SWRC,IBOX,CLU,FHCU,MON,AVM,KBD
   SG_ NMCommandCode_ASD : 10|3@0+ (1,0) [0|0] ""  CLOCK,HUD,H_U,DATC,CCP,KMA_TMU,CUBIS,TMU,IPM,RSE_R,RRC,CGW,RSE_L,AMP,EDT,SWRC,IBOX,CLU,FHCU,MON,AVM,KBD

BO_ 1095 NM_IPM: 8 IPM
   SG_ Destination_IPM : 7|8@0+ (1,0) [0|0] ""  CLOCK,HUD,H_U,DATC,CCP,KMA_TMU,CUBIS,TMU,RSE_R,RRC,CGW,RSE_L,AMP,EDT,SWRC,IBOX,CLU,FHCU,ASD,MON,AVM,KBD
   SG_ NMSleepFlag_IPM : 13|2@0+ (1,0) [0|0] ""  CLOCK,HUD,H_U,DATC,CCP,KMA_TMU,CUBIS,TMU,RSE_R,RRC,CGW,RSE_L,AMP,EDT,SWRC,IBOX,CLU,FHCU,ASD,MON,AVM,KBD
   SG_ NMCommandCode_IPM : 10|3@0+ (1,0) [0|0] ""  CLOCK,HUD,H_U,DATC,CCP,KMA_TMU,CUBIS,TMU,RSE_R,RRC,CGW,RSE_L,AMP,EDT,SWRC,IBOX,CLU,FHCU,ASD,MON,AVM,KBD

BO_ 1096 NM_AMP: 8 AMP
   SG_ Destination_AMP : 7|8@0+ (1,0) [0|0] ""  CLOCK,HUD,H_U,DATC,CCP,KMA_TMU,CUBIS,TMU,IPM,RSE_R,RRC,CGW,RSE_L,EDT,SWRC,IBOX,CLU,FHCU,ASD,MON,AVM,KBD
   SG_ NMSleepFlag_AMP : 13|2@0+ (1,0) [0|0] ""  CLOCK,HUD,H_U,DATC,CCP,KMA_TMU,CUBIS,TMU,IPM,RSE_R,RRC,CGW,RSE_L,EDT,SWRC,IBOX,CLU,FHCU,ASD,MON,AVM,KBD
   SG_ NMCommandCode_AMP : 10|3@0+ (1,0) [0|0] ""  CLOCK,HUD,H_U,DATC,CCP,KMA_TMU,CUBIS,TMU,IPM,RSE_R,RRC,CGW,RSE_L,EDT,SWRC,IBOX,CLU,FHCU,ASD,MON,AVM,KBD

BO_ 1097 NM_FHCU: 8 FHCU
   SG_ Destination_FHCU : 7|8@0+ (1,0) [0|0] ""  CLOCK,HUD,H_U,DATC,CCP,KMA_TMU,CUBIS,TMU,IPM,RSE_R,RRC,CGW,RSE_L,AMP,EDT,SWRC,IBOX,CLU,ASD,MON,AVM,KBD
   SG_ NMSleepFlag_FHCU : 13|2@0+ (1,0) [0|0] ""  CLOCK,HUD,H_U,DATC,CCP,KMA_TMU,CUBIS,TMU,IPM,RSE_R,RRC,CGW,RSE_L,AMP,EDT,SWRC,IBOX,CLU,ASD,MON,AVM,KBD
   SG_ NMCommandCode_FHCU : 10|3@0+ (1,0) [0|0] ""  CLOCK,HUD,H_U,DATC,CCP,KMA_TMU,CUBIS,TMU,IPM,RSE_R,RRC,CGW,RSE_L,AMP,EDT,SWRC,IBOX,CLU,ASD,MON,AVM,KBD

BO_ 1098 NM_CUBIS: 8 CUBIS
   SG_ Destination_CUBIS : 7|8@0+ (1,0) [0|0] ""  CLOCK,HUD,H_U,DATC,CCP,KMA_TMU,TMU,IPM,RSE_R,RRC,CGW,RSE_L,AMP,EDT,SWRC,IBOX,CLU,FHCU,ASD,MON,AVM,KBD
   SG_ NMSleepFlag_CUBIS : 13|2@0+ (1,0) [0|0] ""  CLOCK,HUD,H_U,DATC,CCP,KMA_TMU,TMU,IPM,RSE_R,RRC,CGW,RSE_L,AMP,EDT,SWRC,IBOX,CLU,FHCU,ASD,MON,AVM,KBD
   SG_ NMCommandCode_CUBIS : 10|3@0+ (1,0) [0|0] ""  CLOCK,HUD,H_U,DATC,CCP,KMA_TMU,TMU,IPM,RSE_R,RRC,CGW,RSE_L,AMP,EDT,SWRC,IBOX,CLU,FHCU,ASD,MON,AVM,KBD

BO_ 1099 NM_TMU: 8 TMU
   SG_ Destination_TMU : 7|8@0+ (1,0) [0|0] ""  CLOCK,HUD,H_U,DATC,CCP,KMA_TMU,CUBIS,IPM,RSE_R,RRC,CGW,RSE_L,AMP,EDT,SWRC,IBOX,CLU,FHCU,ASD,MON,AVM,KBD
   SG_ NMSleepFlag_TMU : 13|2@0+ (1,0) [0|0] ""  CLOCK,HUD,H_U,DATC,CCP,KMA_TMU,CUBIS,IPM,RSE_R,RRC,CGW,RSE_L,AMP,EDT,SWRC,IBOX,CLU,FHCU,ASD,MON,AVM,KBD
   SG_ NMCommandCode_TMU : 10|3@0+ (1,0) [0|0] ""  CLOCK,HUD,H_U,DATC,CCP,KMA_TMU,CUBIS,IPM,RSE_R,RRC,CGW,RSE_L,AMP,EDT,SWRC,IBOX,CLU,FHCU,ASD,MON,AVM,KBD

BO_ 1100 NM_KMA_TMU: 8 KMA_TMU
   SG_ Destination_KMA_TMU : 7|8@0+ (1,0) [0|0] ""  CLOCK,HUD,H_U,DATC,CCP,CUBIS,TMU,IPM,RSE_R,RRC,CGW,RSE_L,AMP,EDT,SWRC,IBOX,CLU,FHCU,ASD,MON,AVM,KBD
   SG_ NMSleepFlag_KMA_TMU : 13|2@0+ (1,0) [0|0] ""  CLOCK,HUD,H_U,DATC,CCP,CUBIS,TMU,IPM,RSE_R,RRC,CGW,RSE_L,AMP,EDT,SWRC,IBOX,CLU,FHCU,ASD,MON,AVM,KBD
   SG_ NMCommandCode_KMA_TMU : 10|3@0+ (1,0) [0|0] ""  CLOCK,HUD,H_U,DATC,CCP,CUBIS,TMU,IPM,RSE_R,RRC,CGW,RSE_L,AMP,EDT,SWRC,IBOX,CLU,FHCU,ASD,MON,AVM,KBD

BO_ 1101 NM_CLU: 8 CLU
   SG_ Destination_CLU : 7|8@0+ (1,0) [0|0] ""  CLOCK,HUD,H_U,DATC,CCP,KMA_TMU,CUBIS,TMU,IPM,RSE_R,RRC,CGW,RSE_L,AMP,EDT,SWRC,IBOX,FHCU,ASD,MON,AVM,KBD
   SG_ NMSleepFlag_CLU : 13|2@0+ (1,0) [0|0] ""  CLOCK,HUD,H_U,DATC,CCP,KMA_TMU,CUBIS,TMU,IPM,RSE_R,RRC,CGW,RSE_L,AMP,EDT,SWRC,IBOX,FHCU,ASD,MON,AVM,KBD
   SG_ NMCommandCode_CLU : 10|3@0+ (1,0) [0|0] ""  CLOCK,HUD,H_U,DATC,CCP,KMA_TMU,CUBIS,TMU,IPM,RSE_R,RRC,CGW,RSE_L,AMP,EDT,SWRC,IBOX,FHCU,ASD,MON,AVM,KBD

BO_ 1102 NM_IBOX: 8 IBOX
   SG_ Destination_IBOX : 7|8@0+ (1,0) [0|0] ""  CLOCK,HUD,H_U,DATC,CCP,KMA_TMU,CUBIS,TMU,IPM,RSE_R,RRC,CGW,RSE_L,AMP,EDT,SWRC,CLU,FHCU,ASD,MON,AVM,KBD
   SG_ NMSleepFlag_IBOX : 13|2@0+ (1,0) [0|0] ""  CLOCK,HUD,H_U,DATC,CCP,KMA_TMU,CUBIS,TMU,IPM,RSE_R,RRC,CGW,RSE_L,AMP,EDT,SWRC,CLU,FHCU,ASD,MON,AVM,KBD
   SG_ NMCommandCode_IBOX : 10|3@0+ (1,0) [0|0] ""  CLOCK,HUD,H_U,DATC,CCP,KMA_TMU,CUBIS,TMU,IPM,RSE_R,RRC,CGW,RSE_L,AMP,EDT,SWRC,CLU,FHCU,ASD,MON,AVM,KBD

BO_ 1103 NM_EDT: 8 EDT
   SG_ Destination_EDT : 7|8@0+ (1,0) [0|0] ""  CLOCK,HUD,H_U,DATC,CCP,KMA_TMU,CUBIS,TMU,IPM,RSE_R,RRC,CGW,RSE_L,AMP,SWRC,IBOX,CLU,FHCU,ASD,MON,AVM,KBD
   SG_ NMSleepFlag_EDT : 13|2@0+ (1,0) [0|0] ""  CLOCK,HUD,H_U,DATC,CCP,KMA_TMU,CUBIS,TMU,IPM,RSE_R,RRC,CGW,RSE_L,AMP,SWRC,IBOX,CLU,FHCU,ASD,MON,AVM,KBD
   SG_ NMCommandCode_EDT : 10|3@0+ (1,0) [0|0] ""  CLOCK,HUD,H_U,DATC,CCP,KMA_TMU,CUBIS,TMU,IPM,RSE_R,RRC,CGW,RSE_L,AMP,SWRC,IBOX,CLU,FHCU,ASD,MON,AVM,KBD

BO_ 1104 NM_AVM: 8 AVM
   SG_ Destination_AVM : 7|8@0+ (1,0) [0|0] ""  CLOCK,HUD,H_U,DATC,CCP,KMA_TMU,CUBIS,TMU,IPM,RSE_R,RRC,CGW,RSE_L,AMP,EDT,SWRC,IBOX,CLU,FHCU,ASD,MON,KBD
   SG_ NMSleepFlag_AVM : 13|2@0+ (1,0) [0|0] ""  CLOCK,HUD,H_U,DATC,CCP,KMA_TMU,CUBIS,TMU,IPM,RSE_R,RRC,CGW,RSE_L,AMP,EDT,SWRC,IBOX,CLU,FHCU,ASD,MON,KBD
   SG_ NMCommandCode_AVM : 10|3@0+ (1,0) [0|0] ""  CLOCK,HUD,H_U,DATC,CCP,KMA_TMU,CUBIS,TMU,IPM,RSE_R,RRC,CGW,RSE_L,AMP,EDT,SWRC,IBOX,CLU,FHCU,ASD,MON,KBD

BO_ 1105 NM_CCP: 8 CCP
   SG_ Destination_CCP : 7|8@0+ (1,0) [0|0] ""  CLOCK,HUD,H_U,DATC,KMA_TMU,CUBIS,TMU,IPM,RSE_R,RRC,CGW,RSE_L,AMP,EDT,SWRC,IBOX,CLU,FHCU,ASD,MON,AVM,KBD
   SG_ NMSleepFlag_CCP : 13|2@0+ (1,0) [0|0] ""  CLOCK,HUD,H_U,DATC,KMA_TMU,CUBIS,TMU,IPM,RSE_R,RRC,CGW,RSE_L,AMP,EDT,SWRC,IBOX,CLU,FHCU,ASD,MON,AVM,KBD
   SG_ NMCommandCode_CCP : 10|3@0+ (1,0) [0|0] ""  CLOCK,HUD,H_U,DATC,KMA_TMU,CUBIS,TMU,IPM,RSE_R,RRC,CGW,RSE_L,AMP,EDT,SWRC,IBOX,CLU,FHCU,ASD,MON,AVM,KBD

BO_ 1106 NM_RSE_L: 8 RSE_L
   SG_ Destination_RSE_L : 7|8@0+ (1,0) [0|0] ""  CLOCK,HUD,H_U,DATC,CCP,KMA_TMU,CUBIS,TMU,IPM,RSE_R,RRC,CGW,AMP,EDT,SWRC,IBOX,CLU,FHCU,ASD,MON,AVM,KBD
   SG_ NMSleepFlag_RSE_L : 13|2@0+ (1,0) [0|0] ""  CLOCK,HUD,H_U,DATC,CCP,KMA_TMU,CUBIS,TMU,IPM,RSE_R,RRC,CGW,AMP,EDT,SWRC,IBOX,CLU,FHCU,ASD,MON,AVM,KBD
   SG_ NMCommandCode_RSE_L : 10|3@0+ (1,0) [0|0] ""  CLOCK,HUD,H_U,DATC,CCP,KMA_TMU,CUBIS,TMU,IPM,RSE_R,RRC,CGW,AMP,EDT,SWRC,IBOX,CLU,FHCU,ASD,MON,AVM,KBD

BO_ 1107 NM_RSE_R: 8 RSE_R
   SG_ Destination_RSE_R : 7|8@0+ (1,0) [0|0] ""  CLOCK,HUD,H_U,DATC,CCP,KMA_TMU,CUBIS,TMU,IPM,RRC,CGW,RSE_L,AMP,EDT,SWRC,IBOX,CLU,FHCU,ASD,MON,AVM,KBD
   SG_ NMSleepFlag_RSE_R : 13|2@0+ (1,0) [0|0] ""  CLOCK,HUD,H_U,DATC,CCP,KMA_TMU,CUBIS,TMU,IPM,RRC,CGW,RSE_L,AMP,EDT,SWRC,IBOX,CLU,FHCU,ASD,MON,AVM,KBD
   SG_ NMCommandCode_RSE_R : 10|3@0+ (1,0) [0|0] ""  CLOCK,HUD,H_U,DATC,CCP,KMA_TMU,CUBIS,TMU,IPM,RRC,CGW,RSE_L,AMP,EDT,SWRC,IBOX,CLU,FHCU,ASD,MON,AVM,KBD

BO_ 1108 NM_HUD: 8 HUD
   SG_ Destination_HUD : 7|8@0+ (1,0) [0|0] ""  CLOCK,H_U,DATC,CCP,KMA_TMU,CUBIS,TMU,IPM,RSE_R,RRC,CGW,RSE_L,AMP,EDT,SWRC,IBOX,CLU,FHCU,ASD,MON,AVM,KBD
   SG_ NMSleepFlag_HUD : 13|2@0+ (1,0) [0|0] ""  CLOCK,H_U,DATC,CCP,KMA_TMU,CUBIS,TMU,IPM,RSE_R,RRC,CGW,RSE_L,AMP,EDT,SWRC,IBOX,CLU,FHCU,ASD,MON,AVM,KBD
   SG_ NMCommandCode_HUD : 10|3@0+ (1,0) [0|0] ""  CLOCK,H_U,DATC,CCP,KMA_TMU,CUBIS,TMU,IPM,RSE_R,RRC,CGW,RSE_L,AMP,EDT,SWRC,IBOX,CLU,FHCU,ASD,MON,AVM,KBD

BO_ 1109 NM_CGW: 8 CGW
   SG_ Destination_CGW : 7|8@0+ (1,0) [0|0] ""  CLOCK,HUD,H_U,DATC,CCP,KMA_TMU,CUBIS,TMU,IPM,RSE_R,RRC,RSE_L,AMP,EDT,SWRC,IBOX,CLU,FHCU,ASD,MON,AVM,KBD
   SG_ NMSleepFlag_CGW : 13|2@0+ (1,0) [0|0] ""  CLOCK,HUD,H_U,DATC,CCP,KMA_TMU,CUBIS,TMU,IPM,RSE_R,RRC,RSE_L,AMP,EDT,SWRC,IBOX,CLU,FHCU,ASD,MON,AVM,KBD
   SG_ NMCommandCode_CGW : 10|3@0+ (1,0) [0|0] ""  CLOCK,HUD,H_U,DATC,CCP,KMA_TMU,CUBIS,TMU,IPM,RSE_R,RRC,RSE_L,AMP,EDT,SWRC,IBOX,CLU,FHCU,ASD,MON,AVM,KBD

BO_ 1110 NM_SWRC: 8 SWRC
   SG_ Destination_SWRC : 7|8@0+ (1,0) [0|0] ""  CLOCK,HUD,H_U,DATC,CCP,KMA_TMU,CUBIS,TMU,IPM,RSE_R,RRC,CGW,RSE_L,AMP,EDT,IBOX,CLU,FHCU,ASD,MON,AVM,KBD
   SG_ NMSleepFlag_SWRC : 13|2@0+ (1,0) [0|0] ""  CLOCK,HUD,H_U,DATC,CCP,KMA_TMU,CUBIS,TMU,IPM,RSE_R,RRC,CGW,RSE_L,AMP,EDT,IBOX,CLU,FHCU,ASD,MON,AVM,KBD
   SG_ NMCommandCode_SWRC : 10|3@0+ (1,0) [0|0] ""  CLOCK,HUD,H_U,DATC,CCP,KMA_TMU,CUBIS,TMU,IPM,RSE_R,RRC,CGW,RSE_L,AMP,EDT,IBOX,CLU,FHCU,ASD,MON,AVM,KBD

BO_ 1151 ESP11: 6 ESC
   SG_ AVH_STAT : 0|2@1+ (1.0,0.0) [0.0|3.0] ""  EMS,EPB,TCU
   SG_ LDM_STAT : 2|1@1+ (1.0,0.0) [0.0|1.0] ""  EPB,TCU
   SG_ REQ_EPB_ACT : 3|2@1+ (1.0,0.0) [0.0|3.0] ""  EPB,TCU
   SG_ REQ_EPB_STAT : 5|1@1+ (1.0,0.0) [0.0|1.0] ""  EPB
   SG_ ECD_ACT : 6|1@1+ (1.0,0.0) [0.0|1.0] ""  EPB
   SG_ _4WD_LIM_REQ : 7|1@1+ (1.0,0.0) [0.0|1.0] ""  _4WD,EMS
   SG_ ROL_CNT_ESP : 8|8@1+ (1.0,0.0) [0.0|255.0] ""  EPB,TCU
   SG_ _4WD_TQC_LIM : 16|16@1+ (1.0,0.0) [0.0|65535.0] "Nm"  _4WD,EMS
   SG_ _4WD_CLU_LIM : 32|8@1+ (0.390625,0.0) [0.0|99.609375] "%"  _4WD,EMS
   SG_ _4WD_OPEN : 40|2@1+ (1.0,0.0) [0.0|3.0] ""  _4WD,EMS
   SG_ _4WD_LIM_MODE : 42|1@1+ (1.0,0.0) [0.0|1.0] ""  _4WD

BO_ 1156 TP_CLU_HF_HU: 8 CLU
   SG_ Byte0_TCP_484 : 7|8@0+ (1,0) [0|0] ""  H_U
   SG_ Byte1_Data_484 : 15|8@0+ (1,0) [0|0] ""  H_U
   SG_ Byte2_Data_484 : 23|8@0+ (1,0) [0|0] ""  H_U
   SG_ Byte3_Data_484 : 31|8@0+ (1,0) [0|0] ""  H_U
   SG_ Byte4_Data_484 : 39|8@0+ (1,0) [0|0] ""  H_U
   SG_ Byte5_Data_484 : 47|8@0+ (1,0) [0|0] ""  H_U
   SG_ Byte6_Data_484 : 55|8@0+ (1,0) [0|0] ""  H_U
   SG_ Byte7_Data_484 : 63|8@0+ (1,0) [0|0] ""  H_U

BO_ 1157 TP_HU_CLU_HF: 8 H_U
   SG_ Byte0_TCP_485 : 7|8@0+ (1,0) [0|0] ""  CLU
   SG_ Byte1_Data_485 : 15|8@0+ (1,0) [0|0] ""  CLU
   SG_ Byte2_Data_485 : 23|8@0+ (1,0) [0|0] ""  CLU
   SG_ Byte3_Data_485 : 31|8@0+ (1,0) [0|0] ""  CLU
   SG_ Byte4_Data_485 : 39|8@0+ (1,0) [0|0] ""  CLU
   SG_ Byte5_Data_485 : 47|8@0+ (1,0) [0|0] ""  CLU
   SG_ Byte6_Data_485 : 55|8@0+ (1,0) [0|0] ""  CLU
   SG_ Byte7_Data_485 : 63|8@0+ (1,0) [0|0] ""  CLU

BO_ 1164 TP_CLU_NAVI_HU: 8 CLU
   SG_ Byte0_TCP_48C : 7|8@0+ (1,0) [0|0] ""  H_U
   SG_ Byte1_Data_48C : 15|8@0+ (1,0) [0|0] ""  H_U
   SG_ Byte2_Data_48C : 23|8@0+ (1,0) [0|0] ""  H_U
   SG_ Byte3_Data_48C : 31|8@0+ (1,0) [0|0] ""  H_U
   SG_ Byte4_Data_48C : 39|8@0+ (1,0) [0|0] ""  H_U
   SG_ Byte5_Data_48C : 47|8@0+ (1,0) [0|0] ""  H_U
   SG_ Byte6_Data_48C : 55|8@0+ (1,0) [0|0] ""  H_U
   SG_ Byte7_Data_48C : 63|8@0+ (1,0) [0|0] ""  H_U

BO_ 1165 TP_HU_CD_CLU: 8 H_U
   SG_ Byte0_TCP_48D : 7|8@0+ (1,0) [0|0] ""  CLU
   SG_ Byte1_Data_48D : 15|8@0+ (1,0) [0|0] ""  CLU
   SG_ Byte2_Data_48D : 23|8@0+ (1,0) [0|0] ""  CLU
   SG_ Byte3_Data_48D : 31|8@0+ (1,0) [0|0] ""  CLU
   SG_ Byte4_Data_48D : 39|8@0+ (1,0) [0|0] ""  CLU
   SG_ Byte5_Data_48D : 47|8@0+ (1,0) [0|0] ""  CLU
   SG_ Byte6_Data_48D : 55|8@0+ (1,0) [0|0] ""  CLU
   SG_ Byte7_Data_48D : 63|8@0+ (1,0) [0|0] ""  CLU

BO_ 1166 TP_HU_DVD_CLU: 8 H_U
   SG_ Byte0_TCP_48E : 7|8@0+ (1,0) [0|0] ""  CLU
   SG_ Byte1_Data_48E : 15|8@0+ (1,0) [0|0] ""  CLU
   SG_ Byte2_Data_48E : 23|8@0+ (1,0) [0|0] ""  CLU
   SG_ Byte3_Data_48E : 31|8@0+ (1,0) [0|0] ""  CLU
   SG_ Byte4_Data_48E : 39|8@0+ (1,0) [0|0] ""  CLU
   SG_ Byte5_Data_48E : 47|8@0+ (1,0) [0|0] ""  CLU
   SG_ Byte6_Data_48E : 55|8@0+ (1,0) [0|0] ""  CLU
   SG_ Byte7_Data_48E : 63|8@0+ (1,0) [0|0] ""  CLU

BO_ 1167 TP_HU_Ipod_CLU: 8 H_U
   SG_ Byte0_TCP_48F : 7|8@0+ (1,0) [0|0] ""  CLU
   SG_ Byte1_Data_48F : 15|8@0+ (1,0) [0|0] ""  CLU
   SG_ Byte2_Data_48F : 23|8@0+ (1,0) [0|0] ""  CLU
   SG_ Byte3_Data_48F : 31|8@0+ (1,0) [0|0] ""  CLU
   SG_ Byte4_Data_48F : 39|8@0+ (1,0) [0|0] ""  CLU
   SG_ Byte5_Data_48F : 47|8@0+ (1,0) [0|0] ""  CLU
   SG_ Byte6_Data_48F : 55|8@0+ (1,0) [0|0] ""  CLU
   SG_ Byte7_Data_48F : 63|8@0+ (1,0) [0|0] ""  CLU

BO_ 1168 EPB11: 7 EPB
   SG_ EPB_I_LAMP : 0|4@1+ (1.0,0.0) [0.0|15.0] ""  BCM,CLU,CUBIS,ESC,IBOX
   SG_ EPB_F_LAMP : 4|2@1+ (1.0,0.0) [0.0|3.0] ""  CLU,CUBIS,ESC,IBOX
   SG_ EPB_ALARM : 6|2@1+ (1.0,0.0) [0.0|3.0] ""  CLU,ESC
   SG_ EPB_CLU : 8|8@1+ (1.0,0.0) [0.0|255.0] ""  CLU,ESC
   SG_ EPB_SWITCH : 16|2@1+ (1.0,0.0) [0.0|3.0] ""  ESC,SCC
   SG_ EPB_RBL : 18|1@1+ (1.0,0.0) [0.0|1.0] ""  EMS,ESC
   SG_ EPB_STATUS : 19|3@1+ (1.0,0.0) [0.0|7.0] ""  CLU,EMS,ESC,SCC,TCU
   SG_ EPB_FRC_ERR : 22|2@1+ (1.0,0.0) [0.0|3.0] ""  EMS,ESC,SCC,TCU
   SG_ EPB_DBF_STAT : 24|1@1+ (1.0,0.0) [0.0|1.0] ""  ESC
   SG_ ESP_ACK : 25|1@1+ (1.0,0.0) [0.0|1.0] ""  ESC
   SG_ EPB_DBF_REQ : 26|1@1+ (1.0,0.0) [0.0|1.0] ""  ESC
   SG_ EPB_FAIL : 29|3@1+ (1.0,0.0) [0.0|7.0] ""  ESC,SCC
   SG_ EPB_FORCE : 32|12@1+ (1.0,-1000.0) [-1000.0|3000.0] ""  ESC
   SG_ EPB_DBF_DECEL : 48|8@1+ (0.01,0.0) [0.0|2.54] "g"  ESC

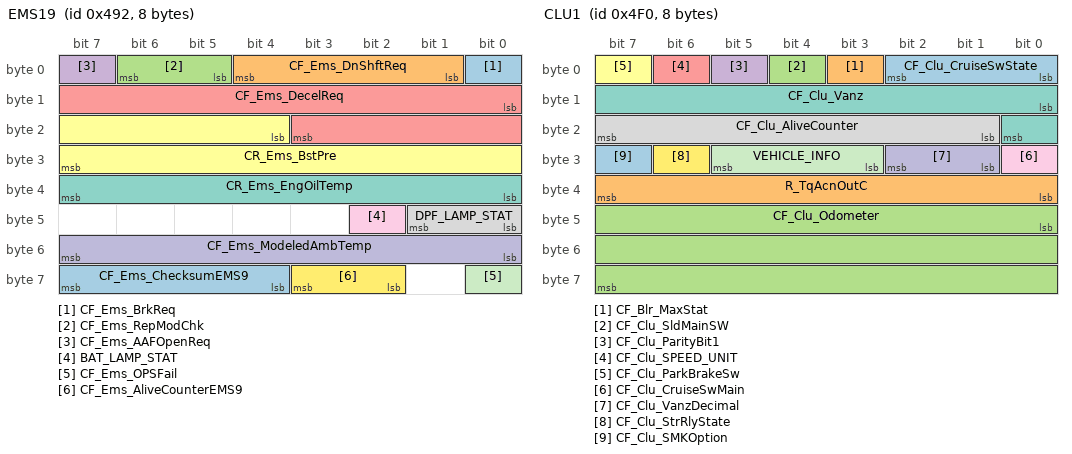
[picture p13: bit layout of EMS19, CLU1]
BO_ 1170 EMS19: 8 EMS
   SG_ CF_Ems_BrkReq : 0|1@1+ (1.0,0.0) [0.0|1.0] ""  ESC,IBOX,TCU
   SG_ CF_Ems_DnShftReq : 1|4@1+ (1.0,0.0) [0.0|14.0] ""  IBOX,TCU
   SG_ CF_Ems_RepModChk : 5|2@1+ (1.0,0.0) [0.0|3.0] ""  IBOX
   SG_ CF_Ems_AAFOpenReq : 7|1@1+ (1.0,0.0) [0.0|1.0] ""  AAF,IBOX
   SG_ CF_Ems_DecelReq : 8|12@1+ (0.0010,-4.094) [-4.094|0.0] "m/s^2"  ESC,IBOX,TCU
   SG_ CR_Ems_BstPre : 20|12@1+ (1.322,0.0) [0.0|4094.0] "hPa"  CLU,IBOX
   SG_ CR_Ems_EngOilTemp : 32|8@1+ (0.75,-40.0) [0.0|254.0] "deg"  CLU,IBOX
   SG_ DPF_LAMP_STAT : 40|2@1+ (1.0,0.0) [0.0|3.0] ""  CLU,IBOX
   SG_ BAT_LAMP_STAT : 42|1@1+ (1.0,0.0) [0.0|1.0] ""  CLU,IBOX
   SG_ CF_Ems_ModeledAmbTemp : 48|8@1+ (0.5,-41.0) [-41.0|85.5] "deg"  AAF,IBOX
   SG_ CF_Ems_OPSFail : 56|1@1+ (1.0,0.0) [0.0|1.0] ""  CLU,IBOX
   SG_ CF_Ems_AliveCounterEMS9 : 58|2@1+ (1.0,0.0) [0.0|3.0] ""  AAF,ABS,CUBIS,ECS,EPB,IBOX,MDPS,REA,SCC,SMK,TCU
   SG_ CF_Ems_ChecksumEMS9 : 60|4@1+ (1.0,0.0) [0.0|15.0] ""  AAF,ABS,CUBIS,ECS,EPB,IBOX,MDPS,REA,SCC,SMK,TCU

BO_ 1173 TP_CLU_CD_HU: 8 CLU
   SG_ Byte0_TCP_495 : 7|8@0+ (1,0) [0|0] ""  H_U
   SG_ Byte1_Data_495 : 15|8@0+ (1,0) [0|0] ""  H_U
   SG_ Byte2_Data_495 : 23|8@0+ (1,0) [0|0] ""  H_U
   SG_ Byte3_Data_495 : 31|8@0+ (1,0) [0|0] ""  H_U
   SG_ Byte4_Data_495 : 39|8@0+ (1,0) [0|0] ""  H_U
   SG_ Byte5_Data_495 : 47|8@0+ (1,0) [0|0] ""  H_U
   SG_ Byte6_Data_495 : 55|8@0+ (1,0) [0|0] ""  H_U
   SG_ Byte7_Data_495 : 63|8@0+ (1,0) [0|0] ""  H_U

BO_ 1175 TP_CLU_USB_HU: 8 CLU
   SG_ Byte0_TCP_497 : 7|8@0+ (1,0) [0|0] ""  H_U
   SG_ Byte1_Data_497 : 15|8@0+ (1,0) [0|0] ""  H_U
   SG_ Byte2_Data_497 : 23|8@0+ (1,0) [0|0] ""  H_U
   SG_ Byte3_Data_497 : 31|8@0+ (1,0) [0|0] ""  H_U
   SG_ Byte4_Data_497 : 39|8@0+ (1,0) [0|0] ""  H_U
   SG_ Byte5_Data_497 : 47|8@0+ (1,0) [0|0] ""  H_U
   SG_ Byte6_Data_497 : 55|8@0+ (1,0) [0|0] ""  H_U
   SG_ Byte7_Data_497 : 63|8@0+ (1,0) [0|0] ""  H_U

BO_ 1176 TP_CLU_DVD_HU: 8 CLU
   SG_ Byte0_TCP_498 : 7|8@0+ (1,0) [0|0] ""  H_U
   SG_ Byte1_Data_498 : 15|8@0+ (1,0) [0|0] ""  H_U
   SG_ Byte2_Data_498 : 23|8@0+ (1,0) [0|0] ""  H_U
   SG_ Byte3_Data_498 : 31|8@0+ (1,0) [0|0] ""  H_U
   SG_ Byte4_Data_498 : 39|8@0+ (1,0) [0|0] ""  H_U
   SG_ Byte5_Data_498 : 47|8@0+ (1,0) [0|0] ""  H_U
   SG_ Byte6_Data_498 : 55|8@0+ (1,0) [0|0] ""  H_U
   SG_ Byte7_Data_498 : 63|8@0+ (1,0) [0|0] ""  H_U

BO_ 1178 TP_CLU_Ipod_HU: 8 CLU
   SG_ Byte0_TCP_49A : 7|8@0+ (1,0) [0|0] ""  H_U
   SG_ Byte1_Data_49A : 15|8@0+ (1,0) [0|0] ""  H_U
   SG_ Byte2_Data_49A : 23|8@0+ (1,0) [0|0] ""  H_U
   SG_ Byte3_Data_49A : 31|8@0+ (1,0) [0|0] ""  H_U
   SG_ Byte4_Data_49A : 39|8@0+ (1,0) [0|0] ""  H_U
   SG_ Byte5_Data_49A : 47|8@0+ (1,0) [0|0] ""  H_U
   SG_ Byte6_Data_49A : 55|8@0+ (1,0) [0|0] ""  H_U
   SG_ Byte7_Data_49A : 63|8@0+ (1,0) [0|0] ""  H_U

BO_ 1179 TP_HU_NAVI_CLU: 8 H_U
   SG_ Byte0_TCP_49B : 7|8@0+ (1,0) [0|0] ""  CLU
   SG_ Byte1_Data_49B : 15|8@0+ (1,0) [0|0] ""  CLU
   SG_ Byte2_Data_49B : 23|8@0+ (1,0) [0|0] ""  CLU
   SG_ Byte3_Data_49B : 31|8@0+ (1,0) [0|0] ""  CLU
   SG_ Byte4_Data_49B : 39|8@0+ (1,0) [0|0] ""  CLU
   SG_ Byte5_Data_49B : 47|8@0+ (1,0) [0|0] ""  CLU
   SG_ Byte6_Data_49B : 55|8@0+ (1,0) [0|0] ""  CLU
   SG_ Byte7_Data_49B : 63|8@0+ (1,0) [0|0] ""  CLU

BO_ 1188 TP_CLU_DMB_HU: 8 CLU
   SG_ Byte0_TCP_4A4 : 7|8@0+ (1,0) [0|0] ""  H_U
   SG_ Byte1_Data_4A4 : 15|8@0+ (1,0) [0|0] ""  H_U
   SG_ Byte2_Data_4A4 : 23|8@0+ (1,0) [0|0] ""  H_U
   SG_ Byte3_Data_4A4 : 31|8@0+ (1,0) [0|0] ""  H_U
   SG_ Byte4_Data_4A4 : 39|8@0+ (1,0) [0|0] ""  H_U
   SG_ Byte5_Data_4A4 : 47|8@0+ (1,0) [0|0] ""  H_U
   SG_ Byte6_Data_4A4 : 55|8@0+ (1,0) [0|0] ""  H_U
   SG_ Byte7_Data_4A4 : 63|8@0+ (1,0) [0|0] ""  H_U

BO_ 1190 TP_CLU_XM_HU: 8 CLU
   SG_ Byte0_TCP_4A6 : 7|8@0+ (1,0) [0|0] ""  H_U
   SG_ Byte1_Data_4A6 : 15|8@0+ (1,0) [0|0] ""  H_U
   SG_ Byte2_Data_4A6 : 23|8@0+ (1,0) [0|0] ""  H_U
   SG_ Byte3_Data_4A6 : 31|8@0+ (1,0) [0|0] ""  H_U
   SG_ Byte4_Data_4A6 : 39|8@0+ (1,0) [0|0] ""  H_U
   SG_ Byte5_Data_4A6 : 47|8@0+ (1,0) [0|0] ""  H_U
   SG_ Byte6_Data_4A6 : 55|8@0+ (1,0) [0|0] ""  H_U
   SG_ Byte7_Data_4A6 : 63|8@0+ (1,0) [0|0] ""  H_U

BO_ 1191 TP_CLU_DAB_HU: 8 CLU
   SG_ Byte0_TCP_4A7 : 7|8@0+ (1,0) [0|0] ""  H_U
   SG_ Byte1_Data_4A7 : 15|8@0+ (1,0) [0|0] ""  H_U
   SG_ Byte2_Data_4A7 : 23|8@0+ (1,0) [0|0] ""  H_U
   SG_ Byte3_Data_4A7 : 31|8@0+ (1,0) [0|0] ""  H_U
   SG_ Byte4_Data_4A7 : 39|8@0+ (1,0) [0|0] ""  H_U
   SG_ Byte5_Data_4A7 : 47|8@0+ (1,0) [0|0] ""  H_U
   SG_ Byte6_Data_4A7 : 55|8@0+ (1,0) [0|0] ""  H_U
   SG_ Byte7_Data_4A7 : 63|8@0+ (1,0) [0|0] ""  H_U

BO_ 1195 TP_CLU_TBT_HU: 8 CLU
   SG_ Byte0_TCP_4AB : 7|8@0+ (1,0) [0|0] ""  H_U
   SG_ Byte1_Data_4AB : 15|8@0+ (1,0) [0|0] ""  H_U
   SG_ Byte2_Data_4AB : 23|8@0+ (1,0) [0|0] ""  H_U
   SG_ Byte3_Data_4AB : 31|8@0+ (1,0) [0|0] ""  H_U
   SG_ Byte4_Data_4AB : 39|8@0+ (1,0) [0|0] ""  H_U
   SG_ Byte5_Data_4AB : 47|8@0+ (1,0) [0|0] ""  H_U
   SG_ Byte6_Data_4AB : 55|8@0+ (1,0) [0|0] ""  H_U
   SG_ Byte7_Data_4AB : 63|8@0+ (1,0) [0|0] ""  H_U

BO_ 1200 WHL_SPD: 8 XXX
   SG_ WHL_SPD_FL : 0|14@1+ (0.03125,0) [0|511.969] "km/h" XXX
   SG_ WHL_SPD_FR : 16|14@1+ (0.03125,0) [0|511.969] "km/h" XXX
   SG_ WHL_SPD_RL : 32|14@1+ (0.03125,0) [0|511.969] "km/h" XXX
   SG_ WHL_SPD_RR : 48|14@1+ (0.03125,0) [0|511.969] "km/h" XXX

BO_ 1201 WHL_PUL: 8 XXX
   SG_ WHL_PUL_FL : 0|8@1+ (0.5,0) [0|127.5] "pulse count" XXX
   SG_ WHL_PUL_FR : 8|8@1+ (0.5,0) [0|127.5] "pulse count" XXX
   SG_ WHL_PUL_RL : 16|8@1+ (0.5,0) [0|127.5] "pulse count" XXX
   SG_ WHL_PUL_RR : 24|8@1+ (0.5,0) [0|127.5] "pulse count" XXX
   SG_ WHL_DIR_FL : 32|2@1+ (1,0) [0|3] "" XXX
   SG_ WHL_DIR_FR : 34|2@1+ (1,0) [0|3] "" XXX
   SG_ WHL_DIR_RL : 36|2@1+ (1,0) [0|3] "" XXX
   SG_ WHL_DIR_RR : 38|2@1+ (1,0) [0|3] "" XXX
   SG_ WHL_PUL_Chksum : 56|8@1+ (1,0) [0|255] "" XXX

BO_ 1204 TP_HU_DMB_CLU: 8 H_U
   SG_ Byte0_TCP_4B4 : 7|8@0+ (1,0) [0|0] ""  CLU
   SG_ Byte1_Data_4B4 : 15|8@0+ (1,0) [0|0] ""  CLU
   SG_ Byte2_Data_4B4 : 23|8@0+ (1,0) [0|0] ""  CLU
   SG_ Byte3_Data_4B4 : 31|8@0+ (1,0) [0|0] ""  CLU
   SG_ Byte4_Data_4B4 : 39|8@0+ (1,0) [0|0] ""  CLU
   SG_ Byte5_Data_4B4 : 47|8@0+ (1,0) [0|0] ""  CLU
   SG_ Byte6_Data_4B4 : 55|8@0+ (1,0) [0|0] ""  CLU
   SG_ Byte7_Data_4B4 : 63|8@0+ (1,0) [0|0] ""  CLU

BO_ 1206 TP_HU_XM_CLU: 8 H_U
   SG_ Byte0_TCP_4B6 : 7|8@0+ (1,0) [0|0] ""  CLU
   SG_ Byte1_Data_4B6 : 15|8@0+ (1,0) [0|0] ""  CLU
   SG_ Byte2_Data_4B6 : 23|8@0+ (1,0) [0|0] ""  CLU
   SG_ Byte3_Data_4B6 : 31|8@0+ (1,0) [0|0] ""  CLU
   SG_ Byte4_Data_4B6 : 39|8@0+ (1,0) [0|0] ""  CLU
   SG_ Byte5_Data_4B6 : 47|8@0+ (1,0) [0|0] ""  CLU
   SG_ Byte6_Data_4B6 : 55|8@0+ (1,0) [0|0] ""  CLU
   SG_ Byte7_Data_4B6 : 63|8@0+ (1,0) [0|0] ""  CLU

BO_ 1207 TP_HU_DAB_CLU: 8 H_U
   SG_ Byte0_TCP_4B7 : 7|8@0+ (1,0) [0|0] ""  CLU
   SG_ Byte1_Data_4B7 : 15|8@0+ (1,0) [0|0] ""  CLU
   SG_ Byte2_Data_4B7 : 23|8@0+ (1,0) [0|0] ""  CLU
   SG_ Byte3_Data_4B7 : 31|8@0+ (1,0) [0|0] ""  CLU
   SG_ Byte4_Data_4B7 : 39|8@0+ (1,0) [0|0] ""  CLU
   SG_ Byte5_Data_4B7 : 47|8@0+ (1,0) [0|0] ""  CLU
   SG_ Byte6_Data_4B7 : 55|8@0+ (1,0) [0|0] ""  CLU
   SG_ Byte7_Data_4B7 : 63|8@0+ (1,0) [0|0] ""  CLU

BO_ 1211 TP_HU_TBT_CLU: 8 H_U
   SG_ Byte0_TCP_4BB : 7|8@0+ (1,0) [0|0] ""  CLU
   SG_ Byte1_Data_4BB : 15|8@0+ (1,0) [0|0] ""  CLU
   SG_ Byte2_Data_4BB : 23|8@0+ (1,0) [0|0] ""  CLU
   SG_ Byte3_Data_4BB : 31|8@0+ (1,0) [0|0] ""  CLU
   SG_ Byte4_Data_4BB : 39|8@0+ (1,0) [0|0] ""  CLU
   SG_ Byte5_Data_4BB : 47|8@0+ (1,0) [0|0] ""  CLU
   SG_ Byte6_Data_4BB : 55|8@0+ (1,0) [0|0] ""  CLU
   SG_ Byte7_Data_4BB : 63|8@0+ (1,0) [0|0] ""  CLU

BO_ 1232 TP_HU_TMU: 8 H_U
   SG_ Byte0_TCP_4D0 : 7|8@0+ (1,0) [0|0] ""  TMU
   SG_ Byte1_Data_4D0 : 15|8@0+ (1,0) [0|0] ""  TMU
   SG_ Byte2_Data_4D0 : 23|8@0+ (1,0) [0|0] ""  TMU
   SG_ Byte3_Data_4D0 : 31|8@0+ (1,0) [0|0] ""  TMU
   SG_ Byte4_Data_4D0 : 39|8@0+ (1,0) [0|0] ""  TMU
   SG_ Byte5_Data_4D0 : 47|8@0+ (1,0) [0|0] ""  TMU
   SG_ Byte6_Data_4D0 : 55|8@0+ (1,0) [0|0] ""  TMU
   SG_ Byte7_Data_4D0 : 63|8@0+ (1,0) [0|0] ""  TMU

BO_ 1248 TP_TMU_HU: 8 TMU
   SG_ Byte0_TCP_4E0 : 7|8@0+ (1,0) [0|0] ""  H_U
   SG_ Byte1_Data_4E0 : 15|8@0+ (1,0) [0|0] ""  H_U
   SG_ Byte2_Data_4E0 : 23|8@0+ (1,0) [0|0] ""  H_U
   SG_ Byte3_Data_4E0 : 31|8@0+ (1,0) [0|0] ""  H_U
   SG_ Byte4_Data_4E0 : 39|8@0+ (1,0) [0|0] ""  H_U
   SG_ Byte5_Data_4E0 : 47|8@0+ (1,0) [0|0] ""  H_U
   SG_ Byte6_Data_4E0 : 55|8@0+ (1,0) [0|0] ""  H_U
   SG_ Byte7_Data_4E0 : 63|8@0+ (1,0) [0|0] ""  H_U

BO_ 1250 TP_HU_JB_CLU: 8 H_U
   SG_ Byte0_TCP_4E2 : 7|8@0+ (1,0) [0|0] ""  CLU
   SG_ Byte1_Data_4E2 : 15|8@0+ (1,0) [0|0] ""  CLU
   SG_ Byte2_Data_4E2 : 23|8@0+ (1,0) [0|0] ""  CLU
   SG_ Byte3_Data_4E2 : 31|8@0+ (1,0) [0|0] ""  CLU
   SG_ Byte4_Data_4E2 : 39|8@0+ (1,0) [0|0] ""  CLU
   SG_ Byte5_Data_4E2 : 47|8@0+ (1,0) [0|0] ""  CLU
   SG_ Byte6_Data_4E2 : 55|8@0+ (1,0) [0|0] ""  CLU
   SG_ Byte7_Data_4E2 : 63|8@0+ (1,0) [0|0] ""  CLU

BO_ 1251 TP_CLU_JB_HU: 8 CLU
   SG_ Byte0_TCP_4E3 : 7|8@0+ (1,0) [0|0] ""  H_U
   SG_ Byte1_Data_4E3 : 15|8@0+ (1,0) [0|0] ""  H_U
   SG_ Byte2_Data_4E3 : 23|8@0+ (1,0) [0|0] ""  H_U
   SG_ Byte3_Data_4E3 : 31|8@0+ (1,0) [0|0] ""  H_U
   SG_ Byte4_Data_4E3 : 39|8@0+ (1,0) [0|0] ""  H_U
   SG_ Byte5_Data_4E3 : 47|8@0+ (1,0) [0|0] ""  H_U
   SG_ Byte6_Data_4E3 : 55|8@0+ (1,0) [0|0] ""  H_U
   SG_ Byte7_Data_4E3 : 63|8@0+ (1,0) [0|0] ""  H_U

BO_ 1252 TP_HU_VCDC_CLU: 8 H_U
   SG_ Byte0_TCP_4E4 : 7|8@0+ (1,0) [0|0] ""  CLU
   SG_ Byte1_Data_4E4 : 15|8@0+ (1,0) [0|0] ""  CLU
   SG_ Byte2_Data_4E4 : 23|8@0+ (1,0) [0|0] ""  CLU
   SG_ Byte3_Data_4E4 : 31|8@0+ (1,0) [0|0] ""  CLU
   SG_ Byte4_Data_4E4 : 39|8@0+ (1,0) [0|0] ""  CLU
   SG_ Byte5_Data_4E4 : 47|8@0+ (1,0) [0|0] ""  CLU
   SG_ Byte6_Data_4E4 : 55|8@0+ (1,0) [0|0] ""  CLU
   SG_ Byte7_Data_4E4 : 63|8@0+ (1,0) [0|0] ""  CLU

BO_ 1253 TP_CLU_VCDC_HU: 8 CLU
   SG_ Byte0_TCP_4E5 : 7|8@0+ (1,0) [0|0] ""  H_U
   SG_ Byte1_Data_4E5 : 15|8@0+ (1,0) [0|0] ""  H_U
   SG_ Byte2_Data_4E5 : 23|8@0+ (1,0) [0|0] ""  H_U
   SG_ Byte3_Data_4E5 : 31|8@0+ (1,0) [0|0] ""  H_U
   SG_ Byte4_Data_4E5 : 39|8@0+ (1,0) [0|0] ""  H_U
   SG_ Byte5_Data_4E5 : 47|8@0+ (1,0) [0|0] ""  H_U
   SG_ Byte6_Data_4E5 : 55|8@0+ (1,0) [0|0] ""  H_U
   SG_ Byte7_Data_4E5 : 63|8@0+ (1,0) [0|0] ""  H_U

BO_ 1254 TP_HU_MLT_CLU: 8 H_U
   SG_ Byte0_TCP_4E6 : 7|8@0+ (1,0) [0|0] ""  CLU
   SG_ Byte1_Data_4E6 : 15|8@0+ (1,0) [0|0] ""  CLU
   SG_ Byte2_Data_4E6 : 23|8@0+ (1,0) [0|0] ""  CLU
   SG_ Byte3_Data_4E6 : 31|8@0+ (1,0) [0|0] ""  CLU
   SG_ Byte4_Data_4E6 : 39|8@0+ (1,0) [0|0] ""  CLU
   SG_ Byte5_Data_4E6 : 47|8@0+ (1,0) [0|0] ""  CLU
   SG_ Byte6_Data_4E6 : 55|8@0+ (1,0) [0|0] ""  CLU
   SG_ Byte7_Data_4E6 : 63|8@0+ (1,0) [0|0] ""  CLU

BO_ 1255 TP_CLU_MLT_HU: 8 CLU
   SG_ Byte0_TCP_4E7 : 7|8@0+ (1,0) [0|0] ""  H_U
   SG_ Byte1_Data_4E7 : 15|8@0+ (1,0) [0|0] ""  H_U
   SG_ Byte2_Data_4E7 : 23|8@0+ (1,0) [0|0] ""  H_U
   SG_ Byte3_Data_4E7 : 31|8@0+ (1,0) [0|0] ""  H_U
   SG_ Byte4_Data_4E7 : 39|8@0+ (1,0) [0|0] ""  H_U
   SG_ Byte5_Data_4E7 : 47|8@0+ (1,0) [0|0] ""  H_U
   SG_ Byte6_Data_4E7 : 55|8@0+ (1,0) [0|0] ""  H_U
   SG_ Byte7_Data_4E7 : 63|8@0+ (1,0) [0|0] ""  H_U

BO_ 1256 TP_HU_FM_CLU: 8 H_U
   SG_ Byte0_TCP_4E8 : 7|8@0+ (1,0) [0|0] ""  CLU
   SG_ Byte1_Data_4E8 : 15|8@0+ (1,0) [0|0] ""  CLU
   SG_ Byte2_Data_4E8 : 23|8@0+ (1,0) [0|0] ""  CLU
   SG_ Byte3_Data_4E8 : 31|8@0+ (1,0) [0|0] ""  CLU
   SG_ Byte4_Data_4E8 : 39|8@0+ (1,0) [0|0] ""  CLU
   SG_ Byte5_Data_4E8 : 47|8@0+ (1,0) [0|0] ""  CLU
   SG_ Byte6_Data_4E8 : 55|8@0+ (1,0) [0|0] ""  CLU
   SG_ Byte7_Data_4E8 : 63|8@0+ (1,0) [0|0] ""  CLU

BO_ 1257 TP_CLU_FM_HU: 8 CLU
   SG_ Byte0_TCP_4E9 : 7|8@0+ (1,0) [0|0] ""  H_U
   SG_ Byte1_Data_4E9 : 15|8@0+ (1,0) [0|0] ""  H_U
   SG_ Byte2_Data_4E9 : 23|8@0+ (1,0) [0|0] ""  H_U
   SG_ Byte3_Data_4E9 : 31|8@0+ (1,0) [0|0] ""  H_U
   SG_ Byte4_Data_4E9 : 39|8@0+ (1,0) [0|0] ""  H_U
   SG_ Byte5_Data_4E9 : 47|8@0+ (1,0) [0|0] ""  H_U
   SG_ Byte6_Data_4E9 : 55|8@0+ (1,0) [0|0] ""  H_U
   SG_ Byte7_Data_4E9 : 63|8@0+ (1,0) [0|0] ""  H_U

BO_ 1258 TP_HU_MP_CLU: 8 H_U
   SG_ Byte0_TCP_4EA : 7|8@0+ (1,0) [0|0] ""  CLU
   SG_ Byte1_Data_4EA : 15|8@0+ (1,0) [0|0] ""  CLU
   SG_ Byte2_Data_4EA : 23|8@0+ (1,0) [0|0] ""  CLU
   SG_ Byte3_Data_4EA : 31|8@0+ (1,0) [0|0] ""  CLU
   SG_ Byte4_Data_4EA : 39|8@0+ (1,0) [0|0] ""  CLU
   SG_ Byte5_Data_4EA : 47|8@0+ (1,0) [0|0] ""  CLU
   SG_ Byte6_Data_4EA : 55|8@0+ (1,0) [0|0] ""  CLU
   SG_ Byte7_Data_4EA : 63|8@0+ (1,0) [0|0] ""  CLU

BO_ 1259 TP_CLU_MP_HU: 8 CLU
   SG_ Byte0_TCP_4EB : 7|8@0+ (1,0) [0|0] ""  H_U
   SG_ Byte1_Data_4EB : 15|8@0+ (1,0) [0|0] ""  H_U
   SG_ Byte2_Data_4EB : 23|8@0+ (1,0) [0|0] ""  H_U
   SG_ Byte3_Data_4EB : 31|8@0+ (1,0) [0|0] ""  H_U
   SG_ Byte4_Data_4EB : 39|8@0+ (1,0) [0|0] ""  H_U
   SG_ Byte5_Data_4EB : 47|8@0+ (1,0) [0|0] ""  H_U
   SG_ Byte6_Data_4EB : 55|8@0+ (1,0) [0|0] ""  H_U
   SG_ Byte7_Data_4EB : 63|8@0+ (1,0) [0|0] ""  H_U

BO_ 1260 TP_HU_DLNA_CLU: 8 H_U
   SG_ Byte0_TCP_4EC : 7|8@0+ (1,0) [0|0] ""  CLU
   SG_ Byte1_Data_4EC : 15|8@0+ (1,0) [0|0] ""  CLU
   SG_ Byte2_Data_4EC : 23|8@0+ (1,0) [0|0] ""  CLU
   SG_ Byte3_Data_4EC : 31|8@0+ (1,0) [0|0] ""  CLU
   SG_ Byte4_Data_4EC : 39|8@0+ (1,0) [0|0] ""  CLU
   SG_ Byte5_Data_4EC : 47|8@0+ (1,0) [0|0] ""  CLU
   SG_ Byte6_Data_4EC : 55|8@0+ (1,0) [0|0] ""  CLU
   SG_ Byte7_Data_4EC : 63|8@0+ (1,0) [0|0] ""  CLU

BO_ 1261 TP_CLU_DLNA_HU: 8 CLU
   SG_ Byte0_TCP_4ED : 7|8@0+ (1,0) [0|0] ""  H_U
   SG_ Byte1_Data_4ED : 15|8@0+ (1,0) [0|0] ""  H_U
   SG_ Byte2_Data_4ED : 23|8@0+ (1,0) [0|0] ""  H_U
   SG_ Byte3_Data_4ED : 31|8@0+ (1,0) [0|0] ""  H_U
   SG_ Byte4_Data_4ED : 39|8@0+ (1,0) [0|0] ""  H_U
   SG_ Byte5_Data_4ED : 47|8@0+ (1,0) [0|0] ""  H_U
   SG_ Byte6_Data_4ED : 55|8@0+ (1,0) [0|0] ""  H_U
   SG_ Byte7_Data_4ED : 63|8@0+ (1,0) [0|0] ""  H_U

BO_ 1262 TP_HU_IBOX_CLU: 8 H_U
   SG_ Byte0_TCP_4EE : 7|8@0+ (1,0) [0|0] ""  CLU
   SG_ Byte1_Data_4EE : 15|8@0+ (1,0) [0|0] ""  CLU
   SG_ Byte2_Data_4EE : 23|8@0+ (1,0) [0|0] ""  CLU
   SG_ Byte3_Data_4EE : 31|8@0+ (1,0) [0|0] ""  CLU
   SG_ Byte4_Data_4EE : 39|8@0+ (1,0) [0|0] ""  CLU
   SG_ Byte5_Data_4EE : 47|8@0+ (1,0) [0|0] ""  CLU
   SG_ Byte6_Data_4EE : 55|8@0+ (1,0) [0|0] ""  CLU
   SG_ Byte7_Data_4EE : 63|8@0+ (1,0) [0|0] ""  CLU

BO_ 1263 TP_CLU_IBOX_HU: 8 CLU
   SG_ Byte0_TCP_4EF : 7|8@0+ (1,0) [0|0] ""  H_U
   SG_ Byte1_Data_4EF : 15|8@0+ (1,0) [0|0] ""  H_U
   SG_ Byte2_Data_4EF : 23|8@0+ (1,0) [0|0] ""  H_U
   SG_ Byte3_Data_4EF : 31|8@0+ (1,0) [0|0] ""  H_U
   SG_ Byte4_Data_4EF : 39|8@0+ (1,0) [0|0] ""  H_U
   SG_ Byte5_Data_4EF : 47|8@0+ (1,0) [0|0] ""  H_U
   SG_ Byte6_Data_4EF : 55|8@0+ (1,0) [0|0] ""  H_U
   SG_ Byte7_Data_4EF : 63|8@0+ (1,0) [0|0] ""  H_U

BO_ 1264 CLU1: 8 XXX
   SG_ CF_Clu_CruiseSwState : 0|3@1+ (1,0) [0|7] "" XXX
   SG_ CF_Blr_MaxStat : 3|1@1+ (1,0) [0|1] "" XXX
   SG_ CF_Clu_SldMainSW : 4|1@1+ (1,0) [0|1] "" XXX
   SG_ CF_Clu_ParityBit1 : 5|1@1+ (1,0) [0|1] "pulse count" XXX
   SG_ CF_Clu_SPEED_UNIT : 6|1@1+ (1,0) [0|1] "" XXX
   SG_ CF_Clu_ParkBrakeSw : 7|1@1+ (1,0) [0|1] "" XXX
   SG_ CF_Clu_Vanz : 8|9@1+ (0.5,0) [0|255.5] "km/h or MPH" XXX
   SG_ CF_Clu_AliveCounter : 17|7@1+ (1,0) [0|127] "" XXX
   SG_ CF_Clu_CruiseSwMain : 24|1@1+ (1,0) [0|1] "" XXX
   SG_ CF_Clu_VanzDecimal : 25|2@1+ (1,0) [0|0.375] "" XXX
   SG_ VEHICLE_INFO : 27|3@1+ (1,0) [0|7] "" XXX
   SG_ CF_Clu_StrRlyState : 30|1@1+ (1,0) [0|1] "" XXX
   SG_ CF_Clu_SMKOption : 31|1@1+ (1,0) [0|1] "" XXX
   SG_ R_TqAcnOutC : 32|8@1+ (1,0) [0|51] "Nm" XXX
   SG_ CF_Clu_Odometer : 40|24@1+ (0.1,0) [0|1.67772e+006] "km" XXX

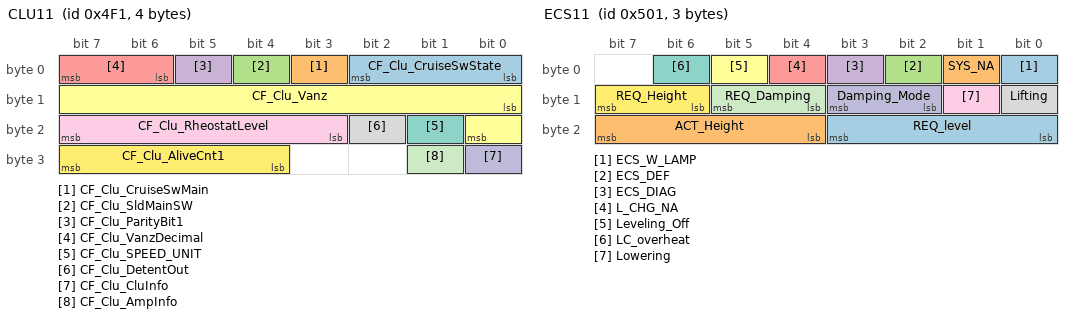
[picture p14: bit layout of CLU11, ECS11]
BO_ 1265 CLU11: 4 CLU
   SG_ CF_Clu_CruiseSwState : 0|3@1+ (1.0,0.0) [0.0|7.0] ""  EMS,LDWS_LKAS,SCC
   SG_ CF_Clu_CruiseSwMain : 3|1@1+ (1.0,0.0) [0.0|1.0] ""  EMS,LDWS_LKAS,SCC
   SG_ CF_Clu_SldMainSW : 4|1@1+ (1.0,0.0) [0.0|1.0] ""  EMS
   SG_ CF_Clu_ParityBit1 : 5|1@1+ (1.0,0.0) [0.0|1.0] "pulse count"  EMS
   SG_ CF_Clu_VanzDecimal : 6|2@1+ (0.125,0.0) [0.0|0.375] ""  EMS
   SG_ CF_Clu_Vanz : 8|9@1+ (0.5,0.0) [0.0|255.5] "km/h or MPH"  BCM,CUBIS,EMS,IBOX,LDWS_LKAS,MDPS,SCC
   SG_ CF_Clu_SPEED_UNIT : 17|1@1+ (1.0,0.0) [0.0|1.0] ""  BCM,CUBIS,EMS,IBOX,LDWS_LKAS,MDPS,SCC
   SG_ CF_Clu_DetentOut : 18|1@1+ (1.0,0.0) [0.0|1.0] ""  AVM,BCM,LCA,PGS,SPAS
   SG_ CF_Clu_RheostatLevel : 19|5@1+ (1.0,0.0) [0.0|31.0] ""  AVM,BCM,LCA,PGS,SPAS
   SG_ CF_Clu_CluInfo : 24|1@1+ (1.0,0.0) [0.0|1.0] ""  BCM
   SG_ CF_Clu_AmpInfo : 25|1@1+ (1.0,0.0) [0.0|1.0] ""  BCM
   SG_ CF_Clu_AliveCnt1 : 28|4@1+ (1.0,0.0) [0.0|15.0] ""  AHLS,EMS,EPB,LDWS_LKAS,MDPS,SCC

BO_ 1266 TP_HU_CARPLAY_CLU: 8 H_U
   SG_ Byte0_TCP_4F2 : 7|8@0+ (1,0) [0|0] ""  CLU
   SG_ Byte1_Data_4F2 : 15|8@0+ (1,0) [0|0] ""  CLU
   SG_ Byte2_Data_4F2 : 23|8@0+ (1,0) [0|0] ""  CLU
   SG_ Byte3_Data_4F2 : 31|8@0+ (1,0) [0|0] ""  CLU
   SG_ Byte4_Data_4F2 : 39|8@0+ (1,0) [0|0] ""  CLU
   SG_ Byte5_Data_4F2 : 47|8@0+ (1,0) [0|0] ""  CLU
   SG_ Byte6_Data_4F2 : 55|8@0+ (1,0) [0|0] ""  CLU
   SG_ Byte7_Data_4F2 : 63|8@0+ (1,0) [0|0] ""  CLU

BO_ 1267 TP_CLU_CARPLAY_HU: 8 CLU
   SG_ Byte0_TCP_4F3 : 7|8@0+ (1,0) [0|0] ""  H_U
   SG_ Byte1_Data_4F3 : 15|8@0+ (1,0) [0|0] ""  H_U
   SG_ Byte2_Data_4F3 : 23|8@0+ (1,0) [0|0] ""  H_U
   SG_ Byte3_Data_4F3 : 31|8@0+ (1,0) [0|0] ""  H_U
   SG_ Byte4_Data_4F3 : 39|8@0+ (1,0) [0|0] ""  H_U
   SG_ Byte5_Data_4F3 : 47|8@0+ (1,0) [0|0] ""  H_U
   SG_ Byte6_Data_4F3 : 55|8@0+ (1,0) [0|0] ""  H_U
   SG_ Byte7_Data_4F3 : 63|8@0+ (1,0) [0|0] ""  H_U

BO_ 1268 TP_HU_ANDAUTO_CLU: 8 H_U
   SG_ Byte0_TCP_4F4 : 7|8@0+ (1,0) [0|0] ""  CLU
   SG_ Byte1_Data_4F4 : 15|8@0+ (1,0) [0|0] ""  CLU
   SG_ Byte2_Data_4F4 : 23|8@0+ (1,0) [0|0] ""  CLU
   SG_ Byte3_Data_4F4 : 31|8@0+ (1,0) [0|0] ""  CLU
   SG_ Byte4_Data_4F4 : 39|8@0+ (1,0) [0|0] ""  CLU
   SG_ Byte5_Data_4F4 : 47|8@0+ (1,0) [0|0] ""  CLU
   SG_ Byte6_Data_4F4 : 55|8@0+ (1,0) [0|0] ""  CLU
   SG_ Byte7_Data_4F4 : 63|8@0+ (1,0) [0|0] ""  CLU

BO_ 1269 TP_CLU_ANDAUTO_HU: 8 CLU
   SG_ Byte0_TCP_4F5 : 7|8@0+ (1,0) [0|0] ""  H_U
   SG_ Byte1_Data_4F5 : 15|8@0+ (1,0) [0|0] ""  H_U
   SG_ Byte2_Data_4F5 : 23|8@0+ (1,0) [0|0] ""  H_U
   SG_ Byte3_Data_4F5 : 31|8@0+ (1,0) [0|0] ""  H_U
   SG_ Byte4_Data_4F5 : 39|8@0+ (1,0) [0|0] ""  H_U
   SG_ Byte5_Data_4F5 : 47|8@0+ (1,0) [0|0] ""  H_U
   SG_ Byte6_Data_4F5 : 55|8@0+ (1,0) [0|0] ""  H_U
   SG_ Byte7_Data_4F5 : 63|8@0+ (1,0) [0|0] ""  H_U

BO_ 1280 ACU14: 1 ACU
   SG_ CF_SWL_Ind : 0|2@1+ (1.0,0.0) [0.0|3.0] ""  CLU
   SG_ CF_TTL_Ind : 2|2@1+ (1.0,0.0) [0.0|3.0] ""  CLU
   SG_ CF_SBR_Ind : 4|2@1+ (1.0,0.0) [0.0|3.0] ""  BCM,CLU

BO_ 1281 ECS11: 3 ECS
   SG_ ECS_W_LAMP : 0|1@1+ (1.0,0.0) [0.0|1.0] ""  CLU,CUBIS,IBOX
   SG_ SYS_NA : 1|1@1+ (1.0,0.0) [0.0|1.0] ""  CLU
   SG_ ECS_DEF : 2|1@1+ (1.0,0.0) [0.0|1.0] ""  CLU
   SG_ ECS_DIAG : 3|1@1+ (1.0,0.0) [0.0|1.0] ""  CLU
   SG_ L_CHG_NA : 4|1@1+ (1.0,0.0) [0.0|1.0] ""  CLU
   SG_ Leveling_Off : 5|1@1+ (1.0,0.0) [0.0|1.0] ""  CLU
   SG_ LC_overheat : 6|1@1+ (1.0,0.0) [0.0|1.0] ""  CLU
   SG_ Lifting : 8|1@1+ (1.0,0.0) [0.0|1.0] ""  CLU
   SG_ Lowering : 9|1@1+ (1.0,0.0) [0.0|1.0] ""  CLU
   SG_ Damping_Mode : 10|2@1+ (1.0,0.0) [0.0|3.0] ""  CLU
   SG_ REQ_Damping : 12|2@1+ (1.0,0.0) [0.0|3.0] ""  CLU
   SG_ REQ_Height : 14|2@1+ (1.0,0.0) [0.0|3.0] ""  CLU
   SG_ REQ_level : 16|4@1+ (1.0,0.0) [0.0|15.0] ""  CLU
   SG_ ACT_Height : 20|4@1+ (1.0,0.0) [0.0|15.0] ""  CLU

BO_ 1282 TCU14: 4 TCU
   SG_ CF_TCU_WarnMsg : 0|3@1+ (1.0,0.0) [0.0|7.0] ""  CLU
   SG_ CF_TCU_WarnImg : 3|1@1+ (1.0,0.0) [0.0|1.0] ""  CLU
   SG_ CF_TCU_WarnSnd : 4|1@1+ (1.0,0.0) [0.0|1.0] ""  CLU
   SG_ CF_Tcu_GSel_BlinkReq : 5|1@1+ (1.0,0.0) [0.0|1.0] ""  CLU,LVR
   SG_ CF_Tcu_StRelStat : 12|1@1+ (1.0,0.0) [0.0|1.0] ""  CLU,EMS,ESC
   SG_ CF_Tcu_DriWarn1 : 13|3@1+ (1.0,0.0) [0.0|7.0] ""  CLU,EMS,ESC
   SG_ CF_Tcu_DriWarn2 : 16|2@1+ (1.0,0.0) [0.0|3.0] ""  CLU,EMS,ESC

BO_ 1284 HU_AMP_P_01: 8 H_U
   SG_ HU_VehicleSpeed : 7|8@0+ (1,0) [0|0] ""  AMP
   SG_ AMP_SetMaxMainVolStep : 9|2@0+ (1,0) [0|0] ""  AMP
   SG_ AMP_LKASWarningOn : 21|2@0+ (1,0) [0|0] ""  AMP
   SG_ AMP_BSDWarningOn : 23|2@0+ (1,0) [0|0] ""  AMP

BO_ 1286 HU_CLU_P_00: 8 H_U
   SG_ NV_EstDist_F : 3|4@0+ (1,0) [0|0] ""  CLU,HUD
   SG_ NV_EstDist_Unit : 7|4@0+ (1,0) [0|0] ""  CLU,HUD
   SG_ NV_EstHour : 15|8@0+ (1,0) [0|0] ""  CLU,HUD
   SG_ NV_EstMin : 23|8@0+ (1,0) [0|0] ""  CLU,HUD
   SG_ NV_Azimuth : 31|8@0+ (1,0) [0|0] ""  CLU,HUD
   SG_ NV_EstDist_I : 39|16@0+ (1,0) [0|0] ""  CLU,HUD
   SG_ NV_EstimTimeType : 49|2@0+ (1,0) [0|0] ""  CGW,CLU,HUD
   SG_ NV_EstimTimeFormat : 51|2@0+ (1,0) [0|0] ""  CGW,CLU,HUD

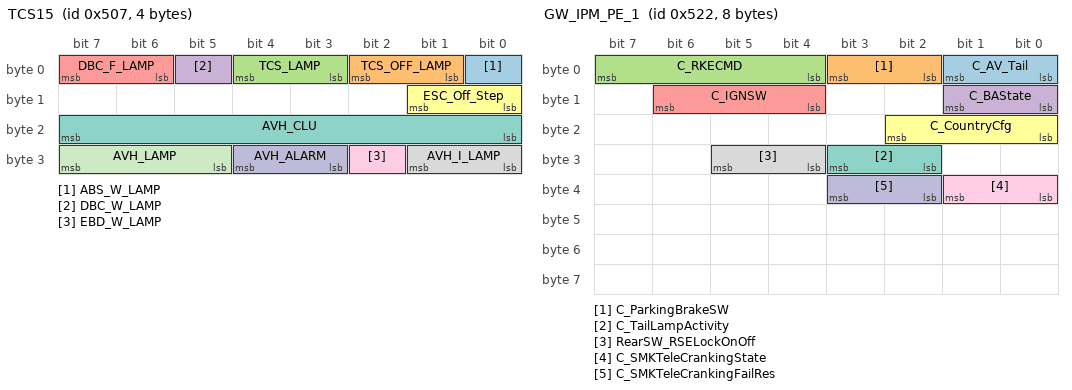
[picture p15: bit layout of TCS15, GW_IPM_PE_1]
BO_ 1287 TCS15: 4 ESC
   SG_ ABS_W_LAMP : 0|1@1+ (1.0,0.0) [0.0|1.0] ""  _4WD,CLU,CUBIS,IBOX
   SG_ TCS_OFF_LAMP : 1|2@1+ (1.0,0.0) [0.0|1.0] ""  _4WD,ACU,CLU
   SG_ TCS_LAMP : 3|2@1+ (1.0,0.0) [0.0|3.0] ""  _4WD,ACU,CLU,CUBIS,IBOX,SCC
   SG_ DBC_W_LAMP : 5|1@1+ (1.0,0.0) [0.0|1.0] ""  _4WD,CLU
   SG_ DBC_F_LAMP : 6|2@1+ (1.0,0.0) [0.0|3.0] ""  _4WD,CLU
   SG_ ESC_Off_Step : 8|2@1+ (1.0,0.0) [0.0|3.0] ""  CLU
   SG_ AVH_CLU : 16|8@1+ (1.0,0.0) [0.0|255.0] ""  CLU,EPB
   SG_ AVH_I_LAMP : 24|2@1+ (1.0,0.0) [0.0|3.0] ""  EPB
   SG_ EBD_W_LAMP : 26|1@1+ (1.0,0.0) [0.0|1.0] ""  _4WD,CLU
   SG_ AVH_ALARM : 27|2@1+ (1.0,0.0) [0.0|3.0] ""  CLU
   SG_ AVH_LAMP : 29|3@1+ (1.0,0.0) [0.0|7.0] ""  CLU,EPB,SPAS

BO_ 1288 HU_CLU_P_02: 8 H_U
   SG_ NV_TIME_TYPE : 3|4@0+ (1,0) [0|0] ""  CLU
   SG_ NV_Hour : 15|8@0+ (1,0) [0|0] ""  CLU
   SG_ NV_Min : 23|8@0+ (1,0) [0|0] ""  CLU

BO_ 1290 SCC13: 8 SCC
   SG_ SCCDrvModeRValue : 0|3@1+ (1.0,0.0) [0.0|7.0] ""  CLU
   SG_ SCC_Equip : 3|1@1+ (1.0,0.0) [0.0|1.0] ""  ESC
   SG_ AebDrvSetStatus : 4|3@1+ (1.0,0.0) [0.0|7.0] ""  CLU,ESC

BO_ 1292 CLU13: 8 CLU
   SG_ CF_Clu_LowfuelWarn : 0|2@1+ (1.0,0.0) [0.0|3.0] ""  BCM,FPCM,IBOX
   SG_ CF_Clu_RefDetMod : 2|1@1+ (1.0,0.0) [0.0|1.0] ""  IBOX
   SG_ CF_Clu_AvgFCU : 3|2@1+ (1.0,0.0) [0.0|3.0] ""  IBOX
   SG_ CF_Clu_AvsmCur : 5|1@1+ (1.0,0.0) [0.0|1.0] ""  ESC,SCC
   SG_ CF_Clu_AvgFCI : 6|10@1+ (0.1,0.0) [0.0|102.2] ""  IBOX
   SG_ CF_Clu_DrivingModeSwi : 16|2@1+ (1.0,0.0) [0.0|3.0] ""  DATC,ECS,EMS,ESC,IAP,MDPS,TCU
   SG_ CF_Clu_FuelDispLvl : 18|5@1+ (1.0,0.0) [0.0|31.0] ""  CGW,IBOX
   SG_ CF_Clu_FlexSteerSW : 23|1@1+ (1.0,0.0) [0.0|1.0] ""  MDPS
   SG_ CF_Clu_DTE : 24|10@1+ (1.0,0.0) [0.0|1023.0] ""  DATC
   SG_ CF_Clu_TripUnit : 34|2@1+ (1.0,0.0) [0.0|3.0] ""  DATC
   SG_ CF_Clu_SWL_Stat : 36|3@1+ (1.0,0.0) [0.0|7.0] ""  ACU,EMS
   SG_ CF_Clu_ActiveEcoSW : 39|1@1+ (1.0,0.0) [0.0|1.0] ""  DATC,EMS,TCU
   SG_ CF_Clu_EcoDriveInf : 40|3@1+ (1.0,0.0) [0.0|7.0] ""  CUBIS,EMS,IAP,IBOX
   SG_ CF_Clu_IsaMainSW : 43|1@1+ (1.0,0.0) [0.0|1.0] ""  EMS
   SG_ CF_Clu_LdwsLkasSW : 56|1@1+ (1.0,0.0) [0.0|1.0] ""  LDWS_LKAS
   SG_ CF_Clu_AltLStatus : 59|1@1+ (1.0,0.0) [0.0|1.0] ""  BCM,DATC,EMS
   SG_ CF_Clu_AliveCnt2 : 60|4@1+ (1.0,0.0) [0.0|15.0] ""  EMS,LDWS_LKAS

BO_ 1301 CLU14: 8 CLU
   SG_ CF_Clu_ADrUNValueSet : 0|3@1+ (1.0,0.0) [0.0|7.0] ""  BCM
   SG_ CF_Clu_ADrLNValueSet : 3|3@1+ (1.0,0.0) [0.0|7.0] ""  BCM
   SG_ CF_Clu_EscortHLNValueSet : 6|2@1+ (1.0,0.0) [0.0|3.0] ""  BCM
   SG_ CF_Clu_DoorLSNValueSet : 8|3@1+ (1.0,0.0) [0.0|7.0] ""  BCM
   SG_ CF_Clu_PSMNValueSet : 11|3@1+ (1.0,0.0) [0.0|7.0] ""  BCM
   SG_ CF_Clu_TTUnlockNValueSet : 14|2@1+ (1.0,0.0) [0.0|3.0] ""  BCM
   SG_ CF_Clu_PTGMNValueSet : 16|2@1+ (1.0,0.0) [0.0|3.0] ""  BCM
   SG_ CF_Clu_SCMNValueSet : 18|2@1+ (1.0,0.0) [0.0|3.0] ""  BCM
   SG_ CF_Clu_WlightNValueSet : 20|2@1+ (1.0,0.0) [0.0|3.0] ""  BCM
   SG_ CF_Clu_TempUnitNValueSet : 22|2@1+ (1.0,0.0) [0.0|3.0] ""  BCM,DATC
   SG_ CF_Clu_MoodLpNValueSet : 24|3@1+ (1.0,0.0) [0.0|7.0] ""  BCM
   SG_ CF_Clu_TrfChgSet : 27|2@1+ (1.0,0.0) [0.0|3.0] ""  AFLS
   SG_ CF_Clu_OTTurnNValueSet : 29|3@1+ (1.0,0.0) [0.0|7.0] ""  BCM
   SG_ CF_Clu_LcaNValueSet : 32|2@1+ (1.0,0.0) [0.0|3.0] ""  LCA
   SG_ CF_Clu_RctaNValueSet : 34|2@1+ (1.0,0.0) [0.0|3.0] ""  LCA
   SG_ CF_Clu_RcwNValueSet : 36|2@1+ (1.0,0.0) [0.0|3.0] ""  LCA
   SG_ CF_Clu_EscOffNValueSet : 38|3@1+ (1.0,0.0) [0.0|7.0] ""  ESC
   SG_ CF_Clu_SccNaviCrvNValueSet : 41|2@1+ (1.0,0.0) [0.0|3.0] ""  SCC
   SG_ CF_Clu_SccNaviCamNValueSet : 43|2@1+ (1.0,0.0) [0.0|3.0] ""  SCC
   SG_ CF_Clu_SccAebNValueSet : 45|2@1+ (1.0,0.0) [0.0|3.0] ""  SCC
   SG_ CF_Clu_LkasModeNValueSet : 47|2@1+ (1.0,0.0) [0.0|3.0] ""  LDWS_LKAS
   SG_ CF_Clu_FcwNValueSet : 51|2@1+ (1.0,0.0) [0.0|3.0] ""  LDWS_LKAS
   SG_ CF_Clu_PasSpkrLvNValueSet : 53|3@1+ (1.0,0.0) [0.0|7.0] ""  BCM
   SG_ CF_Clu_SccDrvModeNValueSet : 56|3@1+ (1.0,0.0) [0.0|7.0] ""  SCC
   SG_ CF_Clu_HAnBNValueSet : 59|2@1+ (1.0,0.0) [0.0|3.0] ""  BCM
   SG_ CF_Clu_HfreeTrunkTgNValueSet : 61|3@1+ (1.0,0.0) [0.0|7.0] ""  BCM

BO_ 1307 CLU16: 8 CLU
   SG_ CF_Clu_TirePressUnitNValueSet : 0|3@1+ (1.0,0.0) [0.0|7.0] ""  TPMS
   SG_ CF_Clu_SlifNValueSet : 3|2@1+ (1.0,0.0) [0.0|3.0] ""  LDWS_LKAS
   SG_ CF_Clu_RearWiperNValueSet : 12|2@1+ (1.0,0.0) [0.0|3.0] ""  BCM

BO_ 1312 CGW3: 8 BCM
   SG_ CR_Photosensor_LH : 0|8@1+ (78.125,0.0) [0.0|20000.0] ""  DATC,DATC
   SG_ CR_Photosensor_RH : 10|8@1+ (78.125,0.0) [0.0|20000.0] ""  DATC,DATC
   SG_ CF_Hoodsw_memory : 22|2@1+ (1.0,0.0) [0.0|3.0] ""  EMS,EMS
   SG_ C_MirOutTempSns : 24|8@1+ (0.5,-40.5) [-40.0|60.0] "deg"  AAF,CLU,DATC,EMS,SPAS,AAF,DATC,EMS,SPAS

BO_ 1313 GW_DDM_PE: 8 BCM
   SG_ C_DRVDoorStatus : 0|2@1+ (1.0,0.0) [0.0|3.0] ""  CLU
   SG_ C_ASTDoorStatus : 2|2@1+ (1.0,0.0) [0.0|3.0] ""  CLU
   SG_ C_RLDoorStatus : 4|2@1+ (1.0,0.0) [0.0|3.0] ""  CLU
   SG_ C_RRDoorStatus : 6|2@1+ (1.0,0.0) [0.0|3.0] ""  CLU
   SG_ C_TrunkStatus : 8|2@1+ (1.0,0.0) [0.0|3.0] ""  CLU
   SG_ C_OSMirrorStatus : 10|2@1+ (1.0,0.0) [0.0|3.0] ""  CLU

BO_ 1314 GW_IPM_PE_1: 8 BCM
   SG_ C_AV_Tail : 0|2@1+ (1.0,0.0) [0.0|3.0] ""  CLU
   SG_ C_ParkingBrakeSW : 2|2@1+ (1.0,0.0) [0.0|3.0] ""  CLU
   SG_ C_RKECMD : 4|4@1+ (1.0,0.0) [0.0|15.0] ""  CLU
   SG_ C_BAState : 8|2@1+ (1.0,0.0) [0.0|3.0] ""  CLU
   SG_ C_IGNSW : 12|3@1+ (1.0,0.0) [0.0|7.0] ""  CLU
   SG_ C_CountryCfg : 16|3@1+ (1.0,0.0) [0.0|7.0] ""  CLU
   SG_ C_TailLampActivity : 26|2@1+ (1.0,0.0) [0.0|3.0] ""  CLU
   SG_ RearSW_RSELockOnOff : 28|2@1+ (1.0,0.0) [0.0|3.0] ""  CLU
   SG_ C_SMKTeleCrankingState : 32|2@1+ (1.0,0.0) [0.0|3.0] ""  CLU
   SG_ C_SMKTeleCrankingFailRes : 34|2@1+ (1.0,0.0) [0.0|3.0] ""  CLU

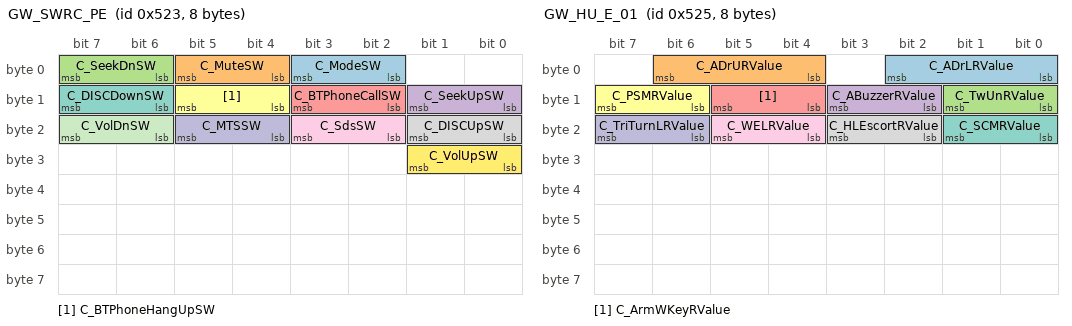
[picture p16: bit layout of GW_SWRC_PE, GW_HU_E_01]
BO_ 1315 GW_SWRC_PE: 8 BCM
   SG_ C_ModeSW : 2|2@1+ (1.0,0.0) [0.0|3.0] ""  CLU
   SG_ C_MuteSW : 4|2@1+ (1.0,0.0) [0.0|3.0] ""  CLU
   SG_ C_SeekDnSW : 6|2@1+ (1.0,0.0) [0.0|3.0] ""  CLU
   SG_ C_SeekUpSW : 8|2@1+ (1.0,0.0) [0.0|3.0] ""  CLU
   SG_ C_BTPhoneCallSW : 10|2@1+ (1.0,0.0) [0.0|3.0] ""  CLU
   SG_ C_BTPhoneHangUpSW : 12|2@1+ (1.0,0.0) [0.0|3.0] ""  CLU
   SG_ C_DISCDownSW : 14|2@1+ (1.0,0.0) [0.0|3.0] ""  CLU
   SG_ C_DISCUpSW : 16|2@1+ (1.0,0.0) [0.0|3.0] ""  CLU
   SG_ C_SdsSW : 18|2@1+ (1.0,0.0) [0.0|3.0] ""  CLU
   SG_ C_MTSSW : 20|2@1+ (1.0,0.0) [0.0|3.0] ""  CLU
   SG_ C_VolDnSW : 22|2@1+ (1.0,0.0) [0.0|3.0] ""  CLU
   SG_ C_VolUpSW : 24|2@1+ (1.0,0.0) [0.0|3.0] ""  CLU

BO_ 1316 GW_HU_E_00: 8 BCM
   SG_ C_ADrLUNValueConf : 0|2@1+ (1.0,0.0) [0.0|3.0] ""  CLU
   SG_ C_TwUnNValueConf : 2|2@1+ (1.0,0.0) [0.0|3.0] ""  CLU
   SG_ C_AlarmNValueConf : 4|2@1+ (1.0,0.0) [0.0|3.0] ""  CLU
   SG_ C_PSMNValueConf : 6|2@1+ (1.0,0.0) [0.0|3.0] ""  CLU
   SG_ C_SCMNValueConf : 8|2@1+ (1.0,0.0) [0.0|3.0] ""  CLU
   SG_ C_HLEscortNValueConf : 10|2@1+ (1.0,0.0) [0.0|3.0] ""  CLU
   SG_ C_WELNValueConf : 12|2@1+ (1.0,0.0) [0.0|3.0] ""  CLU
   SG_ C_TriTurnLNValueConf : 14|2@1+ (1.0,0.0) [0.0|3.0] ""  CLU

BO_ 1317 GW_HU_E_01: 8 BCM
   SG_ C_ADrLRValue : 0|3@1+ (1.0,0.0) [0.0|7.0] ""  CLU
   SG_ C_ADrURValue : 4|3@1+ (1.0,0.0) [0.0|7.0] ""  CLU
   SG_ C_TwUnRValue : 8|2@1+ (1.0,0.0) [0.0|3.0] ""  CLU
   SG_ C_ABuzzerRValue : 10|2@1+ (1.0,0.0) [0.0|3.0] ""  CLU
   SG_ C_ArmWKeyRValue : 12|2@1+ (1.0,0.0) [0.0|3.0] ""  CLU
   SG_ C_PSMRValue : 14|2@1+ (1.0,0.0) [0.0|3.0] ""  CLU
   SG_ C_SCMRValue : 16|2@1+ (1.0,0.0) [0.0|3.0] ""  CLU
   SG_ C_HLEscortRValue : 18|2@1+ (1.0,0.0) [0.0|3.0] ""  CLU
   SG_ C_WELRValue : 20|2@1+ (1.0,0.0) [0.0|3.0] ""  CLU
   SG_ C_TriTurnLRValue : 22|2@1+ (1.0,0.0) [0.0|3.0] ""  CLU

BO_ 1318 HU_GW_E_00: 8 CLU
   SG_ C_ADrLURValueReq : 0|2@1+ (1.0,0.0) [0.0|3.0] ""  BCM
   SG_ C_TwUnRValueReq : 2|2@1+ (1.0,0.0) [0.0|3.0] ""  BCM
   SG_ C_AlarmRValueReq : 4|2@1+ (1.0,0.0) [0.0|3.0] ""  BCM
   SG_ C_IMSRValueReq : 6|2@1+ (1.0,0.0) [0.0|3.0] ""  BCM
   SG_ C_HLEscortRValueReq : 8|2@1+ (1.0,0.0) [0.0|3.0] ""  BCM
   SG_ C_WELRValueReq : 10|2@1+ (1.0,0.0) [0.0|3.0] ""  BCM
   SG_ C_TriTurnLRValueReq : 12|2@1+ (1.0,0.0) [0.0|3.0] ""  BCM
   SG_ C_SNVWarnRValueReq : 14|2@1+ (1.0,0.0) [0.0|3.0] ""  BCM
   SG_ C_LkasWarnRValueReq : 16|2@1+ (1.0,0.0) [0.0|3.0] ""  BCM

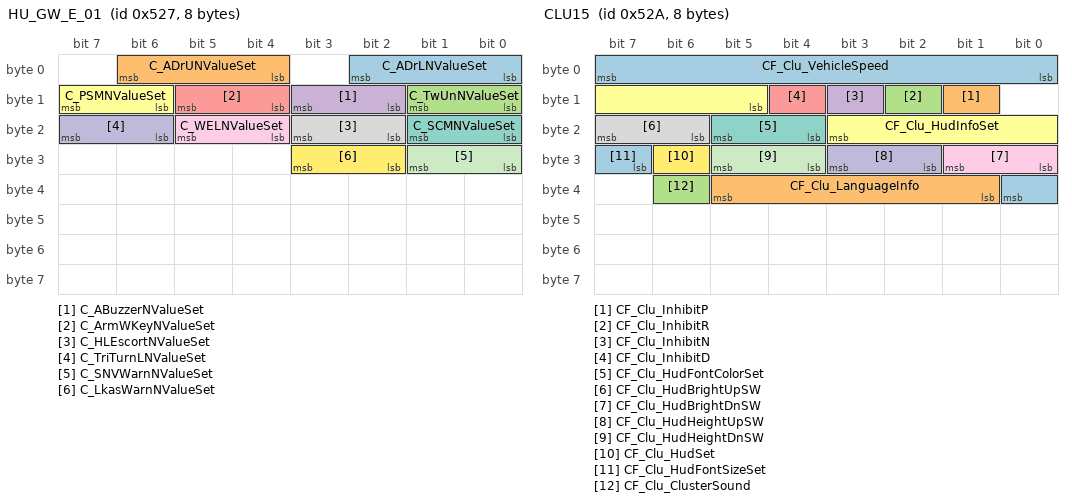
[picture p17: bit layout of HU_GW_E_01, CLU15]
BO_ 1319 HU_GW_E_01: 8 CLU
   SG_ C_ADrLNValueSet : 0|3@1+ (1.0,0.0) [0.0|7.0] ""  BCM
   SG_ C_ADrUNValueSet : 4|3@1+ (1.0,0.0) [0.0|7.0] ""  BCM
   SG_ C_TwUnNValueSet : 8|2@1+ (1.0,0.0) [0.0|3.0] ""  BCM
   SG_ C_ABuzzerNValueSet : 10|2@1+ (1.0,0.0) [0.0|3.0] ""  BCM
   SG_ C_ArmWKeyNValueSet : 12|2@1+ (1.0,0.0) [0.0|3.0] ""  BCM
   SG_ C_PSMNValueSet : 14|2@1+ (1.0,0.0) [0.0|3.0] ""  BCM
   SG_ C_SCMNValueSet : 16|2@1+ (1.0,0.0) [0.0|3.0] ""  BCM
   SG_ C_HLEscortNValueSet : 18|2@1+ (1.0,0.0) [0.0|3.0] ""  BCM
   SG_ C_WELNValueSet : 20|2@1+ (1.0,0.0) [0.0|3.0] ""  BCM
   SG_ C_TriTurnLNValueSet : 22|2@1+ (1.0,0.0) [0.0|3.0] ""  BCM
   SG_ C_SNVWarnNValueSet : 24|2@1+ (1.0,0.0) [0.0|3.0] ""  BCM
   SG_ C_LkasWarnNValueSet : 26|2@1+ (1.0,0.0) [0.0|3.0] ""  BCM

BO_ 1322 CLU15: 8 CLU
   SG_ CF_Clu_VehicleSpeed : 0|8@1+ (1.0,0.0) [0.0|255.0] ""  BCM
   SG_ CF_Clu_InhibitP : 9|1@1+ (1.0,0.0) [0.0|1.0] ""  BCM
   SG_ CF_Clu_InhibitR : 10|1@1+ (1.0,0.0) [0.0|1.0] ""  BCM
   SG_ CF_Clu_InhibitN : 11|1@1+ (1.0,0.0) [0.0|1.0] ""  BCM
   SG_ CF_Clu_InhibitD : 12|1@1+ (1.0,0.0) [0.0|1.0] ""  BCM
   SG_ CF_Clu_HudInfoSet : 13|7@1+ (1.0,0.0) [0.0|127.0] ""  HUD
   SG_ CF_Clu_HudFontColorSet : 20|2@1+ (1.0,0.0) [0.0|3.0] ""  HUD
   SG_ CF_Clu_HudBrightUpSW : 22|2@1+ (1.0,0.0) [0.0|3.0] ""  HUD
   SG_ CF_Clu_HudBrightDnSW : 24|2@1+ (1.0,0.0) [0.0|3.0] ""  HUD
   SG_ CF_Clu_HudHeightUpSW : 26|2@1+ (1.0,0.0) [0.0|3.0] ""  HUD
   SG_ CF_Clu_HudHeightDnSW : 28|2@1+ (1.0,0.0) [0.0|3.0] ""  HUD
   SG_ CF_Clu_HudSet : 30|1@1+ (1.0,0.0) [0.0|1.0] ""  HUD
   SG_ CF_Clu_HudFontSizeSet : 31|2@1+ (1.0,0.0) [0.0|3.0] ""  HUD
   SG_ CF_Clu_LanguageInfo : 33|5@1+ (1.0,0.0) [0.0|31.0] ""  BCM,PGS
   SG_ CF_Clu_ClusterSound : 38|1@1- (1.0,0.0) [0.0|0.0] ""  BCM,CGW,FATC

BO_ 1329 DATC_P_02: 8 CLU
   SG_ DATC_AmbientTemp_C : 7|8@0+ (1,0) [0|0] ""  H_U,MON
   SG_ DATC_AmbientTemp_F : 23|8@0+ (1,0) [0|0] ""  H_U,MON

BO_ 1338 TMU_GW_E_01: 8 CLU
   SG_ CF_Gway_TeleReqDrLock : 0|2@1+ (1.0,0.0) [0.0|3.0] ""  BCM
   SG_ CF_Gway_TeleReqDrUnlock : 2|2@1+ (1.0,0.0) [0.0|3.0] ""  BCM
   SG_ CF_Gway_TeleReqHazard : 4|2@1+ (1.0,0.0) [0.0|3.0] ""  BCM
   SG_ CF_Gway_TeleReqHorn : 6|2@1+ (1.0,0.0) [0.0|3.0] ""  BCM
   SG_ CF_Gway_TeleReqEngineOperate : 8|2@1+ (1.0,0.0) [0.0|3.0] ""  BCM

BO_ 1342 LKAS12: 6 LDWS_LKAS
   SG_ CF_Lkas_TsrSlifOpt : 10|2@1+ (1.0,0.0) [0.0|3.0] ""  CLU
   SG_ CF_LkasTsrStatus : 12|2@1+ (1.0,0.0) [0.0|3.0] ""  CLU
   SG_ CF_Lkas_TsrSpeed_Display_Clu : 16|8@1+ (1.0,0.0) [0.0|255.0] ""  CLU
   SG_ CF_LkasTsrSpeed_Display_Navi : 24|8@1+ (1.0,0.0) [0.0|255.0] ""  BCM,CLU
   SG_ CF_Lkas_TsrAddinfo_Display : 32|2@1+ (1.0,0.0) [0.0|3.0] ""  CLU

BO_ 1344 TMU_HU_P_01: 8 TMU
   SG_ TMU_Arrow : 3|2@0+ (1,0) [0|0] ""  H_U
   SG_ TMU_ReFill_Info : 5|2@0+ (1,0) [0|0] ""  H_U
   SG_ TMU_AverageMPG : 1|10@0+ (1,0) [0|0] ""  H_U
   SG_ TMU_TotalMPG : 23|10@0+ (1,0) [0|0] ""  H_U
   SG_ TMU_RewardStar : 37|14@0+ (1,0) [0|0] ""  H_U

BO_ 1345 CGW1: 8 BCM
   SG_ CF_Gway_IGNSw : 0|3@1+ (1.0,0.0) [0.0|7.0] ""  AVM,CLU,ECS,EMS,EPB,ESC,IBOX,LVR,MDPS,SAS,SCC,ECS,EMS,EPB,ESC,IBOX,LVR,MDPS,SAS,SCC
   SG_ CF_Gway_RKECmd : 3|3@1+ (1.0,0.0) [0.0|7.0] ""  CLU,ECS,EMS,IBOX,ECS,EMS,IBOX
   SG_ CF_Gway_DrvKeyLockSw : 6|1@1+ (1.0,0.0) [0.0|1.0] ""  ECS,EMS,IBOX,ECS,EMS,IBOX
   SG_ CF_Gway_DrvKeyUnlockSw : 7|1@1+ (1.0,0.0) [0.0|1.0] ""  ECS,EMS,IBOX,ECS,EMS,IBOX
   SG_ CF_Gway_DrvDrSw : 8|2@1+ (1.0,0.0) [0.0|3.0] ""  CLU,ECS,EMS,EPB,ESC,IBOX,SCC,TCU,ECS,EMS,EPB,ESC,IBOX,SCC,TCU
   SG_ CF_Gway_DrvSeatBeltSw : 10|2@1+ (1.0,0.0) [0.0|3.0] ""  EMS,EPB,ESC,IBOX,PSB,TCU,EMS,EPB,ESC,IBOX,PSB,TCU
   SG_ CF_Gway_TrunkTgSw : 12|2@1+ (1.0,0.0) [0.0|3.0] ""  CLU,ECS,EMS,EPB,ESC,IBOX,ECS,EMS,EPB,ESC,IBOX
   SG_ CF_Gway_AstSeatBeltSw : 14|2@1+ (1.0,0.0) [0.0|3.0] ""  IBOX,PSB,IBOX,PSB
   SG_ CF_Gway_SMKOption : 16|1@1+ (1.0,0.0) [0.0|1.0] ""  CLU,EMS,IBOX,EMS,IBOX,SMK
   SG_ CF_Gway_HoodSw : 17|2@1+ (1.0,0.0) [0.0|3.0] ""  CLU,EMS,EPB,ESC,IBOX,EMS,EPB,ESC,IBOX
   SG_ CF_Gway_TurnSigLh : 19|2@1+ (1.0,0.0) [0.0|3.0] ""  CLU,EMS,IBOX,LCA,LDWS_LKAS,SCC,EMS,IBOX,LCA,LDWS_LKAS,SCC
   SG_ CF_Gway_WiperIntT : 21|3@1+ (1.0,0.0) [0.0|7.0] ""  CLU,EMS,IBOX,LDWS_LKAS,EMS,ESC,IBOX,LDWS_LKAS
   SG_ CF_Gway_WiperIntSw : 24|1@1+ (1.0,0.0) [0.0|1.0] ""  CLU,EMS,IBOX,LDWS_LKAS,EMS,ESC,IBOX,LDWS_LKAS
   SG_ CF_Gway_WiperLowSw : 25|1@1+ (1.0,0.0) [0.0|1.0] ""  CLU,EMS,IBOX,LDWS_LKAS,EMS,ESC,IBOX,LDWS_LKAS
   SG_ CF_Gway_WiperHighSw : 26|1@1+ (1.0,0.0) [0.0|1.0] ""  CLU,EMS,IBOX,LDWS_LKAS,EMS,ESC,IBOX,LDWS_LKAS
   SG_ CF_Gway_WiperAutoSw : 27|1@1+ (1.0,0.0) [0.0|1.0] ""  CLU,EMS,IBOX,LDWS_LKAS,EMS,ESC,IBOX,LDWS_LKAS
   SG_ CF_Gway_RainSnsState : 28|3@1+ (1.0,0.0) [0.0|7.0] ""  AFLS,EMS,IBOX,LDWS_LKAS,AFLS,EMS,ESC,IBOX,LDWS_LKAS
   SG_ CF_Gway_HeadLampLow : 31|1@1+ (1.0,0.0) [0.0|1.0] ""  AFLS,CLU,EMS,IBOX,LDWS_LKAS,SNV,AFLS,EMS,IBOX,LDWS_LKAS,SNV
   SG_ CF_Gway_HeadLampHigh : 32|1@1+ (1.0,0.0) [0.0|1.0] ""  AFLS,CLU,EMS,IBOX,LDWS_LKAS,AFLS,EMS,IBOX,LDWS_LKAS
   SG_ CF_Gway_HazardSw : 33|2@1+ (1.0,0.0) [0.0|3.0] ""  ABS,EMS,ESC,IBOX,LCA,LDWS_LKAS,ABS,EMS,ESC,IBOX,LCA,LDWS_LKAS
   SG_ CF_Gway_AstDrSw : 35|1@1+ (1.0,0.0) [0.0|1.0] ""  CLU,IBOX,IBOX
   SG_ CF_Gway_DefoggerRly : 36|1@1+ (1.0,0.0) [0.0|1.0] ""  EMS,IBOX,EMS,IBOX
   SG_ CF_Gway_ALightStat : 37|1@1+ (1.0,0.0) [0.0|1.0] ""  AFLS,IBOX,LDWS_LKAS,AFLS,IBOX,LDWS_LKAS
   SG_ CF_Gway_LightSwState : 38|2@1+ (1.0,0.0) [0.0|3.0] ""  AFLS,IBOX,LDWS_LKAS,AFLS,IBOX,LDWS_LKAS
   SG_ CF_Gway_Frt_Fog_Act : 40|1@1+ (1.0,0.0) [0.0|1.0] ""  AFLS,CLU,IBOX,LDWS_LKAS,AFLS,IBOX,LDWS_LKAS
   SG_ CF_Gway_TSigRHSw : 41|1@1+ (1.0,0.0) [0.0|1.0] ""  IBOX,LDWS_LKAS,IBOX,LDWS_LKAS
   SG_ CF_Gway_TSigLHSw : 42|1@1+ (1.0,0.0) [0.0|1.0] ""  IBOX,LDWS_LKAS,IBOX,LDWS_LKAS
   SG_ CF_Gway_DriveTypeOption : 43|1@1+ (1.0,0.0) [0.0|1.0] ""  CLU,IBOX,LDWS_LKAS,IBOX,LDWS_LKAS
   SG_ CF_Gway_StarterRlyState : 44|1@1+ (1.0,0.0) [0.0|1.0] ""  EMS,IBOX,EMS,IBOX,SMK
   SG_ CF_Gway_PassiveAccessLock : 45|2@1+ (1.0,0.0) [0.0|7.0] ""  CLU,ECS,EMS,IBOX,ECS,EMS,IBOX,SMK
   SG_ CF_Gway_WiperMistSw : 47|1@1+ (1.0,0.0) [0.0|1.0] ""  CLU,EMS,IBOX,LDWS_LKAS
   SG_ CF_Gway_PassiveAccessUnlock : 48|2@1+ (1.0,0.0) [0.0|7.0] ""  CLU,ECS,EMS,IBOX,ECS,EMS,IBOX,SMK
   SG_ CF_Gway_RrSunRoofOpenState : 50|1@1+ (1.0,0.0) [0.0|1.0] ""  CLU,DATC,IBOX
   SG_ CF_Gway_PassingSW : 51|1@1+ (1.0,0.0) [0.0|1.0] ""  AFLS,IBOX,LDWS_LKAS,AFLS,IBOX,LDWS_LKAS
   SG_ CF_Gway_HBAControlMode : 52|1@1+ (1.0,0.0) [0.0|1.0] ""  IBOX,LDWS_LKAS,IBOX,LDWS_LKAS
   SG_ CF_Gway_HLpHighSw : 53|1@1+ (1.0,0.0) [0.0|1.0] ""  IBOX,LDWS_LKAS,IBOX,LDWS_LKAS
   SG_ CF_Gway_InhibitRMT : 54|2@1+ (1.0,0.0) [0.0|3.0] ""  EMS,EPB,ESC,IBOX,LCA,LDWS_LKAS,MDPS,PGS,SCC,SPAS,TPMS,EPB,ESC,IBOX,LCA,LDWS_LKAS,PGS,SCC,SPAS,TPMS
   SG_ CF_Gway_RainSnsOption : 56|1@1+ (1.0,0.0) [0.0|1.0] ""  CLU
   SG_ C_SunRoofOpenState : 57|1@1+ (1.0,0.0) [0.0|1.0] ""  CLU,DATC,IBOX,DATC,IBOX
   SG_ CF_Gway_Ign1 : 58|1@1+ (1.0,0.0) [0.0|1.0] ""  CLU
   SG_ CF_Gway_Ign2 : 59|1@1+ (1.0,0.0) [0.0|1.0] ""  CLU
   SG_ CF_Gway_ParkBrakeSw : 60|2@1+ (1.0,0.0) [0.0|3.0] ""  CLU,ESC,IBOX,SCC,ESC,IBOX,SCC
   SG_ CF_Gway_TurnSigRh : 62|2@1+ (1.0,0.0) [0.0|3.0] ""  CLU,EMS,IBOX,LCA,LDWS_LKAS,SCC,EMS,IBOX,LCA,LDWS_LKAS,SCC

BO_ 1345 TMU_HU_P_02: 8 TMU
   SG_ TMU_SupVoiceTextService : 1|2@0+ (1,0) [0|0] ""  H_U
   SG_ TMU_SupEcoCoachService : 3|2@0+ (1,0) [0|0] ""  H_U
   SG_ TMU_SupSongTagService : 5|2@0+ (1,0) [0|0] ""  H_U
   SG_ TMU_SupContentService : 7|2@0+ (1,0) [0|0] ""  H_U
   SG_ TMU_MajorVersion : 15|8@0+ (1,0) [0|0] ""  H_U
   SG_ TMU_MinorVersion : 23|8@0+ (1,0) [0|0] ""  H_U
   SG_ TMU_DistributeInfo : 27|4@0+ (1,0) [0|0] ""  H_U

BO_ 1349 EMS14: 8 EMS
   SG_ IMMO_LAMP_STAT : 0|1@1+ (1.0,0.0) [0.0|1.0] ""  CLU,IBOX
   SG_ L_MIL : 1|1@1+ (1.0,0.0) [0.0|1.0] ""  CLU,CUBIS,IBOX
   SG_ IM_STAT : 2|1@1+ (1.0,0.0) [0.0|1.0] ""  CLU,IBOX
   SG_ AMP_CAN : 3|5@1+ (10.731613,458.98) [458.98|791.660003] "mmHg"  CLU,IBOX,TCU,TPMS
   SG_ BAT_Alt_FR_Duty : 8|8@1+ (0.4,0.0) [0.0|100.0] "%"  CGW,CUBIS,IBOX,TMU
   SG_ VB : 24|8@1+ (0.1015625,0.0) [0.0|25.8984375] "V"  CLU,CUBIS,DATC,EPB,FPCM,IBOX
   SG_ EMS_VS : 32|12@1+ (0.0625,0.0) [0.0|255.875] "km/h"  CLU
   SG_ TEMP_FUEL : 56|8@1+ (0.75,-48.0) [-48.0|143.25] "deg"  FPCM

BO_ 1350 DI_BOX12: 8 DI_BOX
   SG_ CF_DiBox_FrtInjVDiagReg0 : 0|8@1+ (1.0,0.0) [0.0|255.0] ""  EMS
   SG_ CF_DiBox_FrtInjVDiagReg1 : 8|8@1+ (1.0,0.0) [0.0|255.0] ""  EMS
   SG_ CF_DiBox_FrtInjVDiagReg2 : 16|8@1+ (1.0,0.0) [0.0|255.0] ""  EMS
   SG_ CF_DiBox_SedInjVDiagReg0 : 24|8@1+ (1.0,0.0) [0.0|255.0] ""  EMS
   SG_ CF_DiBox_SedInjVDiagReg1 : 32|8@1+ (1.0,0.0) [0.0|255.0] ""  EMS
   SG_ CF_DiBox_SedInjVDiagReg2 : 40|8@1+ (1.0,0.0) [0.0|255.0] ""  EMS
   SG_ CR_DiBox_BatVol : 48|8@1+ (0.1,0.0) [0.0|25.5] "V"  EMS
   SG_ CF_DiBox_SedInjVChg : 56|1@1+ (1.0,0.0) [0.0|1.0] ""  EMS
   SG_ CF_DiBox_FrtInjVChg : 57|1@1+ (1.0,0.0) [0.0|1.0] ""  EMS
   SG_ CF_DiBox_SedInjVErrSPI : 58|1@1+ (1.0,0.0) [0.0|1.0] ""  EMS
   SG_ CF_DiBox_FrtInjVErrSPI : 59|1@1+ (1.0,0.0) [0.0|1.0] ""  EMS

BO_ 1351 EMS15: 8 EMS
   SG_ ECGPOvrd : 0|1@1+ (1.0,0.0) [0.0|1.0] ""  ESC,IBOX,SCC
   SG_ QECACC : 1|1@1+ (1.0,0.0) [0.0|1.0] ""  ESC,IBOX
   SG_ ECFail : 2|1@1+ (1.0,0.0) [0.0|1.0] ""  ESC,IBOX
   SG_ SwitchOffCondExt : 3|1@1+ (1.0,0.0) [0.0|1.0] ""  ESC,IBOX
   SG_ BLECFail : 4|1@1+ (1.0,0.0) [0.0|1.0] ""  ESC,IBOX
   SG_ CF_Ems_IsaAct : 5|1@1+ (1.0,0.0) [0.0|1.0] ""  CLU
   SG_ FA_PV_CAN : 8|8@1+ (0.3906,0.0) [0.0|99.2] "%"  IBOX,LDWS_LKAS,TCU
   SG_ IntAirTemp : 16|8@1+ (0.75,-48.0) [-48.0|143.25] "deg"  _4WD,ECS,EPB,IBOX,TCU
   SG_ STATE_DC_OBD : 24|7@1+ (1.0,0.0) [0.0|127.0] ""  IBOX,TCU
   SG_ INH_DC_OBD : 31|1@1+ (1.0,0.0) [0.0|1.0] ""  IBOX,TCU
   SG_ CTR_IG_CYC_OBD : 32|16@1+ (1.0,0.0) [0.0|65535.0] ""  ACU,IBOX,TCU
   SG_ CTR_CDN_OBD : 48|16@1+ (1.0,0.0) [0.0|65535.0] ""  IBOX,TCU

BO_ 1353 BAT11: 8 EMS
   SG_ BAT_SNSR_I : 0|16@1+ (0.01,-327.0) [-327.0|328.0] "A"  CGW,CUBIS,IBOX,TMU
   SG_ BAT_SOC : 16|8@1+ (1.0,0.0) [0.0|100.0] "%"  CGW,CUBIS,IBOX,TMU
   SG_ BAT_SNSR_V : 24|14@1+ (0.0010,6.0) [6.0|18.0] "V"  CGW,CUBIS,IBOX,TMU
   SG_ BAT_SNSR_Temp : 38|9@1- (0.5,-40.0) [-40.0|125.0] "deg"  CGW,CUBIS,IBOX,TMU
   SG_ BAT_SNSR_State : 47|1@1+ (1.0,0.0) [0.0|1.0] ""  CGW,CUBIS,IBOX,TMU
   SG_ BAT_SOH : 48|7@1+ (1.0,0.0) [0.0|100.0] "%"  CGW,CUBIS,IBOX,TMU
   SG_ BAT_SNSR_Invalid : 55|1@1+ (1.0,0.0) [0.0|1.0] ""  CGW,CUBIS,IBOX,TMU
   SG_ BAT_SOF : 56|7@1+ (0.1,0.0) [0.0|12.0] "V"  CGW,CUBIS,IBOX,TMU
   SG_ BAT_SNSR_Error : 63|1@1+ (1.0,0.0) [0.0|1.0] ""  CGW,CUBIS,IBOX,TMU

BO_ 1356 TCU_DCT14: 8 TCU
   SG_ Vehicle_Stop_Time : 0|5@1+ (1.0,0.0) [0.0|0.0] ""  CLU
   SG_ HILL_HOLD_WARNING : 5|1@1+ (1.0,0.0) [0.0|0.0] ""  CLU

BO_ 1360 IAP11: 3 IAP
   SG_ CF_Iap_EcoPmodSwi : 0|1@1+ (1.0,0.0) [0.0|1.0] ""  CLU
   SG_ CF_Iap_EcoPmodAct : 1|1@1+ (1.0,0.0) [0.0|1.0] ""  CLU
   SG_ CF_Iap_ReqWarn : 2|2@1+ (1.0,0.0) [0.0|3.0] ""  CLU

BO_ 1362 SNV11: 4 SNV
   SG_ CF_SNV_DisplayControl : 0|2@1+ (1.0,0.0) [0.0|3.0] ""  CLU,HUD
   SG_ CF_Snv_BeepWarning : 2|2@1+ (1.0,0.0) [0.0|3.0] ""  CLU,HUD
   SG_ CF_Snv_WarningMessage : 4|3@1+ (1.0,0.0) [0.0|7.0] ""  CLU,HUD
   SG_ CF_Snv_DetectionEnable : 7|1@1+ (1.0,0.0) [0.0|1.0] ""  BCM,CLU,HUD
   SG_ CF_Snv_PedestrianDetect : 8|2@1+ (1.0,0.0) [0.0|3.0] ""  BCM,CLU,HUD
   SG_ CF_Snv_IRLampControl : 10|2@1+ (1.0,0.0) [0.0|3.0] ""  BCM,CLU,HUD

BO_ 1363 CGW2: 8 BCM
   SG_ CF_Gway_GwayDiagState : 0|1@1+ (1.0,0.0) [0.0|3.0] ""  CLU,Dummy
   SG_ CF_Gway_DDMDiagState : 1|1@1+ (1.0,0.0) [0.0|1.0] ""  CLU,Dummy
   SG_ CF_Gway_SCMDiagState : 2|1@1+ (1.0,0.0) [0.0|1.0] ""  CLU,Dummy
   SG_ CF_Gway_PSMDiagState : 3|1@1+ (1.0,0.0) [0.0|1.0] ""  CLU,Dummy
   SG_ CF_Gway_SJBDiagState : 4|1@1+ (1.0,0.0) [0.0|1.0] ""  CLU,Dummy
   SG_ CF_Gway_IPMDiagState : 5|1@1+ (1.0,0.0) [0.0|1.0] ""  CLU,Dummy
   SG_ CF_Gway_LDMFail : 6|2@1+ (1.0,0.0) [0.0|3.0] ""  CLU,LDWS_LKAS,LDWS_LKAS
   SG_ CF_Gway_CLUSwGuiCtrl : 10|3@1+ (1.0,0.0) [0.0|63.0] ""  CLU,Dummy
   SG_ CF_Gway_CLUSwGroup : 13|1@1+ (1.0,0.0) [0.0|1.0] ""  CLU,Dummy
   SG_ CF_Gway_CLUSwMode : 14|1@1+ (1.0,0.0) [0.0|1.0] ""  CLU,Dummy
   SG_ CF_Gway_CLUSwEnter : 15|1@1+ (1.0,0.0) [0.0|1.0] ""  CLU,Dummy
   SG_ CF_Gway_AutoLightValue : 16|1@1+ (1.0,0.0) [0.0|1.0] ""  LCA,LCA
   SG_ CF_Gway_BrakeFluidSw : 17|1@1+ (1.0,0.0) [0.0|1.0] ""  CLU,Dummy
   SG_ CF_Gway_DrvSeatBeltInd : 18|2@1+ (1.0,0.0) [0.0|3.0] ""  CLU
   SG_ CF_Gway_AvTail : 20|1@1+ (1.0,0.0) [0.0|3.0] ""  CLU,SNV,SNV
   SG_ CF_Gway_RearFogAct : 21|1@1+ (1.0,0.0) [0.0|1.0] ""  CLU,Dummy
   SG_ CF_Gway_ExtTailAct : 22|1@1+ (1.0,0.0) [0.0|1.0] ""  AVM,CLU,LCA,PGS,SPAS,AVM,LCA,PGS,SPAS
   SG_ CF_Gway_RRDrSw : 23|1@1+ (1.0,0.0) [0.0|1.0] ""  CLU,Dummy
   SG_ CF_Gway_RLDrSw : 24|1@1+ (1.0,0.0) [0.0|1.0] ""  CLU,Dummy
   SG_ CF_Gway_IntTailAct : 25|1@1+ (1.0,0.0) [0.0|1.0] ""  CLU,Dummy
   SG_ CF_Gway_CountryCfg : 26|3@1+ (1.0,0.0) [0.0|7.0] ""  AVM,CLU,PGS,Dummy
   SG_ CF_Gway_WiperParkPosition : 32|1@1+ (1.0,0.0) [0.0|1.0] ""  AFLS,EMS,LDWS_LKAS,AFLS,EMS,LDWS_LKAS
   SG_ CF_Gway_HLLowLHFail : 33|1@1+ (1.0,0.0) [0.0|1.0] ""  LDWS_LKAS,SNV,LDWS_LKAS,SNV
   SG_ CF_Gway_HLLowRHFail : 34|1@1+ (1.0,0.0) [0.0|1.0] ""  LDWS_LKAS,SNV,LDWS_LKAS,SNV
   SG_ CF_Gway_ESCLFailWarn : 35|1@1+ (1.0,0.0) [0.0|1.0] ""  CLU,Dummy
   SG_ CF_Gway_ESCLNotLockedWarn : 36|1@1+ (1.0,0.0) [0.0|1.0] ""  CLU,Dummy
   SG_ CF_Gway_ESCLNotUnlockWarn : 37|1@1+ (1.0,0.0) [0.0|1.0] ""  CLU,Dummy
   SG_ CF_Gway_IDoutWarn : 38|1@1+ (1.0,0.0) [0.0|1.0] ""  CLU,Dummy
   SG_ CF_Gway_ImmoLp : 40|1@1+ (1.0,0.0) [0.0|3.0] ""  CLU,Dummy
   SG_ CF_Gway_BCMRKEID : 41|3@1+ (1.0,0.0) [0.0|7.0] ""  CLU,Dummy
   SG_ CF_Gway_VehicleNotPWarn : 44|1@1+ (1.0,0.0) [0.0|1.0] ""  CLU,Dummy
   SG_ CF_Gway_DeactivationWarn : 45|1@1+ (1.0,0.0) [0.0|1.0] ""  CLU,Dummy
   SG_ CF_Gway_KeyBATDischargeWarn : 46|1@1+ (1.0,0.0) [0.0|1.0] ""  CLU,Dummy
   SG_ CF_Gway_SSBWarn : 47|1@1+ (1.0,0.0) [0.0|1.0] ""  CLU,Dummy
   SG_ CF_Gway_SMKFobID : 48|3@1+ (1.0,0.0) [0.0|7.0] ""  CLU,Dummy
   SG_ CF_Gway_SMKRKECmd : 51|3@1+ (1.0,0.0) [0.0|7.0] ""  CLU,Dummy
   SG_ CF_Gway_AutoLightOption : 54|1@1+ (1.0,0.0) [0.0|1.0] ""  CLU
   SG_ CF_Gway_SJBDeliveryMode : 55|1@1+ (1.0,0.0) [0.0|1.0] ""  CLU,Dummy
   SG_ CF_Gway_KeyoutLp : 56|1@1+ (1.0,0.0) [0.0|1.0] ""  CLU,Dummy
   SG_ CF_Gway_SMKDispWarn : 57|4@1+ (1.0,0.0) [0.0|15.0] ""  CLU,Dummy
   SG_ CF_Gway_WngBuz : 61|3@1+ (1.0,0.0) [0.0|7.0] ""  CLU,Dummy

BO_ 1365 FPCM11: 8 FPCM
   SG_ CR_Fpcm_LPActPre : 0|8@1+ (3.137254902,0.0) [0.0|800.0] "kPa"  EMS
   SG_ CF_Fpcm_LPPumpOverCur : 8|1@1+ (1.0,0.0) [0.0|1.0] ""  EMS
   SG_ CF_Fpcm_PreSnrHi : 9|1@1+ (1.0,0.0) [0.0|1.0] ""  EMS
   SG_ CF_Fpcm_PreSnrDisc : 10|1@1+ (1.0,0.0) [0.0|1.0] ""  EMS
   SG_ CF_Fpcm_PreSnrShort : 11|1@1+ (1.0,0.0) [0.0|1.0] ""  EMS
   SG_ CF_Fpcm_LPPumpDiscShort : 12|1@1+ (1.0,0.0) [0.0|1.0] ""  EMS
   SG_ CF_Fpcm_LP_System_Error : 13|1@1+ (1.0,0.0) [0.0|1.0] ""  EMS
   SG_ CF_Fpcm_PreSnrSigErr : 14|1@1+ (1.0,0.0) [0.0|1.0] ""  EMS
   SG_ CF_Fpcm_LPCtrCirFlt : 15|1@1+ (1.0,0.0) [0.0|1.0] ""  EMS

BO_ 1366 EngFrzFrm11: 8 EMS
   SG_ PID_04h : 0|8@1+ (0.3921568627,0.0) [0.0|100.0] "%"  AAF,TCU
   SG_ PID_05h : 8|8@1+ (1.0,-40.0) [-40.0|215.0] "deg"  AAF,TCU
   SG_ PID_0Ch : 16|16@1+ (0.25,0.0) [0.0|16383.75] "rpm"  AAF,TCU
   SG_ PID_0Dh : 32|8@1+ (1.0,0.0) [0.0|255.0] "km/h"  AAF,TCU
   SG_ PID_11h : 40|8@1+ (0.3921568627,0.0) [0.0|100.0] "%"  AAF,TCU
   SG_ PID_03h : 48|16@1+ (1.0,0.0) [0.0|65535.0] ""  AAF,TCU

BO_ 1367 EngFrzFrm12: 8 EMS
   SG_ PID_06h : 0|8@1+ (0.78125,-100.0) [-100.0|99.22] "%"  AAF,IBOX,TCU
   SG_ PID_07h : 8|8@1+ (0.78125,-100.0) [-100.0|99.22] "%"  AAF,IBOX,TCU
   SG_ PID_08h : 16|8@1+ (0.78125,-100.0) [-100.0|99.22] "%"  AAF,IBOX,TCU
   SG_ PID_09h : 24|8@1+ (0.78125,-100.0) [-100.0|99.22] "%"  AAF,IBOX,TCU
   SG_ PID_0Bh : 32|8@1+ (1.0,0.0) [0.0|255.0] "kPa"  AAF,IBOX,TCU
   SG_ PID_23h : 40|16@1+ (10.0,0.0) [0.0|655350.0] "kPa"  AAF,IBOX,TCU

BO_ 1369 CGW4: 8 BCM
   SG_ CF_Gway_MemoryP1Cmd : 0|1@1+ (1.0,0.0) [0.0|1.0] ""  CLU
   SG_ CF_Gway_MemoryP2Cmd : 1|1@1+ (1.0,0.0) [0.0|1.0] ""  CLU
   SG_ CF_Gway_PBackP1Cmd : 2|1@1+ (1.0,0.0) [0.0|1.0] ""  CLU
   SG_ CF_Gway_PBackP2Cmd : 3|1@1+ (1.0,0.0) [0.0|1.0] ""  CLU
   SG_ CF_Gway_StrgWhlHeatedState : 4|1@1+ (1.0,0.0) [0.0|1.0] ""  CLU
   SG_ CF_Gway_PBackStopCmd : 5|1@1+ (1.0,0.0) [0.0|1.0] ""  CLU,HUD
   SG_ CF_Gway_StaticBendLhAct : 6|1@1+ (1.0,0.0) [0.0|1.0] ""  CLU
   SG_ CF_Gway_StaticBendRhAct : 7|1@1+ (1.0,0.0) [0.0|1.0] ""  CLU
   SG_ CF_Gway_DrvWdwStat : 8|1@1+ (1.0,0.0) [0.0|1.0] ""  CLU
   SG_ CF_Gway_RLWdwState : 9|1@1+ (1.0,0.0) [0.0|1.0] ""  CLU
   SG_ CF_Gway_RRWdwState : 10|1@1+ (1.0,0.0) [0.0|1.0] ""  CLU
   SG_ CF_Gway_AstWdwStat : 11|1@1+ (1.0,0.0) [0.0|1.0] ""  CLU
   SG_ CF_Gway_MemoryEnable : 12|1@1+ (1.0,0.0) [0.0|1.0] ""  CLU
   SG_ CF_Gway_PBACKStopCmd : 13|1@1+ (1.0,0.0) [0.0|1.0] ""  CLU
   SG_ CF_Gway_PBACKStop : 14|1@1+ (1.0,0.0) [0.0|1.0] ""  CLU,HUD
   SG_ CF_Gway_IMSBuzzer : 15|1@1+ (1.0,0.0) [0.0|1.0] ""  CLU
   SG_ CF_Gway_DrvSeatBeltInd : 36|2@1+ (1.0,0.0) [0.0|3.0] ""  CLU,Dummy
   SG_ CF_Gway_AstSeatBeltInd : 38|2@1+ (1.0,0.0) [0.0|3.0] ""  CLU
   SG_ CF_Gway_RCSeatBeltInd : 40|2@1+ (1.0,0.0) [0.0|3.0] ""  CLU
   SG_ CF_Gway_RLSeatBeltInd : 42|2@1+ (1.0,0.0) [0.0|3.0] ""  CLU
   SG_ CF_Gway_RRSeatBeltInd : 44|2@1+ (1.0,0.0) [0.0|3.0] ""  CLU
   SG_ CF_Gway_RrWiperHighSw : 46|1@1+ (1.0,0.0) [0.0|1.0] ""  CLU
   SG_ CF_Gway_RrWiperLowSw : 47|1@1+ (1.0,0.0) [0.0|1.0] ""  CLU

BO_ 1370 HU_AVM_PE_00: 8 CLU
   SG_ HU_AVM_Status : 0|2@1+ (1.0,0.0) [0.0|3.0] ""  AVM,PGS

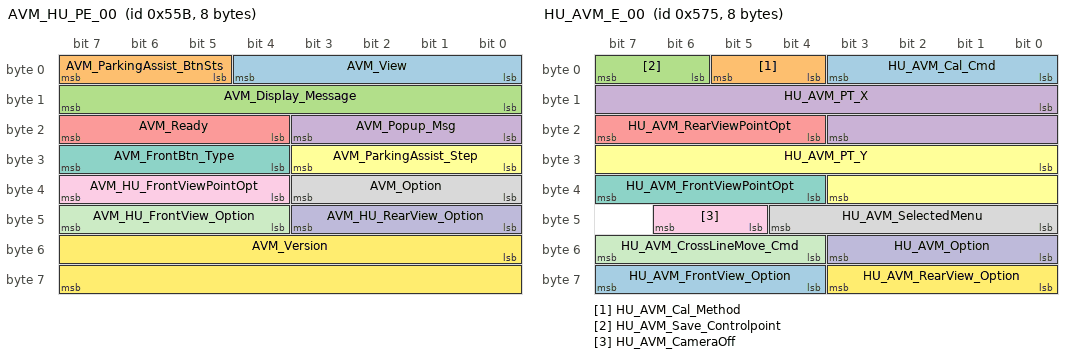
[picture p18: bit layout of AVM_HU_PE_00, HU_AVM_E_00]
BO_ 1371 AVM_HU_PE_00: 8 AVM
   SG_ AVM_View : 0|5@1+ (1.0,0.0) [0.0|31.0] ""  CLU
   SG_ AVM_ParkingAssist_BtnSts : 5|3@1+ (1.0,0.0) [0.0|7.0] ""  CLU
   SG_ AVM_Display_Message : 8|8@1+ (1.0,0.0) [0.0|255.0] ""  CLU
   SG_ AVM_Popup_Msg : 16|4@1+ (1.0,0.0) [0.0|15.0] ""  CLU
   SG_ AVM_Ready : 20|4@1+ (1.0,0.0) [0.0|15.0] ""  CLU
   SG_ AVM_ParkingAssist_Step : 24|4@1+ (1.0,0.0) [0.0|15.0] ""  CLU
   SG_ AVM_FrontBtn_Type : 28|4@1+ (1.0,0.0) [0.0|15.0] ""  CLU
   SG_ AVM_Option : 32|4@1+ (1.0,0.0) [0.0|15.0] ""  CLU
   SG_ AVM_HU_FrontViewPointOpt : 36|4@1+ (1.0,0.0) [0.0|15.0] ""  CLU
   SG_ AVM_HU_RearView_Option : 40|4@1+ (1.0,0.0) [0.0|15.0] ""  CLU
   SG_ AVM_HU_FrontView_Option : 44|4@1+ (1.0,0.0) [0.0|15.0] ""  CLU
   SG_ AVM_Version : 48|16@1+ (1.0,0.0) [0.0|65535.0] ""  CLU

BO_ 1376 HU_TMU_P_02: 8 H_U
   SG_ HU_GPS_Signal2 : 7|8@0+ (2,0) [0|0] "Degree"  TMU
   SG_ HU_GPS_Signal3 : 9|2@0+ (1,0) [0|0] ""  TMU
   SG_ HU_GPS_Signal4 : 12|3@0+ (1,0) [0|0] ""  TMU

BO_ 1378 HUD11: 4 HUD
   SG_ CF_Hud_HeightStaus : 0|5@1+ (1.0,0.0) [0.0|31.0] ""  CLU
   SG_ CF_Hud_PBackStatus : 6|2@1+ (1.0,0.0) [0.0|0.0] ""  BCM,CLU
   SG_ CF_Hud_Brightness : 8|5@1+ (1.0,0.0) [0.0|31.0] ""  CLU

BO_ 1379 PGS_HU_PE_01: 8 PGS
   SG_ PGS_State : 0|4@1+ (1.0,0.0) [0.0|15.0] ""  CLU
   SG_ PGS_ParkGuideState : 8|5@1+ (1.0,0.0) [0.0|31.0] ""  CLU
   SG_ PGS_Option : 16|5@1+ (1.0,0.0) [0.0|31.0] ""  CLU
   SG_ PGS_Version : 32|16@1+ (1.0,0.0) [0.0|65535.0] ""  CLU

BO_ 1390 GW_CLU_P: 8 CLU
   SG_ C_VehicleSpeed : 7|8@0+ (1,0) [0|254] ""  H_U,IBOX
   SG_ C_Odometer : 15|24@0+ (1,0) [0|999999] ""  H_U,IBOX

BO_ 1392 HU_TMU_P_01: 8 H_U
   SG_ HU_GPS_Signal : 7|64@0+ (1,0) [0|0] ""  TMU

BO_ 1393 OPI11: 5 OPI
   SG_ CR_Opi_Spd_Rpm : 0|8@1+ (20.0,0.0) [0.0|3500.0] "rpm"  TCU
   SG_ CF_Opi_Over_Temp : 8|1@1+ (1.0,0.0) [0.0|1.0] ""  TCU
   SG_ CF_Opi_Over_Cur : 9|1@1+ (1.0,0.0) [0.0|1.0] ""  EMS,TCU
   SG_ CF_Opi_Over_Vol : 10|1@1+ (1.0,0.0) [0.0|1.0] ""  TCU
   SG_ CF_Opi_Hall_Fail : 11|1@1+ (1.0,0.0) [0.0|1.0] ""  EMS,TCU
   SG_ CF_Opi_Flt : 12|1@1+ (1.0,0.0) [0.0|1.0] ""  EMS,TCU
   SG_ CF_Opi_Motor_Dir : 15|1@1+ (1.0,0.0) [0.0|1.0] ""  TCU
   SG_ CF_Opi_Romver : 16|8@1+ (1.0,0.0) [0.0|255.0] ""  TCU
   SG_ CF_Opi_PWM_Rate : 24|12@1+ (1.0,0.0) [0.0|100.0] "%"  TCU

BO_ 1395 HU_AVM_E_01: 8 CLU
   SG_ HU_PGSSelectedMenu : 0|4@1+ (1.0,0.0) [0.0|15.0] ""  AVM,PGS
   SG_ HU_PGSOption : 8|5@1+ (1.0,0.0) [0.0|31.0] ""  AVM,PGS
   SG_ HU_AVM_ParkingAssistMenu : 56|4@1+ (1.0,0.0) [0.0|15.0] ""  AVM,PGS
   SG_ HU_AVM_ParkingAssistSB : 60|4@1+ (1.0,0.0) [0.0|15.0] ""  AVM,PGS

BO_ 1397 HU_AVM_E_00: 8 CLU
   SG_ HU_AVM_Cal_Cmd : 0|4@1+ (1.0,0.0) [0.0|15.0] ""  AVM,PGS
   SG_ HU_AVM_Cal_Method : 4|2@1+ (1.0,0.0) [0.0|3.0] ""  AVM,PGS
   SG_ HU_AVM_Save_Controlpoint : 6|2@1+ (1.0,0.0) [0.0|3.0] ""  AVM,PGS
   SG_ HU_AVM_PT_X : 8|12@1+ (1.0,0.0) [0.0|15.0] ""  AVM,PGS
   SG_ HU_AVM_RearViewPointOpt : 20|4@1+ (1.0,0.0) [0.0|15.0] ""  AVM,PGS
   SG_ HU_AVM_PT_Y : 24|12@1+ (1.0,0.0) [0.0|4095.0] ""  AVM,PGS
   SG_ HU_AVM_FrontViewPointOpt : 36|4@1+ (1.0,0.0) [0.0|15.0] ""  AVM,PGS
   SG_ HU_AVM_SelectedMenu : 40|5@1+ (1.0,0.0) [0.0|31.0] ""  AVM,PGS
   SG_ HU_AVM_CameraOff : 45|2@1+ (1.0,0.0) [0.0|3.0] ""  AVM,PGS
   SG_ HU_AVM_Option : 48|4@1+ (1.0,0.0) [0.0|15.0] ""  AVM,PGS
   SG_ HU_AVM_CrossLineMove_Cmd : 52|4@1+ (1.0,0.0) [0.0|15.0] ""  AVM,PGS
   SG_ HU_AVM_RearView_Option : 56|4@1+ (1.0,0.0) [0.0|15.0] ""  AVM,PGS
   SG_ HU_AVM_FrontView_Option : 60|4@1+ (1.0,0.0) [0.0|15.0] ""  AVM,PGS

BO_ 1407 HU_MON_PE_01: 8 CLU
   SG_ HU_Type : 0|8@1+ (1.0,0.0) [0.0|255.0] ""  AVM,PGS

BO_ 1408 AMP_HU_P_01: 8 AMP
   SG_ AMP_SupportMute : 1|2@0+ (1,0) [0|0] ""  H_U
   SG_ AMP_SupportHFMode : 3|2@0+ (1,0) [0|0] ""  H_U
   SG_ AMP_SupportCfgBeep1 : 5|2@0+ (1,0) [0|0] ""  H_U
   SG_ AMP_SupportCfgBeep2 : 7|2@0+ (1,0) [0|0] ""  H_U
   SG_ AMP_SupportSpeedAdjust : 9|2@0+ (1,0) [0|0] ""  H_U
   SG_ AMP_SupportSurroundMode : 11|2@0+ (1,0) [0|0] ""  H_U
   SG_ AMP_SupportNaviMode : 13|2@0+ (1,0) [0|0] ""  H_U
   SG_ AMP_SupportMTSMode : 15|2@0+ (1,0) [0|0] ""  H_U
   SG_ AMP_SupportTopState : 17|2@0+ (1,0) [0|0] ""  H_U
   SG_ AMP_SupportBothLHDandRHD : 19|2@0+ (1,0) [0|0] ""  H_U
   SG_ AMP_SupportEQState : 21|2@0+ (1,0) [0|0] ""  H_U
   SG_ AMP_SupportVehicleID : 23|2@0+ (1,0) [0|0] ""  H_U
   SG_ AMP_SupportAudioSource : 25|2@0+ (1,0) [0|0] ""  H_U
   SG_ AMP_SupportSPDIFModeState : 27|2@0+ (1,0) [0|0] ""  H_U
   SG_ AMP_SupportRearSpMute : 29|2@0+ (1,0) [0|0] ""  H_U
   SG_ AMP_SupportVEQMode : 31|2@0+ (1,0) [0|0] ""  H_U
   SG_ AMP_MakerID : 39|8@0+ (1,0) [0|0] ""  H_U
   SG_ AMP_SupportASDMode : 41|2@0+ (1,0) [0|0] ""  H_U
   SG_ AMP_SupportBeatsMode : 43|2@0+ (1,0) [0|0] ""  H_U
   SG_ AMP_SupportVIPMode : 45|2@0+ (1,0) [0|0] ""  H_U
   SG_ AMP_SupportQLS : 47|2@0+ (1,0) [0|0] ""  H_U
   SG_ AMP_SupportSignalDoctor : 49|2@0+ (1,0) [0|0] ""  H_U
   SG_ AMP_SupportAutoVolume : 51|2@0+ (1,0) [0|0] ""  H_U
   SG_ AMP_SupportPESSMode : 53|2@0+ (1,0) [0|0] ""  H_U

BO_ 1411 CUBIS11: 8 CUBIS
   SG_ CF_Cubis_HUDisp : 0|4@1+ (1.0,0.0) [0.0|15.0] ""  CLU

BO_ 1412 AAF11: 8 AAF
   SG_ CF_Aaf_ActFlapStatus : 0|2@1+ (1.0,0.0) [0.0|3.0] ""  AAF_Tester
   SG_ CF_Aaf_ModeStatus : 2|3@1+ (1.0,0.0) [0.0|7.0] ""  AAF_Tester
   SG_ CF_Aaf_WrnLamp : 5|1@1+ (1.0,0.0) [0.0|1.0] ""  CLU
   SG_ CF_Aaf_ErrStatus : 6|10@1+ (1.0,0.0) [0.0|1023.0] ""  AAF_Tester,EMS
   SG_ CF_Aaf_OpenRqSysAct : 16|8@1+ (1.0,0.0) [0.0|255.0] ""  AAF_Tester
   SG_ CF_Aaf_PStatus : 24|8@1+ (1.0,0.0) [0.0|100.0] "%"  AAF_Tester
   SG_ CF_Aaf_OpenRqSysSol : 32|8@1+ (1.0,0.0) [0.0|255.0] ""  AAF_Tester
   SG_ CF_Aaf_SolFlapStatus : 40|2@1+ (1.0,0.0) [0.0|3.0] ""  AAF_Tester
   SG_ CF_Aaf_MilOnReq : 42|1@1+ (1.0,0.0) [0.0|1.0] ""  EMS

BO_ 1414 EVP11: 3 EVP
   SG_ CF_Evp_Stat : 0|1@1+ (1.0,0.0) [0.0|1.0] ""  CLU

BO_ 1415 TMU11: 8 IBOX
   SG_ CF_Tmu_VehSld : 0|1@1+ (1.0,0.0) [0.0|1.0] ""  EMS
   SG_ CF_Tmu_VehImmo : 1|1@1+ (1.0,0.0) [0.0|1.0] ""  EMS
   SG_ CF_Tmu_ReqRepCnd : 2|2@1+ (1.0,0.0) [0.0|3.0] ""  EMS
   SG_ CF_Tmu_AirconCtr : 4|1@1+ (1.0,0.0) [0.0|1.0] ""  DATC
   SG_ CF_Tmu_TempMd : 5|1@1+ (1.0,0.0) [0.0|1.0] ""  DATC
   SG_ CF_Tmu_TempSet : 6|16@1+ (1.0,0.0) [0.0|20.0] ""  DATC
   SG_ CF_Tmu_DefrostCtr : 22|1@1+ (1.0,0.0) [0.0|1.0] ""  DATC,FATC
   SG_ CF_Tmu_AliveCnt1 : 56|4@1+ (1.0,0.0) [0.0|15.0] ""  EMS

BO_ 1419 LCA11: 8 LCA
   SG_ CF_Lca_Stat : 0|4@1+ (1.0,0.0) [0.0|15.0] ""  BCM,CLU
   SG_ CF_Rcta_Stat : 4|4@1+ (1.0,0.0) [0.0|15.0] ""  BCM,CLU
   SG_ CF_Lca_IndLeft : 8|2@1+ (1.0,0.0) [0.0|3.0] ""  BCM,CLU
   SG_ CF_Rcw_Stat : 10|4@1+ (1.0,0.0) [0.0|15.0] ""  BCM,CLU
   SG_ CF_RCW_Warning : 14|2@1+ (1.0,0.0) [0.0|3.0] ""  BCM,CLU
   SG_ CF_Lca_IndRight : 16|2@1+ (1.0,0.0) [0.0|3.0] ""  BCM,CLU
   SG_ CF_Lca_SndWan_Stat : 18|2@1+ (1.0,0.0) [0.0|3.0] ""  BCM,CLU
   SG_ CF_FR_SndWan : 20|1@1+ (1.0,0.0) [0.0|1.0] ""  BCM,CLU
   SG_ CF_FL_SndWan : 21|1@1+ (1.0,0.0) [0.0|1.0] ""  BCM,CLU
   SG_ CF_RR_SndWan : 22|1@1+ (1.0,0.0) [0.0|1.0] ""  BCM,CLU
   SG_ CF_RL_SndWan : 23|1@1+ (1.0,0.0) [0.0|1.0] ""  BCM,CLU
   SG_ CF_Lca_IndBriLeft : 24|8@1+ (1.0,0.0) [0.0|255.0] ""  BCM,CLU
   SG_ CF_Lca_IndBriRight : 32|8@1+ (1.0,0.0) [0.0|255.0] ""  BCM,CLU
   SG_ CF_RCTA_IndBriLeft : 40|8@1+ (1.0,0.0) [0.0|255.0] ""  BCM,CLU
   SG_ CF_RCTA_IndBriRight : 48|8@1+ (1.0,0.0) [0.0|255.0] ""  BCM,CLU
   SG_ CF_RCTA_IndLeft : 56|2@1+ (1.0,0.0) [0.0|3.0] ""  BCM,CLU
   SG_ CF_RCTA_IndRight : 58|2@1+ (1.0,0.0) [0.0|3.0] ""  BCM,CLU
   SG_ CF_SndWarnForClu : 60|1@1+ (1.0,0.0) [0.0|1.0] ""  CLU

BO_ 1425 AFLS11: 2 AFLS
   SG_ AFLS_STAT : 1|2@1+ (1.0,0.0) [0.0|3.0] ""  CLU
   SG_ CF_Afls_TrfChgStat : 3|1@1+ (1.0,0.0) [0.0|1.0] ""  CLU
   SG_ CF_Afls_LedHLStat : 4|2@1+ (1.0,0.0) [0.0|3.0] ""  CLU

BO_ 1427 TPMS11: 6 BCM
   SG_ TPMS_W_LAMP : 0|2@1+ (1.0,0.0) [0.0|3.0] ""  CLU,CUBIS,HUD,IBOX,CLU,CUBIS,HUD,IBOX
   SG_ TREAD_W_LAMP : 2|2@1+ (1.0,0.0) [0.0|3.0] ""  CLU,CUBIS,HUD,IBOX,CLU,CUBIS,HUD,IBOX
   SG_ POS_FL_W_LAMP : 4|1@1+ (1.0,0.0) [0.0|1.0] ""  CLU,CUBIS,HUD,IBOX
   SG_ POS_FR_W_LAMP : 5|1@1+ (1.0,0.0) [0.0|1.0] ""  CLU,CUBIS,HUD,IBOX
   SG_ POS_RL_W_LAMP : 6|1@1+ (1.0,0.0) [0.0|1.0] ""  CLU,CUBIS,HUD,IBOX
   SG_ POS_RR_W_LAMP : 7|1@1+ (1.0,0.0) [0.0|1.0] ""  CLU,CUBIS,HUD,IBOX
   SG_ STATUS_TPMS : 8|3@1+ (1.0,0.0) [0.0|0.0] ""  CLU
   SG_ UNIT : 11|2@1+ (1.0,0.0) [0.0|3.0] ""  CLU
   SG_ PRESSURE_FL : 16|8@1+ (1.0,0.0) [0.0|255.0] ""  CLU
   SG_ PRESSURE_FR : 24|8@1+ (1.0,0.0) [0.0|255.0] ""  CLU
   SG_ PRESSURE_RL : 32|8@1+ (1.0,0.0) [0.0|255.0] ""  CLU
   SG_ PRESSURE_RR : 40|8@1+ (1.0,0.0) [0.0|255.0] ""  CLU

BO_ 1434 PSB11: 2 PSB
   SG_ PSB_LH_FAIL : 0|2@1+ (1.0,0.0) [0.0|3.0] ""  CLU
   SG_ PSB_LH_TGL : 2|1@1+ (1.0,0.0) [0.0|1.0] ""  CLU
   SG_ PSB_LH_ACT : 3|4@1+ (1.0,0.0) [0.0|4.0] ""  Dummy
   SG_ PSB_RH_FAIL : 8|2@1+ (1.0,0.0) [0.0|3.0] ""  CLU
   SG_ PSB_RH_TGL : 10|1@1+ (1.0,0.0) [0.0|1.0] ""  CLU
   SG_ PSB_RH_ACT : 11|4@1+ (1.0,0.0) [0.0|4.0] ""  Dummy

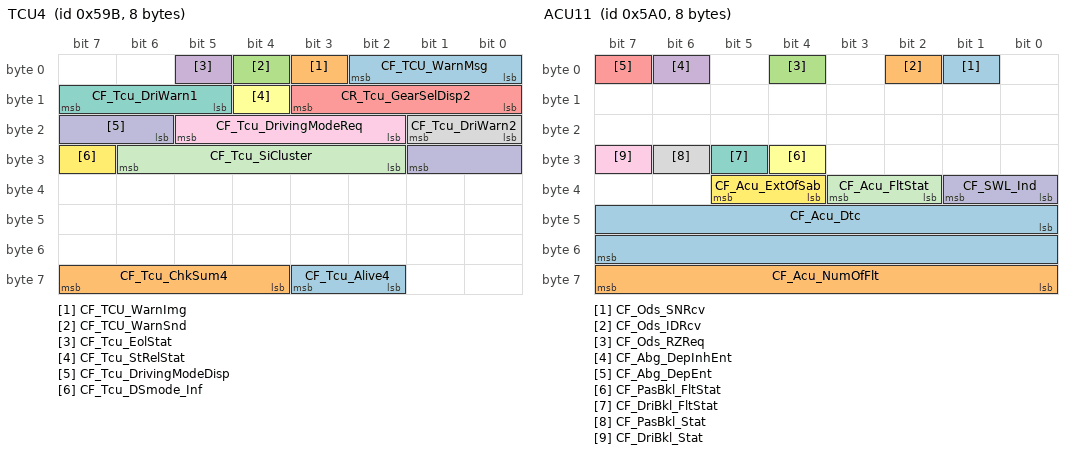
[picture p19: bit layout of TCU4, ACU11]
BO_ 1435 TCU4: 8 XXX
   SG_ CF_TCU_WarnMsg : 0|3@1+ (1,0) [0|7] "" XXX
   SG_ CF_TCU_WarnImg : 3|1@1+ (1,0) [0|1] "" XXX
   SG_ CF_TCU_WarnSnd : 4|1@1+ (1,0) [0|1] "" XXX
   SG_ CF_Tcu_EolStat : 5|1@1+ (1,0) [0|1] "" XXX
   SG_ CR_Tcu_GearSelDisp2 : 8|4@1+ (1,0) [0|15] "" XXX
   SG_ CF_Tcu_StRelStat : 12|1@1+ (1,0) [0|1] "" XXX
   SG_ CF_Tcu_DriWarn1 : 13|3@1+ (1,0) [0|7] "" XXX
   SG_ CF_Tcu_DriWarn2 : 16|2@1+ (1,0) [0|3] "" XXX
   SG_ CF_Tcu_DrivingModeReq : 18|4@1+ (1,0) [0|0] "" XXX
   SG_ CF_Tcu_DrivingModeDisp : 22|4@1+ (1,0) [0|0] "" XXX
   SG_ CF_Tcu_SiCluster : 26|5@1+ (1,0) [0|0] "" XXX
   SG_ CF_Tcu_DSmode_Inf : 31|1@1+ (1,0) [0|1] "" XXX
   SG_ CF_Tcu_Alive4 : 58|2@1+ (1,0) [0|3] "" XXX
   SG_ CF_Tcu_ChkSum4 : 60|4@1+ (1,0) [0|15] "" XXX

BO_ 1437 AHLS11: 8 AHLS
   SG_ CF_Ahls_WarnLamp : 0|2@1+ (1.0,0.0) [0.0|3.0] ""  CLU
   SG_ CF_Ahls_WarnMsg : 2|2@1+ (1.0,0.0) [0.0|3.0] ""  CLU

BO_ 1440 ACU11: 8 ACU
   SG_ CF_Ods_SNRcv : 1|1@1+ (1.0,0.0) [0.0|1.0] ""  ODS
   SG_ CF_Ods_IDRcv : 2|1@1+ (1.0,0.0) [0.0|1.0] ""  ODS
   SG_ CF_Ods_RZReq : 4|1@1+ (1.0,0.0) [0.0|1.0] ""  ODS
   SG_ CF_Abg_DepInhEnt : 6|1@1+ (1.0,0.0) [0.0|1.0] ""  ODS
   SG_ CF_Abg_DepEnt : 7|1@1+ (1.0,0.0) [0.0|1.0] ""  ODS
   SG_ CF_PasBkl_FltStat : 28|1@1+ (1.0,0.0) [0.0|1.0] ""  ODS,PSB
   SG_ CF_DriBkl_FltStat : 29|1@1+ (1.0,0.0) [0.0|1.0] ""  ODS,PSB
   SG_ CF_PasBkl_Stat : 30|1@1+ (1.0,0.0) [0.0|1.0] ""  IBOX,ODS,PSB,TMU
   SG_ CF_DriBkl_Stat : 31|1@1+ (1.0,0.0) [0.0|1.0] ""  ODS,PSB
   SG_ CF_SWL_Ind : 32|2@1+ (1.0,0.0) [0.0|3.0] ""  CUBIS,IBOX
   SG_ CF_Acu_FltStat : 34|2@1+ (1.0,0.0) [0.0|3.0] ""  CUBIS,IBOX
   SG_ CF_Acu_ExtOfSab : 36|2@1+ (1.0,0.0) [0.0|3.0] ""  BCM,CLU,CUBIS,IBOX
   SG_ CF_Acu_Dtc : 40|16@1+ (1.0,0.0) [0.0|65535.0] ""  CUBIS,IBOX
   SG_ CF_Acu_NumOfFlt : 56|8@1+ (1.0,0.0) [0.0|255.0] ""  CUBIS,IBOX

BO_ 1441 ACU12: 8 ACU
   SG_ CR_Acu_SN : 0|64@1+ (1.0,0.0) [0.0|0.0] ""  ODS

BO_ 1456 CLU12: 4 CLU
   SG_ CF_Clu_Odometer : 0|24@1+ (0.1,0.0) [0.0|1677721.4] "km"  _4WD,AAF,BCM,CUBIS,EMS,EPB,IBOX,LDWS_LKAS,SCC,TPMS

BO_ 1472 GW_Warning_PE: 8 BCM
   SG_ Audio_VolumeDown : 38|2@1+ (1.0,0.0) [0.0|3.0] ""  CLU
   SG_ Pas_Spkr_Flh_Alarm : 48|2@1+ (1.0,0.0) [0.0|3.0] ""  CLU
   SG_ Pas_Spkr_Fcnt_Alarm : 50|2@1+ (1.0,0.0) [0.0|3.0] ""  CLU
   SG_ Pas_Spkr_Frh_Alarm : 52|2@1+ (1.0,0.0) [0.0|3.0] ""  CLU
   SG_ Pas_Spkr_Rlh_Alarm : 56|2@1+ (1.0,0.0) [0.0|3.0] ""  CLU,PGS
   SG_ Pas_Spkr_Rcnt_Alarm : 58|2@1+ (1.0,0.0) [0.0|3.0] ""  CLU
   SG_ Pas_Spkr_Rrh_Alarm : 60|2@1+ (1.0,0.0) [0.0|3.0] ""  CLU,PGS

BO_ 1479 EMS21: 8 EMS
   SG_ SCR_LEVEL_WARN_LAMP : 0|1@1+ (1.0,0.0) [0.0|1.0] ""  CLU
   SG_ SCR_LEVEL_WARN : 1|3@1+ (1.0,0.0) [0.0|4.0] ""  CLU
   SG_ SCR_SYS_ERROR_WARN : 4|3@1+ (1.0,0.0) [0.0|7.0] ""  CLU
   SG_ SCR_SYSTEM_WARN_LAMP : 7|1@1+ (1.0,0.0) [0.0|1.0] ""  CLU
   SG_ SCR_INDUCEMENT_EXIT_COND : 8|2@1+ (1.0,0.0) [0.0|3.0] ""  CLU
   SG_ SCR_UREA_LEVEL : 16|8@1+ (0.5,0.0) [0.0|100.0] "%"  CLU
   SG_ SCR_NO_REMAINING_RESTARTS : 24|8@1+ (1.0,0.0) [0.0|255.0] ""  CLU
   SG_ SCR_REMAINING_DISTANCE : 32|16@1+ (1.0,0.0) [0.0|25000.0] "km"  CLU

BO_ 1488 CLU_HU_P_00: 8 CLU
   SG_ MM_CR_Mcu_VehSpd_Kph : 7|8@0+ (1,0) [0|0] ""  H_U
   SG_ MM_CR_Mcu_VehSpdDec_Kph : 15|8@0+ (1,0) [0|0] ""  H_U
   SG_ MM_CR_Bms_Soc_Pc : 23|8@0+ (1,0) [0|0] ""  H_U
   SG_ MM_CR_Vcu_TqMotClu_Pc : 31|8@0+ (1,-127) [0|0] ""  H_U
   SG_ MM_CR_Bms_DrvEnaDist : 39|8@0+ (1,0) [0|0] ""  H_U
   SG_ MM_CR_Clu_Soc_Seg : 44|5@0+ (1,0) [0|0] ""  H_U,IBOX

BO_ 1489 DATC_P_B_01: 8 CLU
   SG_ C_InhibitR_DATC : 51|1@0+ (1,0) [0|0] "" Vector__XXX
   SG_ C_InhibitP_DATC : 50|1@0+ (1,0) [0|0] "" Vector__XXX
   SG_ C_InhibitN_DATC : 49|1@0+ (1,0) [0|0] "" Vector__XXX
   SG_ C_InhibitD_DATC : 48|1@0+ (1,0) [0|0] "" Vector__XXX

BO_ 1490 CLU_HU_P_02: 8 CLU
   SG_ MM_CR_Vcu_EcoSco : 3|4@0+ (1,0) [0|0] ""  H_U
   SG_ MM_CF_Vcu_PgmRun5 : 5|2@0+ (1,0) [0|0] ""  H_U
   SG_ MM_CR_Clu_Odometer_kph : 15|24@0+ (0.1,0) [0|0] "km"  H_U

BO_ 1490 HU_DATC_E_02: 8 CLU
   SG_ HU_DATC_RearOnOffSet : 6|2@1+ (1.0,0.0) [0.0|3.0] ""  DATC
   SG_ HU_DATC_ADSOnOffSet : 8|2@1+ (1.0,0.0) [0.0|3.0] ""  DATC

BO_ 1491 CLU_HU_P_03: 8 CLU
   SG_ MM_CF_Vcu_EvMod : 3|4@0+ (1,0) [0|0] ""  H_U
   SG_ MM_CF_Vcu_GarSelDisp : 7|4@0+ (999,0) [0|0] ""  H_U
   SG_ MM_CF_Vcu_ThiBatTir : 8|1@0+ (1,0) [0|0] ""  H_U
   SG_ CR_Mcu_MotEstTqPc : 23|10@0+ (0.2,-100) [-100|99.8] "%"  H_U
   SG_ CR_Mcu_MotActRotSpd_rpm : 39|16@0+ (1,-32768) [-32768|32767] "rpm"  H_U

BO_ 1492 CLU_HU_P_04: 8 CLU
   SG_ MM_CR_Fatc_AcnComCst_W : 7|10@0+ (10,0) [0|8000] "W"  H_U
   SG_ MM_CR_Ldc_PwrMon_W : 12|8@0+ (10,0) [0|2550] "W"  H_U
   SG_ MM_CR_Fatc_PTCPwrCon_W : 17|10@0+ (10,0) [0|10000] "W"  H_U
   SG_ MM_CR_BmsChgExp_T_Fast : 39|16@0+ (1,0) [0|0] "minute"  H_U
   SG_ MM_CR_BmsChgExp_T_Slow : 55|16@0+ (1,0) [0|0] "minute"  H_U

BO_ 1494 CLU_HU_P_01: 8 CLU
   SG_ CF_TripUnit : 13|2@0+ (1,0) [0|0] ""  H_U
   SG_ CF_DTE : 7|10@0+ (1,0) [0|0] ""  H_U

BO_ 1495 CLU_HU_P_05: 8 CLU
   SG_ Clu_TripUnit : 9|2@0+ (1,0) [0|0] ""  H_U,IBOX
   SG_ Clu_DTEWarn : 11|2@0+ (1,0) [0|0] ""  H_U,IBOX
   SG_ Clu_DTE : 7|12@0+ (1,0) [0|1500] "km"  H_U,IBOX
   SG_ Clu_AFC : 23|10@0+ (0.1,0) [0|99.9] ""  H_U,IBOX
   SG_ Clu_IFC : 29|10@0+ (0.1,0) [0|99.9] ""  H_U,IBOX
   SG_ Clu_Odometer : 47|24@0+ (1,0) [0|999999] ""  H_U,IBOX

BO_ 1508 MDPS1: 8 XXX
   SG_ CF_Mdps_WLmp : 1|2@1+ (1,0) [0|3] "" XXX
   SG_ CF_Mdps_ALTRequest : 5|1@1+ (1,0) [0|1] "" XXX
   SG_ CF_Mdps_Flex : 8|3@1+ (1,0) [0|7] "" XXX
   SG_ CF_Mdps_FlexDisp : 11|1@1+ (1,0) [0|1] "" XXX
   SG_ CF_Mdps_CurrMode : 12|2@1+ (1,0) [0|3] "" XXX

BO_ 1530 ODS11: 8 ODS
   SG_ CF_Ods_PrcCmd : 1|1@1+ (1.0,0.0) [0.0|1.0] ""  Dummy
   SG_ CF_Ods_BtsFail : 3|1@1+ (1.0,0.0) [0.0|1.0] ""  Dummy
   SG_ CF_Ods_AcuRcvSN : 4|1@1+ (1.0,0.0) [0.0|1.0] ""  ACU
   SG_ CF_Ods_EolCal : 5|1@1+ (1.0,0.0) [0.0|1.0] ""  ACU
   SG_ CF_Ods_PsFail : 6|1@1+ (1.0,0.0) [0.0|1.0] ""  ACU
   SG_ CF_Ods_EcuFail : 7|1@1+ (1.0,0.0) [0.0|1.0] ""  ACU
   SG_ CF_Ods_WgtStat : 8|1@1+ (1.0,0.0) [0.0|1.0] ""  ACU
   SG_ CF_Ods_OccStat : 16|1@1+ (1.0,0.0) [0.0|1.0] ""  ACU
   SG_ CR_Wcs_ErrStat : 32|8@1+ (1.0,0.0) [0.0|63.0] ""  ACU
   SG_ CR_Wcs_ClassStat : 40|8@1+ (1.0,0.0) [0.0|4.0] ""  ACU,BCM

BO_ 1531 ODS12: 8 ODS
   SG_ CR_Ods_SerNum0 : 0|8@1+ (1.0,0.0) [0.0|255.0] ""  ACU
   SG_ CR_Ods_SerNum1 : 8|8@1+ (1.0,0.0) [0.0|255.0] ""  ACU
   SG_ CR_Ods_SerNum2 : 16|8@1+ (1.0,0.0) [0.0|255.0] ""  ACU
   SG_ CR_Ods_SerNum3 : 24|8@1+ (1.0,0.0) [0.0|255.0] ""  ACU
   SG_ CR_Ods_SerNum4 : 32|8@1+ (1.0,0.0) [0.0|255.0] ""  ACU
   SG_ CR_Ods_SerNum5 : 40|8@1+ (1.0,0.0) [0.0|255.0] ""  ACU
   SG_ CR_Ods_SerNum6 : 48|8@1+ (1.0,0.0) [0.0|255.0] ""  ACU
   SG_ CR_Ods_SerNum7 : 56|8@1+ (1.0,0.0) [0.0|255.0] ""  ACU

BO_ 1532 ODS13: 5 ODS
   SG_ CR_Ods_ID : 0|8@1+ (1.0,0.0) [0.0|255.0] ""  ACU
   SG_ CR_Ods_Chksum_H : 8|8@1+ (1.0,0.0) [0.0|255.0] ""  Dummy
   SG_ CR_Ods_Chksum_L : 16|8@1+ (1.0,0.0) [0.0|255.0] ""  Dummy
   SG_ CR_Ods_RomID_H : 24|8@1+ (1.0,0.0) [0.0|255.0] ""  Dummy
   SG_ CR_Ods_RomID_L : 32|8@1+ (1.0,0.0) [0.0|255.0] ""  Dummy

BO_ 1680 CLU2: 8 XXX
   SG_ CF_Clu_IGNSw : 0|3@1+ (1,0) [0|7] "" XXX
   SG_ RKE_CMD : 3|3@1+ (1,0) [0|7] "" XXX
   SG_ CF_Clu_DrvDrSw : 6|2@1+ (1,0) [0|3] "" XXX
   SG_ CF_Clu_DrvKeyLockSw : 8|1@1+ (1,0) [0|1] "" XXX
   SG_ CF_Clu_DrvKeyUnlockSw : 9|1@1+ (1,0) [0|1] "" XXX
   SG_ PIC_Lock : 10|3@1+ (1,0) [0|7] "" XXX
   SG_ PIC_Unlock : 13|3@1+ (1,0) [0|7] "" XXX
   SG_ CF_Clu_DrvSeatBeltSw : 16|2@1+ (1,0) [0|3] "" XXX
   SG_ CF_Clu_TrunkTgSw : 18|2@1+ (1,0) [0|3] "" XXX
   SG_ CF_Clu_AstSeatBeltSw : 20|2@1+ (1,0) [0|3] "" XXX
   SG_ CF_Clu_HoodSw : 22|2@1+ (1,0) [0|3] "" XXX
   SG_ CF_Clu_TurnSigLh : 24|1@1+ (1,0) [0|1] "" XXX
   SG_ CF_Clu_TurnSigRh : 25|1@1+ (1,0) [0|1] "" XXX
   SG_ CF_Clu_LdwsLkasSW : 26|1@1+ (1,0) [0|1] "" XXX
   SG_ CF_Clu_WiperIntT : 27|3@1+ (1,0) [0|7] "" XXX
   SG_ CF_Clu_WiperIntSW : 30|1@1+ (1,0) [0|1] "" XXX
   SG_ CF_Clu_WiperLow : 31|1@1+ (1,0) [0|1] "" XXX
   SG_ CF_Clu_WiperHigh : 32|1@1+ (1,0) [0|1] "" XXX
   SG_ CF_Clu_WiperAuto : 33|1@1+ (1,0) [0|1] "" XXX
   SG_ CF_Clu_RainSnsStat : 34|3@1+ (1,0) [0|7] "" XXX
   SG_ CF_Clu_HeadLampLow : 37|1@1+ (1,0) [0|1] "" XXX
   SG_ CF_Clu_HeadLampHigh : 38|1@1+ (1,0) [0|1] "" XXX
   SG_ CF_Clu_AltLStatus : 39|1@1+ (1,0) [0|1] "" XXX
   SG_ CF_Clu_EcoDriveInf : 40|3@1+ (1,0) [0|7] "" XXX
   SG_ CF_Clu_SwiGearR : 43|2@1+ (1,0) [0|3] "" XXX
   SG_ CF_Clu_SWL_Stat : 45|3@1+ (1,0) [0|7] "" XXX
   SG_ CF_Clu_ActiveEcoSW : 48|1@1+ (1,0) [0|1] "" XXX
   SG_ CF_Clu_HazardSW : 49|1@1+ (1,0) [0|1] "" XXX
   SG_ CF_Clu_AliveCnt2 : 50|4@1+ (1,0) [0|15] "" XXX
   SG_ CF_Clu_AstDrSw : 54|2@1+ (1,0) [0|3] "" XXX
   SG_ CF_Clu_LkasDispMode : 56|2@1+ (1,0) [0|3] "" XXX
   SG_ CF_Clu_AutoLightLevel : 58|2@1+ (1,0) [0|3] "" XXX
   SG_ CF_Clu_SunRoofOpenState : 60|1@1+ (1,0) [0|1] "" XXX

BO_ 1864 TP_AMP_EDT: 8 AMP
   SG_ Byte0_TCP_748 : 7|8@0+ (1,0) [0|0] ""  EDT
   SG_ Byte1_Data_748 : 15|8@0+ (1,0) [0|0] ""  EDT
   SG_ Byte2_Data_748 : 23|8@0+ (1,0) [0|0] ""  EDT
   SG_ Byte3_Data_748 : 31|8@0+ (1,0) [0|0] ""  EDT
   SG_ Byte4_Data_748 : 39|8@0+ (1,0) [0|0] ""  EDT
   SG_ Byte5_Data_748 : 47|8@0+ (1,0) [0|0] ""  EDT
   SG_ Byte6_Data_748 : 55|8@0+ (1,0) [0|0] ""  EDT
   SG_ Byte7_Data_748 : 63|8@0+ (1,0) [0|0] ""  EDT

BO_ 1920 TP_HU_PhyReq: 8 EDT
   SG_ Byte0_TCP_780 : 7|8@0+ (1,0) [0|0] ""  H_U
   SG_ Byte1_Data_780 : 15|8@0+ (1,0) [0|0] ""  H_U
   SG_ Byte2_Data_780 : 23|8@0+ (1,0) [0|0] ""  H_U
   SG_ Byte3_Data_780 : 31|8@0+ (1,0) [0|0] ""  H_U
   SG_ Byte4_Data_780 : 39|8@0+ (1,0) [0|0] ""  H_U
   SG_ Byte5_Data_780 : 47|8@0+ (1,0) [0|0] ""  H_U
   SG_ Byte6_Data_780 : 55|8@0+ (1,0) [0|0] ""  H_U
   SG_ Byte7_Data_780 : 63|8@0+ (1,0) [0|0] ""  H_U

BO_ 1928 TP_HU_PhyRes: 8 H_U
   SG_ Byte0_TCP_788 : 7|8@0+ (1,0) [0|0] ""  EDT
   SG_ Byte1_Data_788 : 15|8@0+ (1,0) [0|0] ""  EDT
   SG_ Byte2_Data_788 : 23|8@0+ (1,0) [0|0] ""  EDT
   SG_ Byte3_Data_788 : 31|8@0+ (1,0) [0|0] ""  EDT
   SG_ Byte4_Data_788 : 39|8@0+ (1,0) [0|0] ""  EDT
   SG_ Byte5_Data_788 : 47|8@0+ (1,0) [0|0] ""  EDT
   SG_ Byte6_Data_788 : 55|8@0+ (1,0) [0|0] ""  EDT
   SG_ Byte7_Data_788 : 63|8@0+ (1,0) [0|0] ""  EDT

BO_ 1936 TP_HU_All_Req: 8 H_U
   SG_ Byte0_TCP_790 : 7|8@0+ (1,0) [0|0] ""  AMP,ASD,AVM,CCP,CGW,CLOCK,CLU,CUBIS,DATC,EDT,FHCU,HUD,IBOX,IPM,KBD,KMA_TMU,MON,RRC,RSE_L,RSE_R,SWRC,TMU
   SG_ Byte1_Data_790 : 15|8@0+ (1,0) [0|0] ""  AMP,ASD,AVM,CCP,CGW,CLOCK,CLU,CUBIS,DATC,EDT,FHCU,HUD,IBOX,IPM,KBD,KMA_TMU,MON,RRC,RSE_L,RSE_R,SWRC,TMU
   SG_ Byte2_Data_790 : 23|8@0+ (1,0) [0|0] ""  AMP,ASD,AVM,CCP,CGW,CLOCK,CLU,CUBIS,DATC,EDT,FHCU,HUD,IBOX,IPM,KBD,KMA_TMU,MON,RRC,RSE_L,RSE_R,SWRC,TMU
   SG_ Byte3_Data_790 : 31|8@0+ (1,0) [0|0] ""  AMP,ASD,AVM,CCP,CGW,CLOCK,CLU,CUBIS,DATC,EDT,FHCU,HUD,IBOX,IPM,KBD,KMA_TMU,MON,RRC,RSE_L,RSE_R,SWRC,TMU
   SG_ Byte4_Data_790 : 39|8@0+ (1,0) [0|0] ""  AMP,ASD,AVM,CCP,CGW,CLOCK,CLU,CUBIS,DATC,EDT,FHCU,HUD,IBOX,IPM,KBD,KMA_TMU,MON,RRC,RSE_L,RSE_R,SWRC,TMU
   SG_ Byte5_Data_790 : 47|8@0+ (1,0) [0|0] ""  AMP,ASD,AVM,CCP,CGW,CLOCK,CLU,CUBIS,DATC,EDT,FHCU,HUD,IBOX,IPM,KBD,KMA_TMU,MON,RRC,RSE_L,RSE_R,SWRC,TMU
   SG_ Byte6_Data_790 : 55|8@0+ (1,0) [0|0] ""  AMP,ASD,AVM,CCP,CGW,CLOCK,CLU,CUBIS,DATC,EDT,FHCU,HUD,IBOX,IPM,KBD,KMA_TMU,MON,RRC,RSE_L,RSE_R,SWRC,TMU
   SG_ Byte7_Data_790 : 63|8@0+ (1,0) [0|0] ""  AMP,ASD,AVM,CCP,CGW,CLOCK,CLU,CUBIS,DATC,EDT,FHCU,HUD,IBOX,IPM,KBD,KMA_TMU,MON,RRC,RSE_L,RSE_R,SWRC,TMU

BO_ 1941 TP_HU_AMP_DiagReq: 8 H_U
   SG_ Byte0_TCP_795 : 7|8@0+ (1,0) [0|0] ""  AMP
   SG_ Byte1_Data_795 : 15|8@0+ (1,0) [0|0] ""  AMP
   SG_ Byte2_Data_795 : 23|8@0+ (1,0) [0|0] ""  AMP
   SG_ Byte3_Data_795 : 31|8@0+ (1,0) [0|0] ""  AMP
   SG_ Byte4_Data_795 : 39|8@0+ (1,0) [0|0] ""  AMP
   SG_ Byte5_Data_795 : 47|8@0+ (1,0) [0|0] ""  AMP
   SG_ Byte6_Data_795 : 55|8@0+ (1,0) [0|0] ""  AMP
   SG_ Byte7_Data_795 : 63|8@0+ (1,0) [0|0] ""  AMP

BO_ 1942 TP_AMP_HU_DiagRes: 8 AMP
   SG_ Byte0_TCP_796 : 7|8@0+ (1,0) [0|0] ""  H_U
   SG_ Byte1_Data_796 : 15|8@0+ (1,0) [0|0] ""  H_U
   SG_ Byte2_Data_796 : 23|8@0+ (1,0) [0|0] ""  H_U
   SG_ Byte3_Data_796 : 31|8@0+ (1,0) [0|0] ""  H_U
   SG_ Byte4_Data_796 : 39|8@0+ (1,0) [0|0] ""  H_U
   SG_ Byte5_Data_796 : 47|8@0+ (1,0) [0|0] ""  H_U
   SG_ Byte6_Data_796 : 55|8@0+ (1,0) [0|0] ""  H_U
   SG_ Byte7_Data_796 : 63|8@0+ (1,0) [0|0] ""  H_U

BO_ 1984 CAL_SAS11: 2 ESC
   SG_ CCW : 0|4@1+ (1.0,0.0) [0.0|15.0] ""  SAS
   SG_ SAS_CID : 4|11@1+ (1.0,0.0) [0.0|2047.0] ""  SAS

BO_ 2015 TP_EDT_All_Req: 8 EDT
   SG_ Byte0_TCP_7DF : 7|8@0+ (1,0) [0|0] ""  AMP,ASD,AVM,CCP,CGW,CLOCK,CLU,CUBIS,DATC,FHCU,HUD,H_U,IBOX,IPM,KBD,KMA_TMU,MON,RRC,RSE_L,RSE_R,TMU
   SG_ Byte1_Data_7DF : 15|8@0+ (1,0) [0|0] ""  AMP,ASD,AVM,CCP,CGW,CLOCK,CLU,CUBIS,DATC,FHCU,HUD,H_U,IBOX,IPM,KBD,KMA_TMU,MON,RRC,RSE_L,RSE_R,TMU
   SG_ Byte2_Data_7DF : 23|8@0+ (1,0) [0|0] ""  AMP,ASD,AVM,CCP,CGW,CLOCK,CLU,CUBIS,DATC,FHCU,HUD,H_U,IBOX,IPM,KBD,KMA_TMU,MON,RRC,RSE_L,RSE_R,TMU
   SG_ Byte3_Data_7DF : 31|8@0+ (1,0) [0|0] ""  AMP,ASD,AVM,CCP,CGW,CLOCK,CLU,CUBIS,DATC,FHCU,HUD,H_U,IBOX,IPM,KBD,KMA_TMU,MON,RRC,RSE_L,RSE_R,TMU
   SG_ Byte4_Data_7DF : 39|8@0+ (1,0) [0|0] ""  AMP,ASD,AVM,CCP,CGW,CLOCK,CLU,CUBIS,DATC,FHCU,HUD,H_U,IBOX,IPM,KBD,KMA_TMU,MON,RRC,RSE_L,RSE_R,TMU
   SG_ Byte5_Data_7DF : 47|8@0+ (1,0) [0|0] ""  AMP,ASD,AVM,CCP,CGW,CLOCK,CLU,CUBIS,DATC,FHCU,HUD,H_U,IBOX,IPM,KBD,KMA_TMU,MON,RRC,RSE_L,RSE_R,TMU
   SG_ Byte6_Data_7DF : 55|8@0+ (1,0) [0|0] ""  AMP,ASD,AVM,CCP,CGW,CLOCK,CLU,CUBIS,DATC,FHCU,HUD,H_U,IBOX,IPM,KBD,KMA_TMU,MON,RRC,RSE_L,RSE_R,TMU
   SG_ Byte7_Data_7DF : 63|8@0+ (1,0) [0|0] ""  AMP,ASD,AVM,CCP,CGW,CLOCK,CLU,CUBIS,DATC,FHCU,HUD,H_U,IBOX,IPM,KBD,KMA_TMU,MON,RRC,RSE_L,RSE_R,TMU

BO_ 2046 TP_EDT_AMP: 8 EDT
   SG_ Byte0_TCP_7FE : 7|8@0+ (1,0) [0|0] ""  AMP
   SG_ Byte1_Data_7FE : 15|8@0+ (1,0) [0|0] ""  AMP
   SG_ Byte2_Data_7FE : 23|8@0+ (1,0) [0|0] ""  AMP
   SG_ Byte3_Data_7FE : 31|8@0+ (1,0) [0|0] ""  AMP
   SG_ Byte4_Data_7FE : 39|8@0+ (1,0) [0|0] ""  AMP
   SG_ Byte5_Data_7FE : 47|8@0+ (1,0) [0|0] ""  AMP
   SG_ Byte6_Data_7FE : 55|8@0+ (1,0) [0|0] ""  AMP
   SG_ Byte7_Data_7FE : 63|8@0+ (1,0) [0|0] ""  AMP

BO_ 3221225472 VECTOR__INDEPENDENT_SIG_MSG: 0 Vector__XXX
   SG_ C_WHEEL_FL : 0|12@0+ (1,0) [0|0] "" Vector__XXX
   SG_ C_WHEEL_FR : 0|12@0+ (1,0) [0|0] "" Vector__XXX
   SG_ C_WHEEL_RL : 0|12@0+ (1,0) [0|0] "" Vector__XXX
   SG_ C_WHEEL_RR : 0|12@0+ (1,0) [0|0] "" Vector__XXX
